VERSION ""

NS_ :

BS_:

BU_: PowertrainControlModule AtmosphericSensor SafetyRestraintSystem2 Aftertreatment_2_GasOutlet Aftertreatment_2_GasIntake DieselParticulateFilterControl Turbocharger SafetyRestraintSystem1 CabDisplay2 Aftertreatment_1_GasOutlet Aftertreatment_1_GasIntake OnBoardDataLogger OffBoardDiagnosticTool2 OffBoardDiagnosticTool1 FileServer ParkingBrakeController SeatController2 FanDriveController SteeringColumnUnit CommunicationUnitRadio CommunicationUnitSatellite CommunicationUnitCellular PropulsionBatteryCharger ChassisController2 ChassisController1 EngineValveControl AuxiliaryHeater2 AuxiliaryHeater1 ClutchUnit RampControl InformationSystem1 SuspensionSystemController2 OilSensor VehicleDynamicStability ExhaustEmissionController TransmissionDisplay2 TransmissionDisplay1 ClimateControl2 WaterPumpController RearAxleSteeringController LightingOperatorControl SeatController1 IgnitionController2 IgnitionController1 TirePressureController CabController2 CabController1 PneumaticSystemController SuspensionSystemController1 HydraulicPumpController EnduranceBrakingSystem RetarderExhaustEngine2 OnBoardDiagnosticUnit HeadwayController RetarderExhaustEngine1 CabDisplay1 ManagementComputer VirtualTerminal OffVehicleGateway PowerTakeOffFront HitchControl AuxiliaryValveControl BodyController TractorTrailerBridge1 StarterSystem ElectricalSystem VehicleSecurity VehicleNavigation AerodynamicControl ElectricalChargingSystem ClimateControl1 TripRecorder InstrumentCluster SuspensionDriveAxle2 SuspensionDriveAxle1 SuspensionSteerAxle SteeringController FuelSystem CruiseControl RetarderDriveline RetarderEngine BrakesDriveAxle2 BrakesDriveAxle1 BrakesSystemController BrakesSteerAxle AxleDrive2 AxleDrive1 AxleSteering PowerTakeOff ShiftConsoleSecondary ShiftConsolePrimary Transmission2 Transmission1 Engine2 Engine1

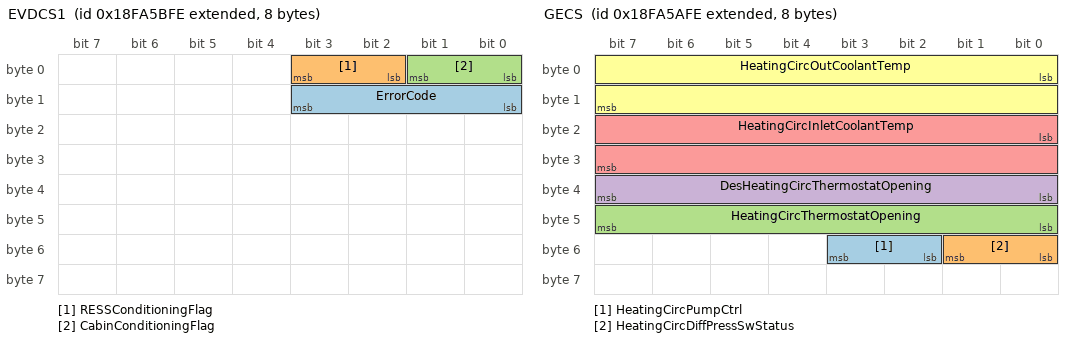
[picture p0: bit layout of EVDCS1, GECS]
BO_ 2566544382 EVDCS1: 8 Vector__XXX
 SG_ ErrorCode : 8|4@1+ (1,0) [0|15] "" Vector__XXX
 SG_ RESSConditioningFlag : 2|2@1+ (1,0) [0|3] "" Vector__XXX
 SG_ CabinConditioningFlag : 0|2@1+ (1,0) [0|3] "" Vector__XXX

BO_ 2566544126 GECS: 8 Vector__XXX
 SG_ HeatingCircPumpCtrl : 50|2@1+ (1,0) [0|3] "" Vector__XXX
 SG_ HeatingCircDiffPressSwStatus : 48|2@1+ (1,0) [0|3] "" Vector__XXX
 SG_ HeatingCircThermostatOpening : 40|8@1+ (0.4,0) [0|100] "%" Vector__XXX
 SG_ DesHeatingCircThermostatOpening : 32|8@1+ (0.4,0) [0|100] "%" Vector__XXX
 SG_ HeatingCircInletCoolantTemp : 16|16@1+ (0.03125,-273) [-273|1734.96875] "°C" Vector__XXX
 SG_ HeatingCircOutCoolantTemp : 0|16@1+ (0.03125,-273) [-273|1734.96875] "°C" Vector__XXX

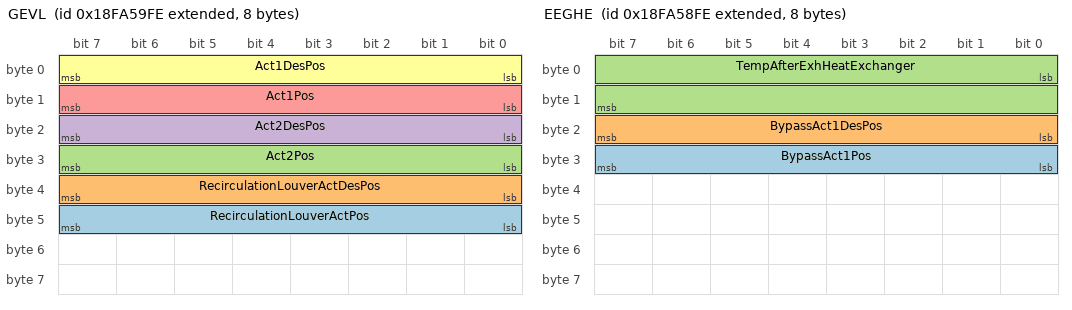
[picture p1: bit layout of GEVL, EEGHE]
BO_ 2566543870 GEVL: 8 Vector__XXX
 SG_ RecirculationLouverActPos : 40|8@1+ (0.4,0) [0|100] "%" Vector__XXX
 SG_ RecirculationLouverActDesPos : 32|8@1+ (0.4,0) [0|100] "%" Vector__XXX
 SG_ Act2Pos : 24|8@1+ (0.4,0) [0|100] "%" Vector__XXX
 SG_ Act2DesPos : 16|8@1+ (0.4,0) [0|100] "%" Vector__XXX
 SG_ Act1Pos : 8|8@1+ (0.4,0) [0|100] "%" Vector__XXX
 SG_ Act1DesPos : 0|8@1+ (0.4,0) [0|100] "%" Vector__XXX

BO_ 2566543614 EEGHE: 8 Vector__XXX
 SG_ BypassAct1Pos : 24|8@1+ (0.4,0) [0|100] "%" Vector__XXX
 SG_ BypassAct1DesPos : 16|8@1+ (0.4,0) [0|100] "%" Vector__XXX
 SG_ TempAfterExhHeatExchanger : 0|16@1+ (0.03125,-273) [-273|1734.96875] "°C" Vector__XXX

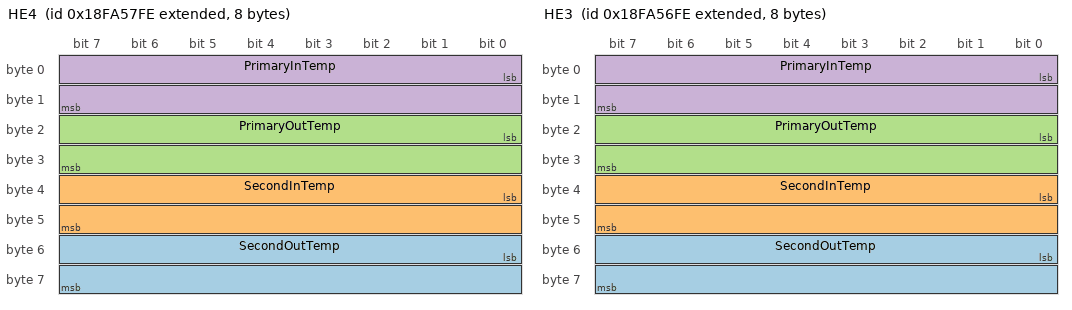
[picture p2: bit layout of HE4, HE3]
BO_ 2566543358 HE4: 8 Vector__XXX
 SG_ SecondOutTemp : 48|16@1+ (0.03125,-273) [-273|1734.96875] "°C" Vector__XXX
 SG_ SecondInTemp : 32|16@1+ (0.03125,-273) [-273|1734.96875] "°C" Vector__XXX
 SG_ PrimaryOutTemp : 16|16@1+ (0.03125,-273) [-273|1734.96875] "°C" Vector__XXX
 SG_ PrimaryInTemp : 0|16@1+ (0.03125,-273) [-273|1734.96875] "°C" Vector__XXX

BO_ 2566543102 HE3: 8 Vector__XXX
 SG_ SecondOutTemp : 48|16@1+ (0.03125,-273) [-273|1734.96875] "°C" Vector__XXX
 SG_ SecondInTemp : 32|16@1+ (0.03125,-273) [-273|1734.96875] "°C" Vector__XXX
 SG_ PrimaryOutTemp : 16|16@1+ (0.03125,-273) [-273|1734.96875] "°C" Vector__XXX
 SG_ PrimaryInTemp : 0|16@1+ (0.03125,-273) [-273|1734.96875] "°C" Vector__XXX

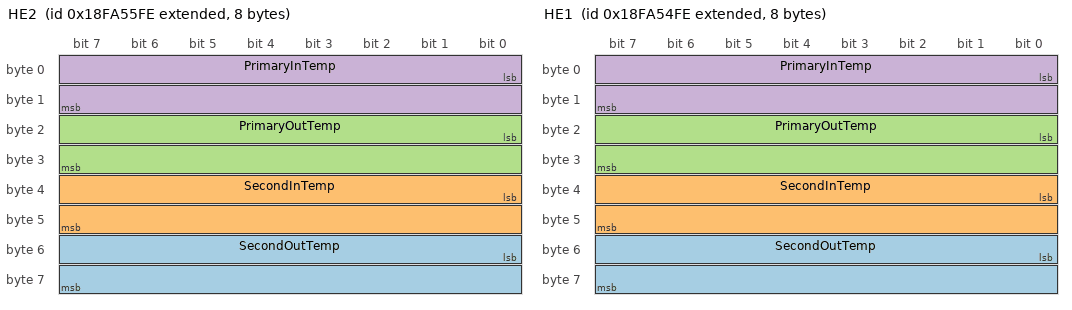
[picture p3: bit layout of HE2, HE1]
BO_ 2566542846 HE2: 8 Vector__XXX
 SG_ SecondOutTemp : 48|16@1+ (0.03125,-273) [-273|1734.96875] "°C" Vector__XXX
 SG_ SecondInTemp : 32|16@1+ (0.03125,-273) [-273|1734.96875] "°C" Vector__XXX
 SG_ PrimaryOutTemp : 16|16@1+ (0.03125,-273) [-273|1734.96875] "°C" Vector__XXX
 SG_ PrimaryInTemp : 0|16@1+ (0.03125,-273) [-273|1734.96875] "°C" Vector__XXX

BO_ 2566542590 HE1: 8 Vector__XXX
 SG_ SecondOutTemp : 48|16@1+ (0.03125,-273) [-273|1734.96875] "°C" Vector__XXX
 SG_ SecondInTemp : 32|16@1+ (0.03125,-273) [-273|1734.96875] "°C" Vector__XXX
 SG_ PrimaryOutTemp : 16|16@1+ (0.03125,-273) [-273|1734.96875] "°C" Vector__XXX
 SG_ PrimaryInTemp : 0|16@1+ (0.03125,-273) [-273|1734.96875] "°C" Vector__XXX

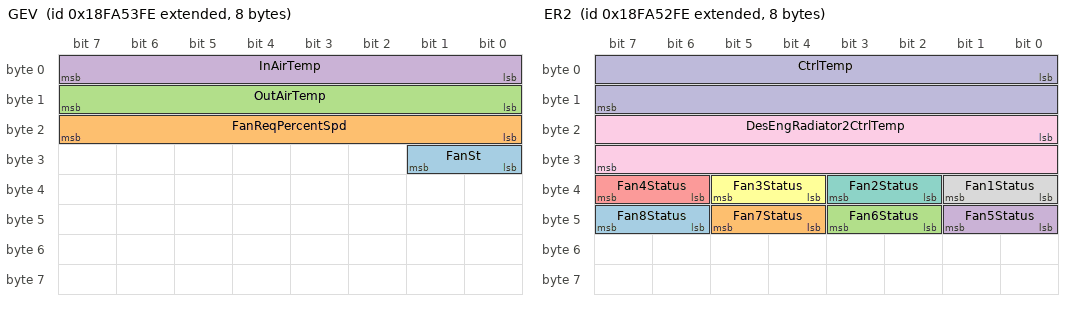
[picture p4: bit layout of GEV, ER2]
BO_ 2566542334 GEV: 8 Vector__XXX
 SG_ FanSt : 24|2@1+ (1,0) [0|3] "" Vector__XXX
 SG_ FanReqPercentSpd : 16|8@1+ (0.4,0) [0|100] "%" Vector__XXX
 SG_ OutAirTemp : 8|8@1+ (1,-40) [-40|210] "°C" Vector__XXX
 SG_ InAirTemp : 0|8@1+ (1,-40) [-40|210] "°C" Vector__XXX

BO_ 2566542078 ER2: 8 Vector__XXX
 SG_ Fan8Status : 46|2@1+ (1,0) [0|3] "" Vector__XXX
 SG_ Fan7Status : 44|2@1+ (1,0) [0|3] "" Vector__XXX
 SG_ Fan6Status : 42|2@1+ (1,0) [0|3] "" Vector__XXX
 SG_ Fan5Status : 40|2@1+ (1,0) [0|3] "" Vector__XXX
 SG_ Fan4Status : 38|2@1+ (1,0) [0|3] "" Vector__XXX
 SG_ Fan3Status : 36|2@1+ (1,0) [0|3] "" Vector__XXX
 SG_ Fan2Status : 34|2@1+ (1,0) [0|3] "" Vector__XXX
 SG_ Fan1Status : 32|2@1+ (1,0) [0|3] "" Vector__XXX
 SG_ DesEngRadiator2CtrlTemp : 16|16@1+ (0.03125,-273) [-273|1734.96875] "°C" Vector__XXX
 SG_ CtrlTemp : 0|16@1+ (0.03125,-273) [-273|1734.96875] "°C" Vector__XXX

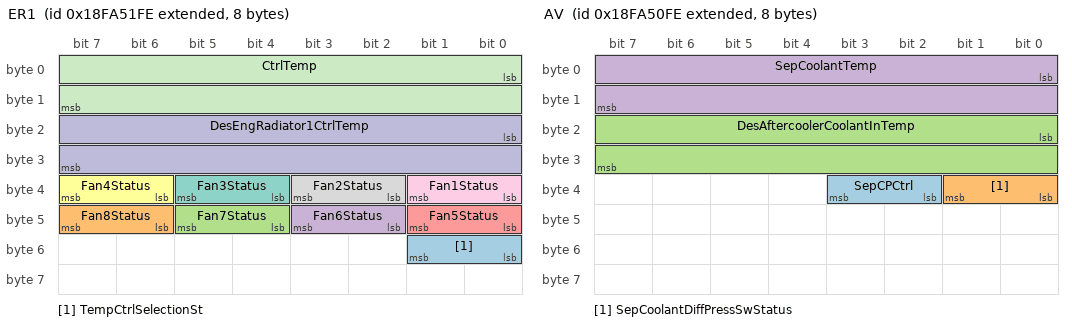
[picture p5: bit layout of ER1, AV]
BO_ 2566541822 ER1: 8 Vector__XXX
 SG_ TempCtrlSelectionSt : 48|2@1+ (1,0) [0|3] "" Vector__XXX
 SG_ Fan8Status : 46|2@1+ (1,0) [0|3] "" Vector__XXX
 SG_ Fan7Status : 44|2@1+ (1,0) [0|3] "" Vector__XXX
 SG_ Fan6Status : 42|2@1+ (1,0) [0|3] "" Vector__XXX
 SG_ Fan5Status : 40|2@1+ (1,0) [0|3] "" Vector__XXX
 SG_ Fan4Status : 38|2@1+ (1,0) [0|3] "" Vector__XXX
 SG_ Fan3Status : 36|2@1+ (1,0) [0|3] "" Vector__XXX
 SG_ Fan2Status : 34|2@1+ (1,0) [0|3] "" Vector__XXX
 SG_ Fan1Status : 32|2@1+ (1,0) [0|3] "" Vector__XXX
 SG_ DesEngRadiator1CtrlTemp : 16|16@1+ (0.03125,-273) [-273|1734.96875] "°C" Vector__XXX
 SG_ CtrlTemp : 0|16@1+ (0.03125,-273) [-273|1734.96875] "°C" Vector__XXX

BO_ 2566541566 AV: 8 Vector__XXX
 SG_ SepCPCtrl : 34|2@1+ (1,0) [0|3] "" Vector__XXX
 SG_ SepCoolantDiffPressSwStatus : 32|2@1+ (1,0) [0|3] "" Vector__XXX
 SG_ DesAftercoolerCoolantInTemp : 16|16@1+ (0.03125,-273) [-273|1734.96875] "°C" Vector__XXX
 SG_ SepCoolantTemp : 0|16@1+ (0.03125,-273) [-273|1734.96875] "°C" Vector__XXX

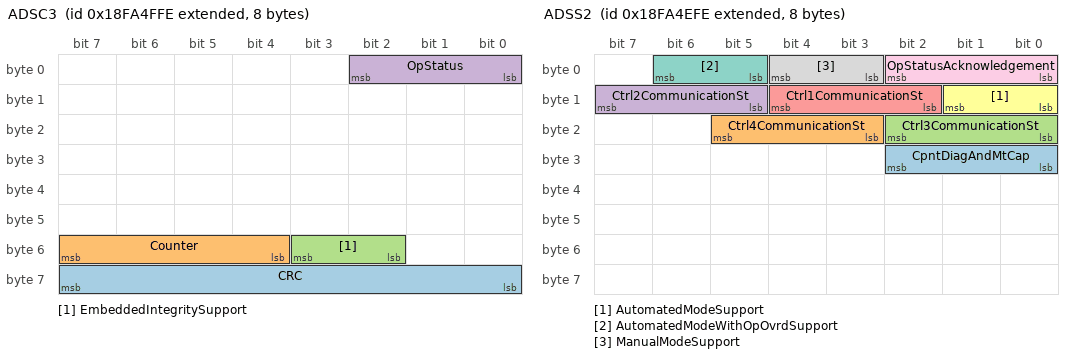
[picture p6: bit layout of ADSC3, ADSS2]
BO_ 2566541310 ADSC3: 8 Vector__XXX
 SG_ CRC : 56|8@1+ (1,0) [0|255] "" Vector__XXX
 SG_ Counter : 52|4@1+ (1,0) [0|15] "" Vector__XXX
 SG_ EmbeddedIntegritySupport : 50|2@1+ (1,0) [0|3] "" Vector__XXX
 SG_ OpStatus : 0|3@1+ (1,0) [0|7] "" Vector__XXX

BO_ 2566541054 ADSS2: 8 Vector__XXX
 SG_ CpntDiagAndMtCap : 24|3@1+ (1,0) [0|7] "" Vector__XXX
 SG_ Ctrl4CommunicationSt : 19|3@1+ (1,0) [0|7] "" Vector__XXX
 SG_ Ctrl3CommunicationSt : 16|3@1+ (1,0) [0|7] "" Vector__XXX
 SG_ Ctrl2CommunicationSt : 13|3@1+ (1,0) [0|7] "" Vector__XXX
 SG_ Ctrl1CommunicationSt : 10|3@1+ (1,0) [0|7] "" Vector__XXX
 SG_ AutomatedModeSupport : 8|2@1+ (1,0) [0|3] "" Vector__XXX
 SG_ AutomatedModeWithOpOvrdSupport : 5|2@1+ (1,0) [0|3] "" Vector__XXX
 SG_ ManualModeSupport : 3|2@1+ (1,0) [0|3] "" Vector__XXX
 SG_ OpStatusAcknowledgement : 0|3@1+ (1,0) [0|7] "" Vector__XXX

BO_ 2566540798 EVEI: 8 Vector__XXX
 SG_ TripDriveEnergyEconomy : 32|16@1+ (0.001953125,0) [0|125.498046875] "kWh/km" Vector__XXX
 SG_ TotalTripEnergyConsumed : 0|32@1+ (0.1,0) [0|421108121.5] "kWh" Vector__XXX

BO_ 2566540542 A1SCRDSI5: 8 Vector__XXX
 SG_ DEFDoser3Press : 16|16@1+ (0.1,-100) [-100|6325.5] "kPa" Vector__XXX
 SG_ DEFDoser2Press : 0|16@1+ (0.1,-100) [-100|6325.5] "kPa" Vector__XXX

BO_ 2566540286 A2SCRDSI5: 8 Vector__XXX
 SG_ DEFDoser3Press : 16|16@1+ (0.1,-100) [-100|6325.5] "kPa" Vector__XXX
 SG_ DEFDoser2Press : 0|16@1+ (0.1,-100) [-100|6325.5] "kPa" Vector__XXX

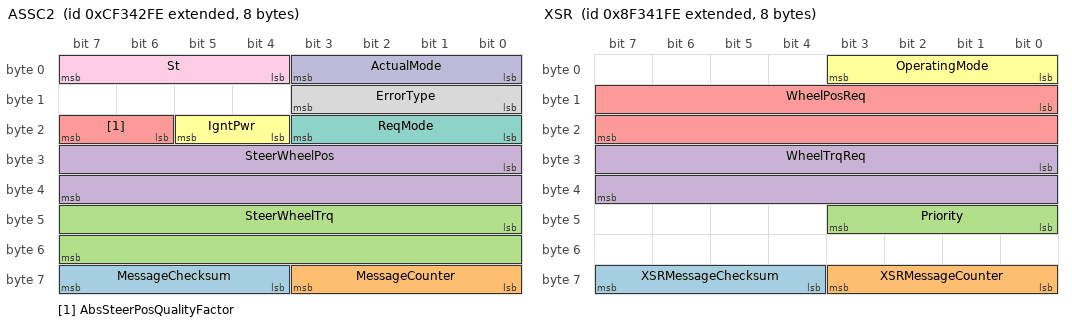
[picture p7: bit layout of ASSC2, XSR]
BO_ 2364752638 ASSC2: 8 Vector__XXX
 SG_ MessageChecksum : 60|4@1+ (1,0) [0|15] "" Vector__XXX
 SG_ MessageCounter : 56|4@1+ (1,0) [0|15] "" Vector__XXX
 SG_ SteerWheelTrq : 40|16@1+ (0.0009765625,-31) [-31|31.7490234375] "Nm" Vector__XXX
 SG_ SteerWheelPos : 24|16@1+ (0.0625,-2008) [-2008|2007.9375] "deg" Vector__XXX
 SG_ AbsSteerPosQualityFactor : 22|2@1+ (1,0) [0|3] "" Vector__XXX
 SG_ IgntPwr : 20|2@1+ (1,0) [0|3] "" Vector__XXX
 SG_ ReqMode : 16|4@1+ (1,0) [0|15] "" Vector__XXX
 SG_ ErrorType : 8|4@1+ (1,0) [0|15] "" Vector__XXX
 SG_ St : 4|4@1+ (1,0) [0|15] "" Vector__XXX
 SG_ ActualMode : 0|4@1+ (1,0) [0|15] "" Vector__XXX

BO_ 2297643518 XSR: 8 Vector__XXX
 SG_ XSRMessageChecksum : 60|4@1+ (1,0) [0|15] "" Vector__XXX
 SG_ XSRMessageCounter : 56|4@1+ (1,0) [0|15] "" Vector__XXX
 SG_ Priority : 40|4@1+ (1,0) [0|15] "" Vector__XXX
 SG_ WheelTrqReq : 24|16@1+ (0.0009765625,-31) [-31|31.7490234375] "Nm" Vector__XXX
 SG_ WheelPosReq : 8|16@1+ (0.0625,-2008) [-2008|2007.9375] "deg" Vector__XXX
 SG_ OperatingMode : 0|4@1+ (1,0) [0|15] "" Vector__XXX

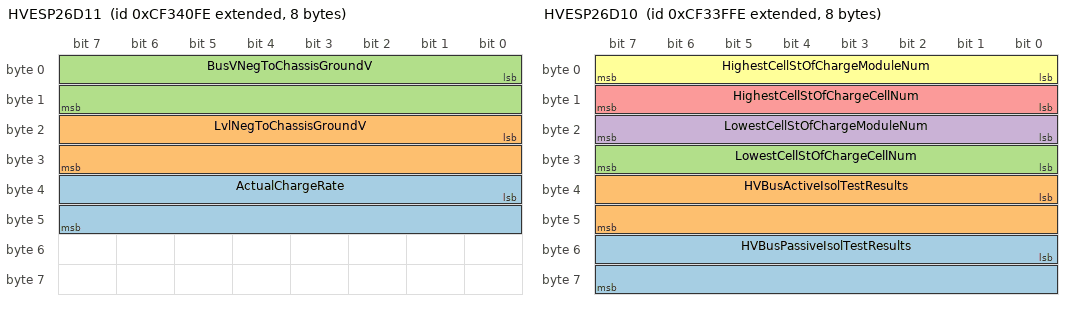
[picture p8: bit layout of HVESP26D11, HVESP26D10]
BO_ 2364752126 HVESP26D11: 8 Vector__XXX
 SG_ ActualChargeRate : 32|16@1+ (0.05,0) [0|3212.75] "kW" Vector__XXX
 SG_ LvlNegToChassisGroundV : 16|16@1+ (0.05,0) [0|3212.75] "V" Vector__XXX
 SG_ BusVNegToChassisGroundV : 0|16@1+ (0.05,0) [0|3212.75] "V" Vector__XXX

BO_ 2364751870 HVESP26D10: 8 Vector__XXX
 SG_ HVBusPassiveIsolTestResults : 48|16@1+ (0.1,0) [0|6425.5] "Ohm/V" Vector__XXX
 SG_ HVBusActiveIsolTestResults : 32|16@1+ (0.1,0) [0|6425.5] "Ohm/V" Vector__XXX
 SG_ LowestCellStOfChargeCellNum : 24|8@1+ (1,0) [0|250] "" Vector__XXX
 SG_ LowestCellStOfChargeModuleNum : 16|8@1+ (1,0) [0|250] "" Vector__XXX
 SG_ HighestCellStOfChargeCellNum : 8|8@1+ (1,0) [0|250] "" Vector__XXX
 SG_ HighestCellStOfChargeModuleNum : 0|8@1+ (1,0) [0|250] "" Vector__XXX

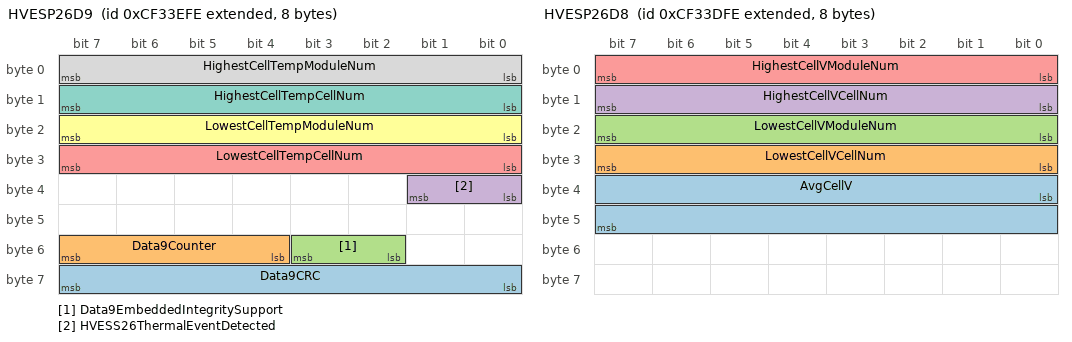
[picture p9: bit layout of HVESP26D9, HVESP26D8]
BO_ 2364751614 HVESP26D9: 8 Vector__XXX
 SG_ Data9CRC : 56|8@1+ (1,0) [0|255] "" Vector__XXX
 SG_ Data9Counter : 52|4@1+ (1,0) [0|15] "" Vector__XXX
 SG_ Data9EmbeddedIntegritySupport : 50|2@1+ (1,0) [0|3] "" Vector__XXX
 SG_ HVESS26ThermalEventDetected : 32|2@1+ (1,0) [0|3] "" Vector__XXX
 SG_ LowestCellTempCellNum : 24|8@1+ (1,0) [0|250] "" Vector__XXX
 SG_ LowestCellTempModuleNum : 16|8@1+ (1,0) [0|250] "" Vector__XXX
 SG_ HighestCellTempCellNum : 8|8@1+ (1,0) [0|250] "" Vector__XXX
 SG_ HighestCellTempModuleNum : 0|8@1+ (1,0) [0|250] "" Vector__XXX

BO_ 2364751358 HVESP26D8: 8 Vector__XXX
 SG_ AvgCellV : 32|16@1+ (0.001,0) [0|64.255] "V" Vector__XXX
 SG_ LowestCellVCellNum : 24|8@1+ (1,0) [0|250] "" Vector__XXX
 SG_ LowestCellVModuleNum : 16|8@1+ (1,0) [0|250] "" Vector__XXX
 SG_ HighestCellVCellNum : 8|8@1+ (1,0) [0|250] "" Vector__XXX
 SG_ HighestCellVModuleNum : 0|8@1+ (1,0) [0|250] "" Vector__XXX

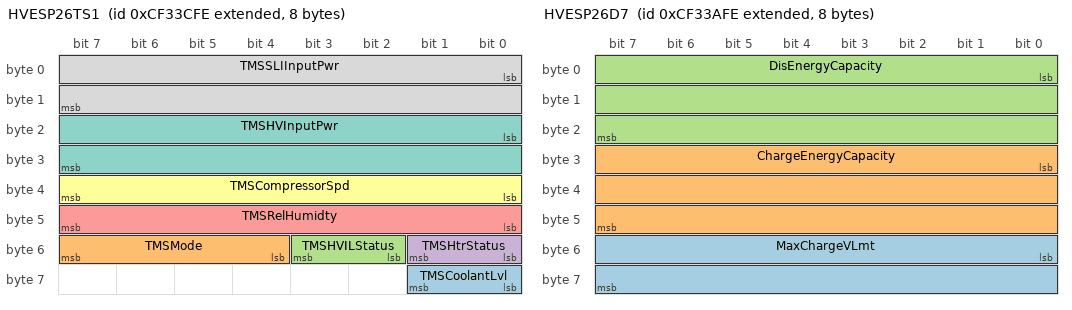
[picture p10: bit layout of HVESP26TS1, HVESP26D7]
BO_ 2364751102 HVESP26TS1: 8 Vector__XXX
 SG_ TMSCoolantLvl : 56|2@1+ (1,0) [0|3] "" Vector__XXX
 SG_ TMSMode : 52|4@1+ (1,0) [0|15] "" Vector__XXX
 SG_ TMSHVILStatus : 50|2@1+ (1,0) [0|3] "" Vector__XXX
 SG_ TMSHtrStatus : 48|2@1+ (1,0) [0|3] "" Vector__XXX
 SG_ TMSRelHumidty : 40|8@1+ (0.4,0) [0|100] "%" Vector__XXX
 SG_ TMSCompressorSpd : 32|8@1+ (32,0) [0|8000] "rpm" Vector__XXX
 SG_ TMSHVInputPwr : 16|16@1+ (0.5,0) [0|32127.5] "W" Vector__XXX
 SG_ TMSSLIInputPwr : 0|16@1+ (0.5,0) [0|32127.5] "W" Vector__XXX

BO_ 2364750846 HVESP26MS1: 8 Vector__XXX
 SG_ Module32OperationalStatus : 62|2@1+ (1,0) [0|3] "" Vector__XXX
 SG_ Module31OperationalStatus : 60|2@1+ (1,0) [0|3] "" Vector__XXX
 SG_ Module30OperationalStatus : 58|2@1+ (1,0) [0|3] "" Vector__XXX
 SG_ Module29OperationalStatus : 56|2@1+ (1,0) [0|3] "" Vector__XXX
 SG_ Module28OperationalStatus : 54|2@1+ (1,0) [0|3] "" Vector__XXX
 SG_ Module27OperationalStatus : 52|2@1+ (1,0) [0|3] "" Vector__XXX
 SG_ Module26OperationalStatus : 50|2@1+ (1,0) [0|3] "" Vector__XXX
 SG_ Module25OperationalStatus : 48|2@1+ (1,0) [0|3] "" Vector__XXX
 SG_ Module24OperationalStatus : 46|2@1+ (1,0) [0|3] "" Vector__XXX
 SG_ Module23OperationalStatus : 44|2@1+ (1,0) [0|3] "" Vector__XXX
 SG_ Module22OperationalStatus : 42|2@1+ (1,0) [0|3] "" Vector__XXX
 SG_ Module21OperationalStatus : 40|2@1+ (1,0) [0|3] "" Vector__XXX
 SG_ Module20OperationalStatus : 38|2@1+ (1,0) [0|3] "" Vector__XXX
 SG_ Module19OperationalStatus : 36|2@1+ (1,0) [0|3] "" Vector__XXX
 SG_ Module18OperationalStatus : 34|2@1+ (1,0) [0|3] "" Vector__XXX
 SG_ Module17OperationalStatus : 32|2@1+ (1,0) [0|3] "" Vector__XXX
 SG_ Module16OperationalStatus : 30|2@1+ (1,0) [0|3] "" Vector__XXX
 SG_ Module15OperationalStatus : 28|2@1+ (1,0) [0|3] "" Vector__XXX
 SG_ Module14OperationalStatus : 26|2@1+ (1,0) [0|3] "" Vector__XXX
 SG_ Module13OperationalStatus : 24|2@1+ (1,0) [0|3] "" Vector__XXX
 SG_ Module12OperationalStatus : 22|2@1+ (1,0) [0|3] "" Vector__XXX
 SG_ Module11OperationalStatus : 20|2@1+ (1,0) [0|3] "" Vector__XXX
 SG_ Module10OperationalStatus : 18|2@1+ (1,0) [0|3] "" Vector__XXX
 SG_ Module9OperationalStatus : 16|2@1+ (1,0) [0|3] "" Vector__XXX
 SG_ Module8OperationalStatus : 14|2@1+ (1,0) [0|3] "" Vector__XXX
 SG_ Module7OperationalStatus : 12|2@1+ (1,0) [0|3] "" Vector__XXX
 SG_ Module6OperationalStatus : 10|2@1+ (1,0) [0|3] "" Vector__XXX
 SG_ Module5OperationalStatus : 8|2@1+ (1,0) [0|3] "" Vector__XXX
 SG_ Module4OperationalStatus : 6|2@1+ (1,0) [0|3] "" Vector__XXX
 SG_ Module3OperationalStatus : 4|2@1+ (1,0) [0|3] "" Vector__XXX
 SG_ Module2OperationalStatus : 2|2@1+ (1,0) [0|3] "" Vector__XXX
 SG_ Module1OperationalStatus : 0|2@1+ (1,0) [0|3] "" Vector__XXX

BO_ 2364750590 HVESP26D7: 8 Vector__XXX
 SG_ MaxChargeVLmt : 48|16@1+ (0.05,0) [0|3212.75] "V" Vector__XXX
 SG_ ChargeEnergyCapacity : 24|24@1+ (0.001,0) [0|16449.535] "kWh" Vector__XXX
 SG_ DisEnergyCapacity : 0|24@1+ (0.001,0) [0|16449.535] "kWh" Vector__XXX

BO_ 2364750334 HVESP26S1: 8 Vector__XXX
 SG_ Status1CRC : 56|8@1+ (1,0) [0|255] "" Vector__XXX
 SG_ Status1Counter : 52|4@1+ (1,0) [0|15] "" Vector__XXX
 SG_ OperationalStatus : 44|4@1+ (1,0) [0|15] "" Vector__XXX
 SG_ HVBusConnectionStatus : 40|4@1+ (1,0) [0|15] "" Vector__XXX
 SG_ InternalChargerStatus : 32|2@1+ (1,0) [0|3] "" Vector__XXX
 SG_ CellBalancingActive : 30|2@1+ (1,0) [0|3] "" Vector__XXX
 SG_ CellBalanceStatus : 28|2@1+ (1,0) [0|3] "" Vector__XXX
 SG_ StOfChargeStatus : 24|4@1+ (1,0) [0|15] "" Vector__XXX
 SG_ InertiaSwStatus : 22|2@1+ (1,0) [0|3] "" Vector__XXX
 SG_ HVILStatus : 20|2@1+ (1,0) [0|3] "" Vector__XXX
 SG_ HVBusPassiveIsolTestStatus : 16|4@1+ (1,0) [0|15] "" Vector__XXX
 SG_ HVBusActiveIsolTestStatus : 12|4@1+ (1,0) [0|15] "" Vector__XXX
 SG_ CenterOfPackContactorSt : 10|2@1+ (1,0) [0|3] "" Vector__XXX
 SG_ HVBusPreChargeRelaySt : 8|2@1+ (1,0) [0|3] "" Vector__XXX
 SG_ HVBusDisconnectForewarning : 4|4@1+ (1,0) [0|15] "" Vector__XXX
 SG_ HVBusContactorSt17448 : 2|2@1+ (1,0) [0|3] "" Vector__XXX
 SG_ HVBusContactorSt : 0|2@1+ (1,0) [0|3] "" Vector__XXX

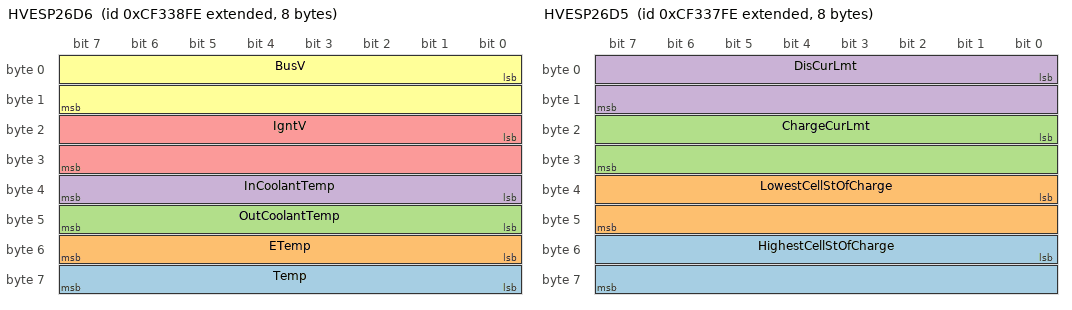
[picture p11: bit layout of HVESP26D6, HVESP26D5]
BO_ 2364750078 HVESP26D6: 8 Vector__XXX
 SG_ Temp : 56|8@1+ (1,-40) [-40|210] "°C" Vector__XXX
 SG_ ETemp : 48|8@1+ (1,-40) [-40|210] "°C" Vector__XXX
 SG_ OutCoolantTemp : 40|8@1+ (1,-40) [-40|210] "°C" Vector__XXX
 SG_ InCoolantTemp : 32|8@1+ (1,-40) [-40|210] "°C" Vector__XXX
 SG_ IgntV : 16|16@1+ (0.01,0) [0|642.55] "V" Vector__XXX
 SG_ BusV : 0|16@1+ (0.05,0) [0|3212.75] "V" Vector__XXX

BO_ 2364749822 HVESP26D5: 8 Vector__XXX
 SG_ HighestCellStOfCharge : 48|16@1+ (0.0015625,0) [0|100.3984375] "%" Vector__XXX
 SG_ LowestCellStOfCharge : 32|16@1+ (0.0015625,0) [0|100.3984375] "%" Vector__XXX
 SG_ ChargeCurLmt : 16|16@1+ (0.05,-1600) [0|1612.75] "A" Vector__XXX
 SG_ DisCurLmt : 0|16@1+ (0.05,-1600) [-1600|0] "A" Vector__XXX

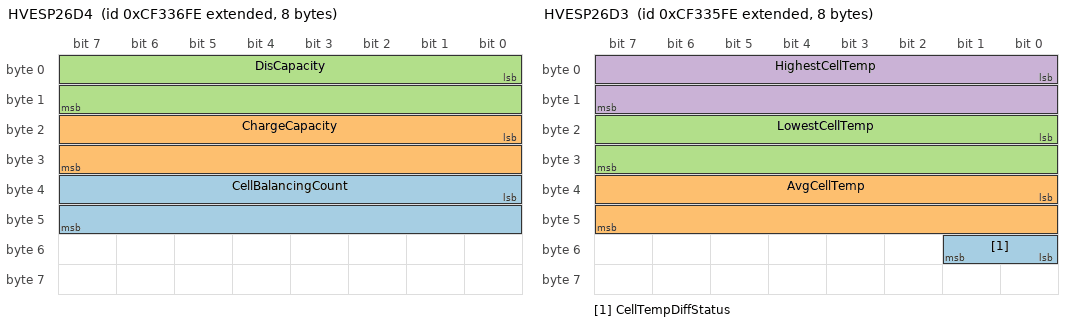
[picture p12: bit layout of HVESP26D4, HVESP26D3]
BO_ 2364749566 HVESP26D4: 8 Vector__XXX
 SG_ CellBalancingCount : 32|16@1+ (1,0) [0|64255] "" Vector__XXX
 SG_ ChargeCapacity : 16|16@1+ (0.01,0) [0|642.55] "Ah" Vector__XXX
 SG_ DisCapacity : 0|16@1+ (0.01,0) [0|642.55] "Ah" Vector__XXX

BO_ 2364749310 HVESP26D3: 8 Vector__XXX
 SG_ CellTempDiffStatus : 48|2@1+ (1,0) [0|3] "" Vector__XXX
 SG_ AvgCellTemp : 32|16@1+ (0.03125,-273) [-273|1734.96875] "°C" Vector__XXX
 SG_ LowestCellTemp : 16|16@1+ (0.03125,-273) [-273|1734.96875] "°C" Vector__XXX
 SG_ HighestCellTemp : 0|16@1+ (0.03125,-273) [-273|1734.96875] "°C" Vector__XXX

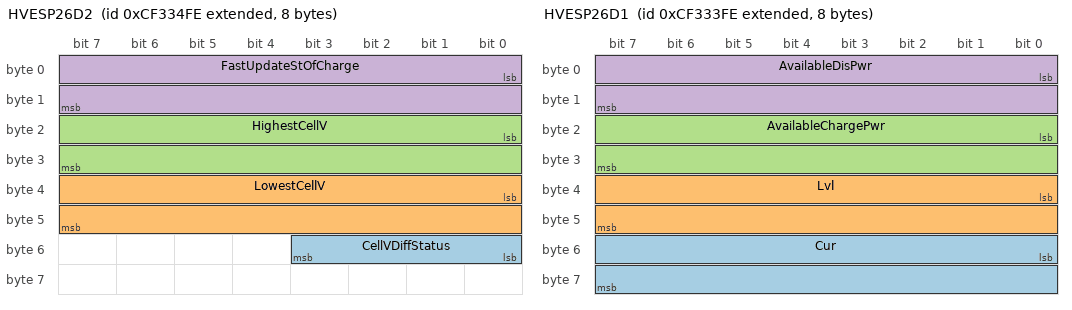
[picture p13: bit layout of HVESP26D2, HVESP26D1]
BO_ 2364749054 HVESP26D2: 8 Vector__XXX
 SG_ CellVDiffStatus : 48|4@1+ (1,0) [0|15] "" Vector__XXX
 SG_ LowestCellV : 32|16@1+ (0.001,0) [0|64.255] "V" Vector__XXX
 SG_ HighestCellV : 16|16@1+ (0.001,0) [0|64.255] "V" Vector__XXX
 SG_ FastUpdateStOfCharge : 0|16@1+ (0.0015625,0) [0|100.3984375] "%" Vector__XXX

BO_ 2364748798 HVESP26D1: 8 Vector__XXX
 SG_ Cur : 48|16@1+ (0.05,-1600) [-1600|1612.75] "A" Vector__XXX
 SG_ Lvl : 32|16@1+ (0.05,0) [0|3212.75] "V" Vector__XXX
 SG_ AvailableChargePwr : 16|16@1+ (0.05,0) [0|3212.75] "kW" Vector__XXX
 SG_ AvailableDisPwr : 0|16@1+ (0.05,0) [0|3212.75] "kW" Vector__XXX

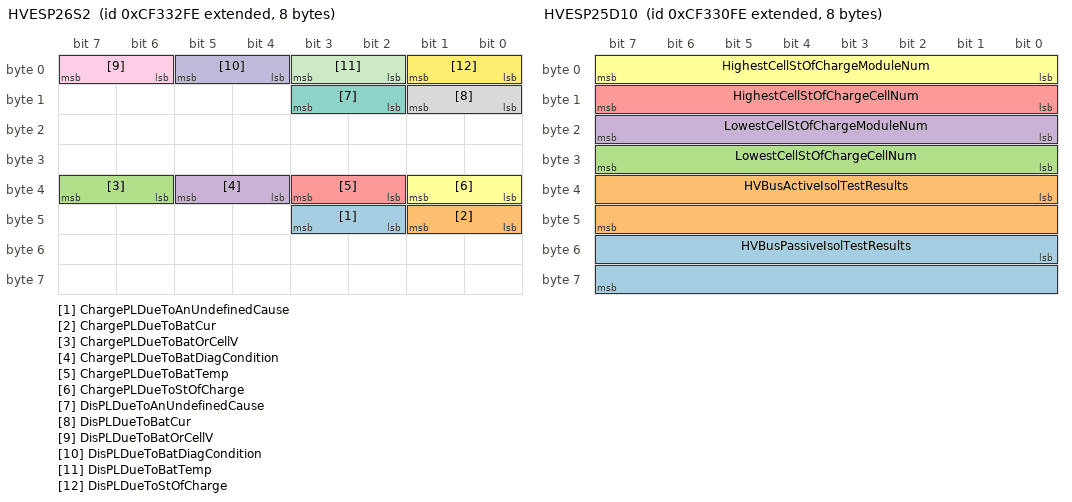
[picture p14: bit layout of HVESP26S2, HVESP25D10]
BO_ 2364748542 HVESP26S2: 8 Vector__XXX
 SG_ ChargePLDueToAnUndefinedCause : 42|2@1+ (1,0) [0|3] "" Vector__XXX
 SG_ ChargePLDueToBatCur : 40|2@1+ (1,0) [0|3] "" Vector__XXX
 SG_ ChargePLDueToBatOrCellV : 38|2@1+ (1,0) [0|3] "" Vector__XXX
 SG_ ChargePLDueToBatDiagCondition : 36|2@1+ (1,0) [0|3] "" Vector__XXX
 SG_ ChargePLDueToBatTemp : 34|2@1+ (1,0) [0|3] "" Vector__XXX
 SG_ ChargePLDueToStOfCharge : 32|2@1+ (1,0) [0|3] "" Vector__XXX
 SG_ DisPLDueToAnUndefinedCause : 10|2@1+ (1,0) [0|3] "" Vector__XXX
 SG_ DisPLDueToBatCur : 8|2@1+ (1,0) [0|3] "" Vector__XXX
 SG_ DisPLDueToBatOrCellV : 6|2@1+ (1,0) [0|3] "" Vector__XXX
 SG_ DisPLDueToBatDiagCondition : 4|2@1+ (1,0) [0|3] "" Vector__XXX
 SG_ DisPLDueToBatTemp : 2|2@1+ (1,0) [0|3] "" Vector__XXX
 SG_ DisPLDueToStOfCharge : 0|2@1+ (1,0) [0|3] "" Vector__XXX

BO_ 2364748286 HVESP25D11: 8 Vector__XXX
 SG_ ActualChargeRate : 32|16@1+ (0.05,0) [0|3212.75] "kW" Vector__XXX
 SG_ LvlNegToChassisGroundV : 16|16@1+ (0.05,0) [0|3212.75] "V" Vector__XXX
 SG_ BusVNegToChassisGroundV : 0|16@1+ (0.05,0) [0|3212.75] "V" Vector__XXX

BO_ 2364748030 HVESP25D10: 8 Vector__XXX
 SG_ HVBusPassiveIsolTestResults : 48|16@1+ (0.1,0) [0|6425.5] "Ohm/V" Vector__XXX
 SG_ HVBusActiveIsolTestResults : 32|16@1+ (0.1,0) [0|6425.5] "Ohm/V" Vector__XXX
 SG_ LowestCellStOfChargeCellNum : 24|8@1+ (1,0) [0|250] "" Vector__XXX
 SG_ LowestCellStOfChargeModuleNum : 16|8@1+ (1,0) [0|250] "" Vector__XXX
 SG_ HighestCellStOfChargeCellNum : 8|8@1+ (1,0) [0|250] "" Vector__XXX
 SG_ HighestCellStOfChargeModuleNum : 0|8@1+ (1,0) [0|250] "" Vector__XXX

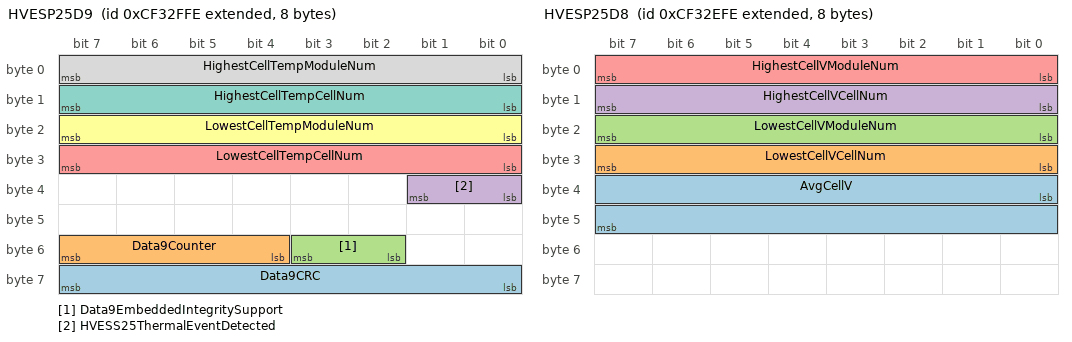
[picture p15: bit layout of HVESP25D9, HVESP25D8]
BO_ 2364747774 HVESP25D9: 8 Vector__XXX
 SG_ Data9CRC : 56|8@1+ (1,0) [0|255] "" Vector__XXX
 SG_ Data9Counter : 52|4@1+ (1,0) [0|15] "" Vector__XXX
 SG_ Data9EmbeddedIntegritySupport : 50|2@1+ (1,0) [0|3] "" Vector__XXX
 SG_ HVESS25ThermalEventDetected : 32|2@1+ (1,0) [0|3] "" Vector__XXX
 SG_ LowestCellTempCellNum : 24|8@1+ (1,0) [0|250] "" Vector__XXX
 SG_ LowestCellTempModuleNum : 16|8@1+ (1,0) [0|250] "" Vector__XXX
 SG_ HighestCellTempCellNum : 8|8@1+ (1,0) [0|250] "" Vector__XXX
 SG_ HighestCellTempModuleNum : 0|8@1+ (1,0) [0|250] "" Vector__XXX

BO_ 2364747518 HVESP25D8: 8 Vector__XXX
 SG_ AvgCellV : 32|16@1+ (0.001,0) [0|64.255] "V" Vector__XXX
 SG_ LowestCellVCellNum : 24|8@1+ (1,0) [0|250] "" Vector__XXX
 SG_ LowestCellVModuleNum : 16|8@1+ (1,0) [0|250] "" Vector__XXX
 SG_ HighestCellVCellNum : 8|8@1+ (1,0) [0|250] "" Vector__XXX
 SG_ HighestCellVModuleNum : 0|8@1+ (1,0) [0|250] "" Vector__XXX

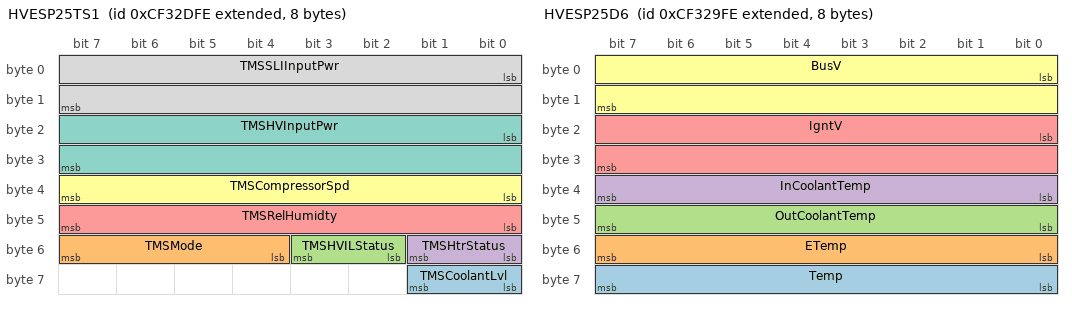
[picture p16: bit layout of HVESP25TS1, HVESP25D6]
BO_ 2364747262 HVESP25TS1: 8 Vector__XXX
 SG_ TMSCoolantLvl : 56|2@1+ (1,0) [0|3] "" Vector__XXX
 SG_ TMSMode : 52|4@1+ (1,0) [0|15] "" Vector__XXX
 SG_ TMSHVILStatus : 50|2@1+ (1,0) [0|3] "" Vector__XXX
 SG_ TMSHtrStatus : 48|2@1+ (1,0) [0|3] "" Vector__XXX
 SG_ TMSRelHumidty : 40|8@1+ (0.4,0) [0|100] "%" Vector__XXX
 SG_ TMSCompressorSpd : 32|8@1+ (32,0) [0|8000] "rpm" Vector__XXX
 SG_ TMSHVInputPwr : 16|16@1+ (0.5,0) [0|32127.5] "W" Vector__XXX
 SG_ TMSSLIInputPwr : 0|16@1+ (0.5,0) [0|32127.5] "W" Vector__XXX

BO_ 2364747006 HVESP25MS1: 8 Vector__XXX
 SG_ Module32OperationalStatus : 62|2@1+ (1,0) [0|3] "" Vector__XXX
 SG_ Module31OperationalStatus : 60|2@1+ (1,0) [0|3] "" Vector__XXX
 SG_ Module30OperationalStatus : 58|2@1+ (1,0) [0|3] "" Vector__XXX
 SG_ Module29OperationalStatus : 56|2@1+ (1,0) [0|3] "" Vector__XXX
 SG_ Module28OperationalStatus : 54|2@1+ (1,0) [0|3] "" Vector__XXX
 SG_ Module27OperationalStatus : 52|2@1+ (1,0) [0|3] "" Vector__XXX
 SG_ Module26OperationalStatus : 50|2@1+ (1,0) [0|3] "" Vector__XXX
 SG_ Module25OperationalStatus : 48|2@1+ (1,0) [0|3] "" Vector__XXX
 SG_ Module24OperationalStatus : 46|2@1+ (1,0) [0|3] "" Vector__XXX
 SG_ Module23OperationalStatus : 44|2@1+ (1,0) [0|3] "" Vector__XXX
 SG_ Module22OperationalStatus : 42|2@1+ (1,0) [0|3] "" Vector__XXX
 SG_ Module21OperationalStatus : 40|2@1+ (1,0) [0|3] "" Vector__XXX
 SG_ Module20OperationalStatus : 38|2@1+ (1,0) [0|3] "" Vector__XXX
 SG_ Module19OperationalStatus : 36|2@1+ (1,0) [0|3] "" Vector__XXX
 SG_ Module18OperationalStatus : 34|2@1+ (1,0) [0|3] "" Vector__XXX
 SG_ Module17OperationalStatus : 32|2@1+ (1,0) [0|3] "" Vector__XXX
 SG_ Module16OperationalStatus : 30|2@1+ (1,0) [0|3] "" Vector__XXX
 SG_ Module15OperationalStatus : 28|2@1+ (1,0) [0|3] "" Vector__XXX
 SG_ Module14OperationalStatus : 26|2@1+ (1,0) [0|3] "" Vector__XXX
 SG_ Module13OperationalStatus : 24|2@1+ (1,0) [0|3] "" Vector__XXX
 SG_ Module12OperationalStatus : 22|2@1+ (1,0) [0|3] "" Vector__XXX
 SG_ Module11OperationalStatus : 20|2@1+ (1,0) [0|3] "" Vector__XXX
 SG_ Module10OperationalStatus : 18|2@1+ (1,0) [0|3] "" Vector__XXX
 SG_ Module9OperationalStatus : 16|2@1+ (1,0) [0|3] "" Vector__XXX
 SG_ Module8OperationalStatus : 14|2@1+ (1,0) [0|3] "" Vector__XXX
 SG_ Module7OperationalStatus : 12|2@1+ (1,0) [0|3] "" Vector__XXX
 SG_ Module6OperationalStatus : 10|2@1+ (1,0) [0|3] "" Vector__XXX
 SG_ Module5OperationalStatus : 8|2@1+ (1,0) [0|3] "" Vector__XXX
 SG_ Module4OperationalStatus : 6|2@1+ (1,0) [0|3] "" Vector__XXX
 SG_ Module3OperationalStatus : 4|2@1+ (1,0) [0|3] "" Vector__XXX
 SG_ Module2OperationalStatus : 2|2@1+ (1,0) [0|3] "" Vector__XXX
 SG_ Module1OperationalStatus : 0|2@1+ (1,0) [0|3] "" Vector__XXX

BO_ 2364746750 HVESP25D7: 8 Vector__XXX
 SG_ MaxChargeVLmt : 48|16@1+ (0.05,0) [0|3212.75] "V" Vector__XXX
 SG_ ChargeEnergyCapacity : 24|24@1+ (0.001,0) [0|16449.535] "kWh" Vector__XXX
 SG_ DisEnergyCapacity : 0|24@1+ (0.001,0) [0|16449.535] "kWh" Vector__XXX

BO_ 2364746494 HVESP25S1: 8 Vector__XXX
 SG_ Status1CRC : 56|8@1+ (1,0) [0|255] "" Vector__XXX
 SG_ Status1Counter : 52|4@1+ (1,0) [0|15] "" Vector__XXX
 SG_ OperationalStatus : 44|4@1+ (1,0) [0|15] "" Vector__XXX
 SG_ HVBusConnectionStatus : 40|4@1+ (1,0) [0|15] "" Vector__XXX
 SG_ InternalChargerStatus : 32|2@1+ (1,0) [0|3] "" Vector__XXX
 SG_ CellBalancingActive : 30|2@1+ (1,0) [0|3] "" Vector__XXX
 SG_ CellBalanceStatus : 28|2@1+ (1,0) [0|3] "" Vector__XXX
 SG_ StOfChargeStatus : 24|4@1+ (1,0) [0|15] "" Vector__XXX
 SG_ InertiaSwStatus : 22|2@1+ (1,0) [0|3] "" Vector__XXX
 SG_ HVILStatus : 20|2@1+ (1,0) [0|3] "" Vector__XXX
 SG_ HVBusPassiveIsolTestStatus : 16|4@1+ (1,0) [0|15] "" Vector__XXX
 SG_ HVBusActiveIsolTestStatus : 12|4@1+ (1,0) [0|15] "" Vector__XXX
 SG_ CenterOfPackContactorSt : 10|2@1+ (1,0) [0|3] "" Vector__XXX
 SG_ HVBusPreChargeRelaySt : 8|2@1+ (1,0) [0|3] "" Vector__XXX
 SG_ HVBusDisconnectForewarning : 4|4@1+ (1,0) [0|15] "" Vector__XXX
 SG_ HVBusContactorSt17306 : 2|2@1+ (1,0) [0|3] "" Vector__XXX
 SG_ HVBusContactorSt : 0|2@1+ (1,0) [0|3] "" Vector__XXX

BO_ 2364746238 HVESP25D6: 8 Vector__XXX
 SG_ Temp : 56|8@1+ (1,-40) [-40|210] "°C" Vector__XXX
 SG_ ETemp : 48|8@1+ (1,-40) [-40|210] "°C" Vector__XXX
 SG_ OutCoolantTemp : 40|8@1+ (1,-40) [-40|210] "°C" Vector__XXX
 SG_ InCoolantTemp : 32|8@1+ (1,-40) [-40|210] "°C" Vector__XXX
 SG_ IgntV : 16|16@1+ (0.01,0) [0|642.55] "V" Vector__XXX
 SG_ BusV : 0|16@1+ (0.05,0) [0|3212.75] "V" Vector__XXX

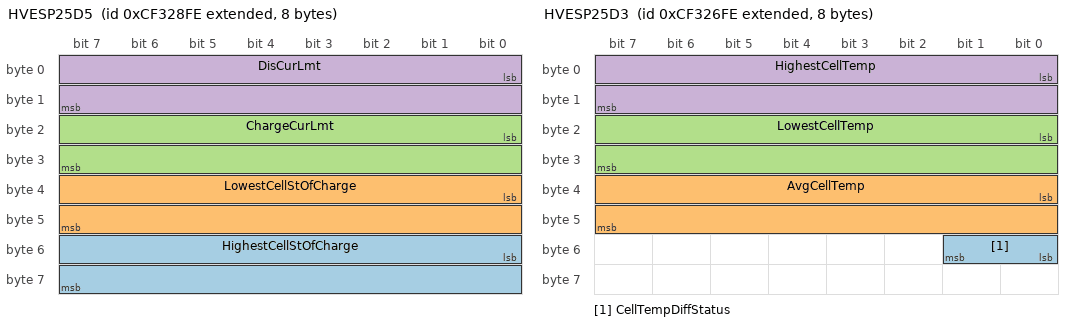
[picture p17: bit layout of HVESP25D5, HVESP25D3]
BO_ 2364745982 HVESP25D5: 8 Vector__XXX
 SG_ HighestCellStOfCharge : 48|16@1+ (0.0015625,0) [0|100.3984375] "%" Vector__XXX
 SG_ LowestCellStOfCharge : 32|16@1+ (0.0015625,0) [0|100.3984375] "%" Vector__XXX
 SG_ ChargeCurLmt : 16|16@1+ (0.05,-1600) [0|1612.75] "A" Vector__XXX
 SG_ DisCurLmt : 0|16@1+ (0.05,-1600) [-1600|0] "A" Vector__XXX

BO_ 2364745726 HVESP25D4: 8 Vector__XXX
 SG_ CellBalancingCount : 32|16@1+ (1,0) [0|64255] "" Vector__XXX
 SG_ ChargeCapacity : 16|16@1+ (0.01,0) [0|642.55] "Ah" Vector__XXX
 SG_ DisCapacity : 0|16@1+ (0.01,0) [0|642.55] "Ah" Vector__XXX

BO_ 2364745470 HVESP25D3: 8 Vector__XXX
 SG_ CellTempDiffStatus : 48|2@1+ (1,0) [0|3] "" Vector__XXX
 SG_ AvgCellTemp : 32|16@1+ (0.03125,-273) [-273|1734.96875] "°C" Vector__XXX
 SG_ LowestCellTemp : 16|16@1+ (0.03125,-273) [-273|1734.96875] "°C" Vector__XXX
 SG_ HighestCellTemp : 0|16@1+ (0.03125,-273) [-273|1734.96875] "°C" Vector__XXX

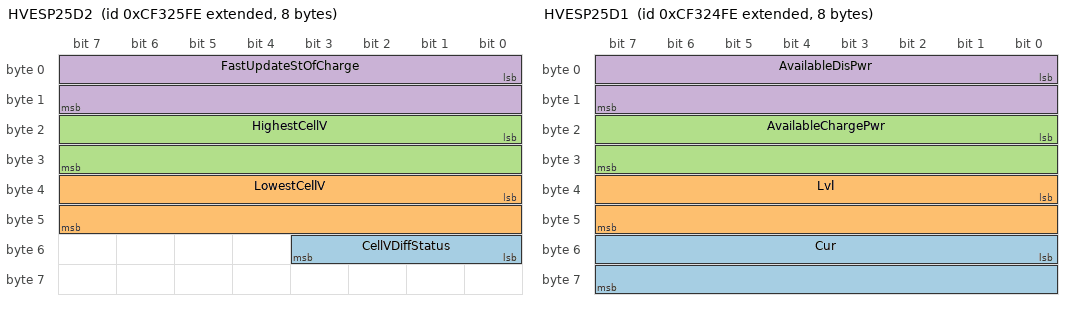
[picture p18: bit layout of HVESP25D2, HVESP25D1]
BO_ 2364745214 HVESP25D2: 8 Vector__XXX
 SG_ CellVDiffStatus : 48|4@1+ (1,0) [0|15] "" Vector__XXX
 SG_ LowestCellV : 32|16@1+ (0.001,0) [0|64.255] "V" Vector__XXX
 SG_ HighestCellV : 16|16@1+ (0.001,0) [0|64.255] "V" Vector__XXX
 SG_ FastUpdateStOfCharge : 0|16@1+ (0.0015625,0) [0|100.3984375] "%" Vector__XXX

BO_ 2364744958 HVESP25D1: 8 Vector__XXX
 SG_ Cur : 48|16@1+ (0.05,-1600) [-1600|1612.75] "A" Vector__XXX
 SG_ Lvl : 32|16@1+ (0.05,0) [0|3212.75] "V" Vector__XXX
 SG_ AvailableChargePwr : 16|16@1+ (0.05,0) [0|3212.75] "kW" Vector__XXX
 SG_ AvailableDisPwr : 0|16@1+ (0.05,0) [0|3212.75] "kW" Vector__XXX

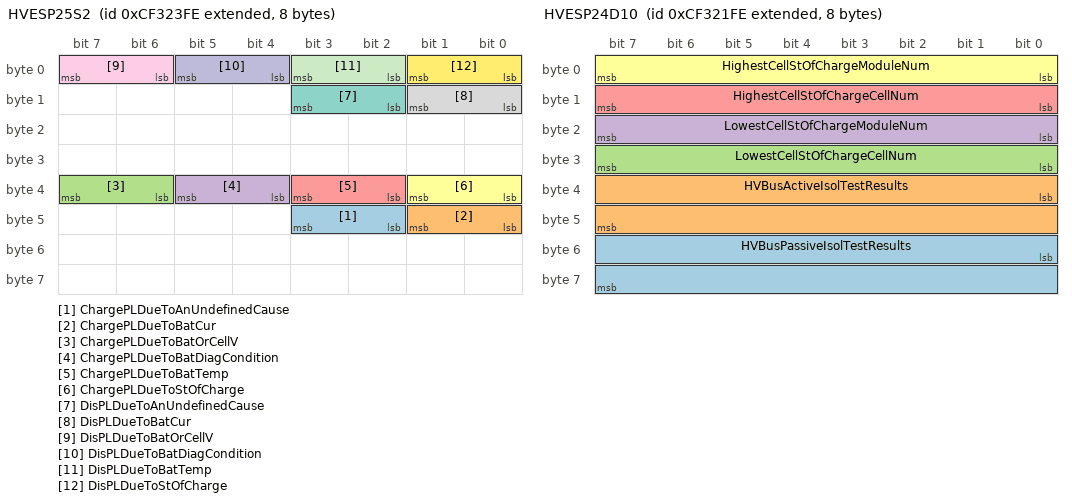
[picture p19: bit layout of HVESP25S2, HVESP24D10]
BO_ 2364744702 HVESP25S2: 8 Vector__XXX
 SG_ ChargePLDueToAnUndefinedCause : 42|2@1+ (1,0) [0|3] "" Vector__XXX
 SG_ ChargePLDueToBatCur : 40|2@1+ (1,0) [0|3] "" Vector__XXX
 SG_ ChargePLDueToBatOrCellV : 38|2@1+ (1,0) [0|3] "" Vector__XXX
 SG_ ChargePLDueToBatDiagCondition : 36|2@1+ (1,0) [0|3] "" Vector__XXX
 SG_ ChargePLDueToBatTemp : 34|2@1+ (1,0) [0|3] "" Vector__XXX
 SG_ ChargePLDueToStOfCharge : 32|2@1+ (1,0) [0|3] "" Vector__XXX
 SG_ DisPLDueToAnUndefinedCause : 10|2@1+ (1,0) [0|3] "" Vector__XXX
 SG_ DisPLDueToBatCur : 8|2@1+ (1,0) [0|3] "" Vector__XXX
 SG_ DisPLDueToBatOrCellV : 6|2@1+ (1,0) [0|3] "" Vector__XXX
 SG_ DisPLDueToBatDiagCondition : 4|2@1+ (1,0) [0|3] "" Vector__XXX
 SG_ DisPLDueToBatTemp : 2|2@1+ (1,0) [0|3] "" Vector__XXX
 SG_ DisPLDueToStOfCharge : 0|2@1+ (1,0) [0|3] "" Vector__XXX

BO_ 2364744446 HVESP24D11: 8 Vector__XXX
 SG_ ActualChargeRate : 32|16@1+ (0.05,0) [0|3212.75] "kW" Vector__XXX
 SG_ LvlNegToChassisGroundV : 16|16@1+ (0.05,0) [0|3212.75] "V" Vector__XXX
 SG_ BusVNegToChassisGroundV : 0|16@1+ (0.05,0) [0|3212.75] "V" Vector__XXX

BO_ 2364744190 HVESP24D10: 8 Vector__XXX
 SG_ HVBusPassiveIsolTestResults : 48|16@1+ (0.1,0) [0|6425.5] "Ohm/V" Vector__XXX
 SG_ HVBusActiveIsolTestResults : 32|16@1+ (0.1,0) [0|6425.5] "Ohm/V" Vector__XXX
 SG_ LowestCellStOfChargeCellNum : 24|8@1+ (1,0) [0|250] "" Vector__XXX
 SG_ LowestCellStOfChargeModuleNum : 16|8@1+ (1,0) [0|250] "" Vector__XXX
 SG_ HighestCellStOfChargeCellNum : 8|8@1+ (1,0) [0|250] "" Vector__XXX
 SG_ HighestCellStOfChargeModuleNum : 0|8@1+ (1,0) [0|250] "" Vector__XXX

CM_ BO_ 2566544382 "EV DC Status 1
This message carries status of the vehicle during DC charging to the EVSE.
This PG may be used on systems that only support a single connection to a DC EVSE.
It has been superseded by PGN 18944 (EV Multi-Connection DC Status 1) ...";
CM_ SG_ 2566544382 ErrorCode "Indicates the highest priority EV internal error state that may inhibit/abort charging
See SAE J2847-2 (April 2015 Section 4.2.26)
0000b = No Error
0001b = Battery Temperature too hot/cold
0010b = Shift Position  (Vehicle not in park)
0011b = ...";
CM_ SG_ 2566544382 RESSConditioningFlag "Informs the EVSE that the EV is using energy from the EVSE  to perform battery (RESS/HVES) conditioning.
See SAE J2847-2 (April 2015 Section 4.2.33)
00b = Battery conditioning not active
01b = Battery conditioning active
10b = Reserved
11b = ...";
CM_ SG_ 2566544382 CabinConditioningFlag "Informs the EVSE that the EV is performing cabin conditioning.

See SAE J2847-2 (April 2015 Section 4.2.23)

00b = Cabin conditioning not active
01b = Cabin conditioning active
10b = Reserved
11b = Not available";
CM_ BO_ 2566544126 "Genset External Coolant System
The temperature of the coolant flowing in and out of the generator system for external heating.";
CM_ SG_ 2566544126 HeatingCircPumpCtrl "Control setting for an electrically actuated customer site heating circuit pump.

00b = Off
01b = On
10b = Reserved
11b = Don't care / take no action";
CM_ SG_ 2566544126 HeatingCircDiffPressSwStatus "The differential pressure measured across the input and output of the heating circuit pump.

00b = OK (Pressure Normal)
01b = Not OK (Pressure Out of Range)
10b = Error (Switch State Cannot Be Determined)
11b = Not Available";
CM_ SG_ 2566544126 HeatingCircThermostatOpening "Indicates the position of the heating circuit control valve. 0% represents the thermostat allows flow to completely bypass the radiator and 100% represents the flow is fully through the radiator.";
CM_ SG_ 2566544126 DesHeatingCircThermostatOpening "Indicates the desired position of the heating circuit control valve. 0% represents the thermostat allows flow to completely bypass the radiator and 100% represents the flow is fully through the
radiator.";
CM_ SG_ 2566544126 HeatingCircInletCoolantTemp "Temperature of the liquid found at the heating circuit return.";
CM_ SG_ 2566544126 HeatingCircOutCoolantTemp "Temperature of the liquid found at the heating circuit supply outlet.";
CM_ BO_ 2566543870 "Genset Enclosure Ventilation Louver
Transmit status information of the Ventilation Louvers
These parameters are intended for stationary Generator/Engine components, not mobile applications.  See \"Motor/Generator\" PGs for electric and hybrid ...";
CM_ SG_ 2566543870 RecirculationLouverActPos "Position of the recirculation ventilation louver. A value of 0% represents fully closed and 100% represents fully open.";
CM_ SG_ 2566543870 RecirculationLouverActDesPos "Actuator that controls the opening of the recirculation ventilation louver. The control command to the actuator, normalized to percent, where 0% nominally represents fully closed (minimum air flow) and 100% represents fully open (maximum air flow).";
CM_ SG_ 2566543870 Act2Pos "Position of the ventilation louver 2. A value of 0% represents fully closed and 100% represents fully open.";
CM_ SG_ 2566543870 Act2DesPos "Actuator that controls the opening of the ventilation louver 2. The control command to the actuator, normalized to percent, where 0% nominally represents fully closed (minimum air flow) and 100% represents fully open (maximum air flow).";
CM_ SG_ 2566543870 Act1Pos "Position of the ventilation louver 1. A value of 0% represents fully closed and 100% represents fully open.";
CM_ SG_ 2566543870 Act1DesPos "Actuator that controls the opening of the ventilation louver 1. The control command to the actuator, normalized to percent, where 0% nominally represents fully closed (minimum air flow) and 100% represents fully open (maximum air flow).";
CM_ BO_ 2566543614 "Engine Exhaust Gas Heat Exchanger
Transmit information from the exhaust gas heat exchanger sensors to the control module.";
CM_ SG_ 2566543614 BypassAct1Pos "Position of the exhaust heat exchanger bypass control valve.  0% represents the bypass valve is closed and 100% represents the bypass is fully open allowing all of the exhaust gas to bypass the exhaust heat exchanger.";
CM_ SG_ 2566543614 BypassAct1DesPos "Used to transmit the desired position of the exhaust heat exchanger bypass control valve.  0% represents the bypass valve is closed and 100% represents the bypass is fully open allowing all of the exhaust gas to bypass the exhaust heat exchanger.";
CM_ SG_ 2566543614 TempAfterExhHeatExchanger "Temperature of engine combustion byproducts leaving the exhaust heat exchanger system.";
CM_ BO_ 2566543358 "Heat Exchanger 4
This parameter group transfers measured coolant temperature of a Heat Exchanger. This PG is used for the forth heat exchanger if there are more than one in the system.";
CM_ SG_ 2566543358 SecondOutTemp "Temperature of the liquid found at the outlet of the heat exchanger 4 secondary intake.";
CM_ SG_ 2566543358 SecondInTemp "Temperature of the liquid found at the intake of the heat exchanger 4 secondary intake.";
CM_ SG_ 2566543358 PrimaryOutTemp "Temperature of the liquid found at the outlet of the heat exchanger 4 primary intake.";
CM_ SG_ 2566543358 PrimaryInTemp "Temperature of the liquid found at the intake of the heat exchanger 4 primary intake.";
CM_ BO_ 2566543102 "Heat Exchanger 3
This parameter group transfers measured coolant temperature of a Heat Exchanger. This PG is used for the third heat exchanger if there are more than one in the system.";
CM_ SG_ 2566543102 SecondOutTemp "Temperature of the liquid found at the outlet of the heat exchanger 3 secondary intake.";
CM_ SG_ 2566543102 SecondInTemp "Temperature of the liquid found at the intake of the heat exchanger 3 secondary intake.";
CM_ SG_ 2566543102 PrimaryOutTemp "Temperature of the liquid found at the outlet of the heat exchanger 3 primary intake.";
CM_ SG_ 2566543102 PrimaryInTemp "Temperature of the liquid found at the intake of the heat exchanger 3 primary intake.";
CM_ BO_ 2566542846 "Heat Exchanger 2
This parameter group transfers measured coolant temperature of a Heat Exchanger. This PG is used for the second heat exchanger if there are more than one in the system.";
CM_ SG_ 2566542846 SecondOutTemp "Temperature of the liquid found at the outlet of the heat exchanger 2 secondary intake.";
CM_ SG_ 2566542846 SecondInTemp "Temperature of the liquid found at the intake of the heat exchanger 2 secondary intake.";
CM_ SG_ 2566542846 PrimaryOutTemp "Temperature of the liquid found at the outlet of the heat exchanger 2 primary intake.";
CM_ SG_ 2566542846 PrimaryInTemp "Temperature of the liquid found at the intake of the heat exchanger 2 primary intake.";
CM_ BO_ 2566542590 "Heat Exchanger 1
This parameter group transfers measured coolant temperature of a Heat Exchanger. This PG is used for the primary heat exchanger if there are more than one in the system.";
CM_ SG_ 2566542590 SecondOutTemp "Temperature of the liquid found at the outlet of the heat exchanger 1 secondary intake.";
CM_ SG_ 2566542590 SecondInTemp "Temperature of the liquid found at the intake of the heat exchanger 1 secondary intake.";
CM_ SG_ 2566542590 PrimaryOutTemp "Temperature of the liquid found at the outlet of the heat exchanger 1 primary intake.";
CM_ SG_ 2566542590 PrimaryInTemp "Temperature of the liquid found at the intake of the heat exchanger 1 primary intake.";
CM_ BO_ 2566542334 "Genset Enclosure Ventilation
This parameter group transfers status and measured information for an engine enclosure ventilation system.
These parameters are intended for stationary Generator/Engine components, not mobile applications.  See ...";
CM_ SG_ 2566542334 FanSt "Status of an electrically operated genset enclosure ventilation fan.

00b = Inactive
01b = Active
10b = Error
11b = Not available";
CM_ SG_ 2566542334 FanReqPercentSpd "Fan speed in the system as a ratio of the actual fan drive (current speed) to the fully engaged fan drive (maximum fan speed). A two state fan (off/on) will use 0% and 100% respectively. A three state
fan (off/intermediate/on) will use 0%, 50% and ...";
CM_ SG_ 2566542334 OutAirTemp "Temperature of air at the outlet of the genset enclosure.";
CM_ SG_ 2566542334 InAirTemp "Temperature of air at the inlet of the genset enclosure.";
CM_ BO_ 2566542078 "Engine Radiator 2
This parameter group transfers status and measured information for an engine radiator coolant fan. This PG is used for the secondary electrically operated fan if there are more than one fan in the system.";
CM_ SG_ 2566542078 Fan8Status "Status of electrically operated cooling Radiator 2 Fan 8 on an engine.

00b = Inactive
01b = Active
10b = Error
11b = Not available";
CM_ SG_ 2566542078 Fan7Status "Status of electrically operated cooling Radiator 2 Fan 7 on an engine.

00b = Inactive
01b = Active
10b = Error
11b = Not available";
CM_ SG_ 2566542078 Fan6Status "Status of electrically operated cooling Radiator 2 Fan 6 on an engine.

00b = Inactive
01b = Active
10b = Error
11b = Not available";
CM_ SG_ 2566542078 Fan5Status "Status of electrically operated cooling Radiator 2 Fan 5 on an engine.

00b = Inactive
01b = Active
10b = Error
11b = Not available";
CM_ SG_ 2566542078 Fan4Status "Status of electrically operated cooling Radiator 2 Fan 4 on an engine.

00b = Inactive
01b = Active
10b = Error
11b = Not available";
CM_ SG_ 2566542078 Fan3Status "Status of electrically operated cooling Radiator 2 Fan 3 on an engine.

00b = Inactive
01b = Active
10b = Error
11b = Not available";
CM_ SG_ 2566542078 Fan2Status "Status of electrically operated cooling Radiator 2 Fan 2 on an engine.

00b = Inactive
01b = Active
10b = Error
11b = Not available";
CM_ SG_ 2566542078 Fan1Status "Status of electrically operated cooling Radiator 2 Fan 1 on an engine.

00b = Inactive
01b = Active
10b = Error
11b = Not available";
CM_ SG_ 2566542078 DesEngRadiator2CtrlTemp "Indicates the desired temperature of the temperature used to control the fan speed.";
CM_ SG_ 2566542078 CtrlTemp "Temperature measured and reported by the device. It may be used for direct or remote (by another controller) control of the Fan 2. For example, this may be the temperature of the fluid flowing through the Fan 2, or some other temperature relating to ...";
CM_ BO_ 2566541822 "Engine Radiator 1
This parameter group transfers status and measured information for an engine radiator coolant fan. This PG is used for the primary electrically operated fan if there are more than one fan in the system.";
CM_ SG_ 2566541822 TempCtrlSelectionSt "Indicates the active control temperature setpoint used to control the radiator.

00b = Engine Radiator 1 Control Temperature
01b = Engine Radiator 2 Control Temperature
10b = Error
11b = Not Available";
CM_ SG_ 2566541822 Fan8Status "Status of electrically operated cooling Radiator 1 Fan 8 on an engine.

00b = Inactive
01b = Active
10b = Error
11b = Not available";
CM_ SG_ 2566541822 Fan7Status "Status of electrically operated cooling Radiator 1 Fan 7 on an engine.

00b = Inactive
01b = Active
10b = Error
11b = Not available";
CM_ SG_ 2566541822 Fan6Status "Status of electrically operated cooling Radiator 1 Fan 6 on an engine.

00b = Inactive
01b = Active
10b = Error
11b = Not available";
CM_ SG_ 2566541822 Fan5Status "Status of electrically operated cooling Radiator 1 Fan 5 on an engine.

00b = Inactive
01b = Active
10b = Error
11b = Not available";
CM_ SG_ 2566541822 Fan4Status "Status of electrically operated cooling Radiator 1 Fan 4 on an engine.

00b = Inactive
01b = Active
10b = Error
11b = Not available";
CM_ SG_ 2566541822 Fan3Status "Status of electrically operated cooling Radiator 1 Fan 3 on an engine.

00b = Inactive
01b = Active
10b = Error
11b = Not available";
CM_ SG_ 2566541822 Fan2Status "Status of electrically operated cooling Radiator 1 Fan 2 on an engine.

00b = Inactive
01b = Active
10b = Error
11b = Not available";
CM_ SG_ 2566541822 Fan1Status "Status of electrically operated cooling Radiator 1 Fan 1 on an engine.

00b = Inactive
01b = Active
10b = Error
11b = Not available";
CM_ SG_ 2566541822 DesEngRadiator1CtrlTemp "The desired temperature of the temperature used to control the radiator fan speed.";
CM_ SG_ 2566541822 CtrlTemp "Temperature measured and reported by the device. It may be used for direct or remote (by another controller) control of radiator 1.";
CM_ BO_ 2566541566 "Aftercooler Valve
Transmit status information of the Aftercooler Temperature Control";
CM_ SG_ 2566541566 SepCPCtrl "This control is used to activate an engine low temperature aftercooler coolant pump.

00b = Off
01b = On
10b = Reserved
11b = Unavailable";
CM_ SG_ 2566541566 SepCoolantDiffPressSwStatus "The differential pressure measured across the input and output of the engine low temperature aftercooler coolant pump.
00b = OK (Pressure Normal)
01b = Not OK (Pressure Out of Range)
10b = Error (Switch State Cannot Be Determined)
11b = Not ...";
CM_ SG_ 2566541566 DesAftercoolerCoolantInTemp "Indicates the desired temperature of the fluid in the engine low temperature aftercooler circuit to an electronic thermostat.

See SPN 4199 for alternate resolution.";
CM_ SG_ 2566541566 SepCoolantTemp "Temperature of liquid found at the intake to the engine low temperature aftercooler located after the turbocharger.";
CM_ BO_ 2566541310 "Automated Driving System Control 3
Sent by the controller that has the automated driving system configuration Information.";
CM_ SG_ 2566541310 CRC "The CRC is defined as follows:
• Length: 8 bits
• Polynomial: x^8+x^5+x^3+x^2+x+1
• Initial Value: FFh
• Input Data Reflection: Not reflected
• Result Data Reflection: Not reflected
• XOR value: FFh
SAE makes no claim of the functional safety ...";
CM_ SG_ 2566541310 Counter "The message counter is used to detect situations where the transmitting ECU malfunction repeats the same frame all the time. The receiver of the information may use the counter parameter to detect this situation. The transmitting device will ...";
CM_ SG_ 2566541310 EmbeddedIntegritySupport "Indicates that SPN 14456 (ADSC3 CRC) and SPN 14455 (ADSC3 Counter) are supported by the sender.
00b = ADSC3 embedded CRC and Counter are supported by the sender
01b = ADSC3 protection is supported using J1939-76 SHM
10b = Reserved
11b = ADSC3 ...";
CM_ SG_ 2566541310 OpStatus "This parameter indicates the current engagement mode of the automated driving system. This parameter is only expected to change when the vehicle's ADS configuration is capable of changing.
In the event the ADS cannot determine its operating mode or ...";
CM_ BO_ 2566541054 "Automated Driving System Status 2
Sent by a controller application that is integrated with an automated driving system for proper operation of the overall system.";
CM_ SG_ 2566541054 CpntDiagAndMtCap "This parameter is sent by a controller application that is integrated with an Automated Driving System (ADS), such as the engine control module, transmission control module, etc. This parameter indicates whether the controller application currently ...";
CM_ SG_ 2566541054 Ctrl4CommunicationSt "This parameter indicates the current status of the ADS controller 4 detected by the controller application under the control of automated driving system.
000b = System is not ready (initialization not finished)
001b = Active
010b = Reserved
011b ...";
CM_ SG_ 2566541054 Ctrl3CommunicationSt "This parameter indicates the current status of the ADS controller 3 detected by the controller application under the control of automated driving system.
000b = System is not ready (initialization not finished)
001b = Active
010b = Reserved
011b ...";
CM_ SG_ 2566541054 Ctrl2CommunicationSt "This parameter indicates the current status of the ADS controller 2 detected by the controller application under the control of automated driving system.
000b = System is not ready (initialization not finished)
001b = Active
010b = Reserved
011b ...";
CM_ SG_ 2566541054 Ctrl1CommunicationSt "This parameter indicates the current status of the ADS controller 1 detected by the controller application under the control of automated driving system.
000b = System is not ready (initialization not finished)
001b = Active
010b = Reserved
011b ...";
CM_ SG_ 2566541054 AutomatedModeSupport "This parameter indicates the support for Automated Mode by a ADS recipient. This parameter is expected to change as defined in SPN 20870 (Automated Driving System Operation Status).

00 - Disabled
01 - Enabled
10 - Reserved
11 - Not Available";
CM_ SG_ 2566541054 AutomatedModeWithOpOvrdSupport "This parameter indicates the support for Automated Mode with Operator Override by a ADS recipient. This parameter is expected to change as defined in SPN 20870 (Automated Driving System Operation Status).
00 - Disabled
01 - Enabled
10 - Reserved
 ...";
CM_ SG_ 2566541054 ManualModeSupport "This parameter indicates the support for ADS Manual Mode by a ADS recipient. This parameter is expected to change as defined in SPN 20870 (Automated Driving System Operation Status).

00b - Disabled
01b - Enabled
10b - Reserved
11b - Not Available";
CM_ SG_ 2566541054 OpStatusAcknowledgement "This parameter indicates the current mode of an ADSC recipient. It is expected to be same as the SPN 20870 (Automated Driving System Operation Status).
000b = ADS Manual Mode
001b = ADS Automated Mode with Operator Override Capability
010b = ADS ...";
CM_ BO_ 2566540798 "EV Economy Information
Contains Energy Economy parameters.";
CM_ SG_ 2566540798 TripDriveEnergyEconomy "Trip Drive Energy Economy (i.e. powertrain and electrified accessory energy) is equal to the electric vehicle Total Trip Energy Consumed (SPN 20876) divided by the vehicle distance traveled (in KM) since the last Trip Reset. (See PGN 56832 RESET)";
CM_ SG_ 2566540798 TotalTripEnergyConsumed "Energy consumed by all the vehicle active powertrain and electrified accessories since the last Trip Reset. (See PGN 56832 RESET)";
CM_ BO_ 2566540542 "Aftertreatment 1 SCR Dosing System Information 5
This message contains SCR dosing system information for aftertreatment system 1 (or bank 1).";
CM_ SG_ 2566540542 DEFDoser3Press "The SCR doser 3 diesel exhaust fluid gage pressure (measured closest to dosing valve) for aftertreatment system 1 (exhaust bank 1).";
CM_ SG_ 2566540542 DEFDoser2Press "The SCR doser 2 diesel exhaust fluid gage pressure (measured closest to dosing valve) for aftertreatment system 1 (exhaust bank 1).

See SPN 8152 for alternate range and resolution.";
CM_ BO_ 2566540286 "Aftertreatment 2 SCR Dosing System Information 5
This message contains SCR dosing system information for aftertreatment system 2 (or bank 2).";
CM_ SG_ 2566540286 DEFDoser3Press "The SCR doser 3 diesel exhaust fluid gage pressure (measured closest to dosing valve) for aftertreatment system 2 (exhaust bank 2).";
CM_ SG_ 2566540286 DEFDoser2Press "The SCR doser 2 diesel exhaust fluid gage pressure (measured closest to dosing valve) for aftertreatment system 2 ( exhaust bank 2).

See SPN 8153 for alternate range and resolution.";
CM_ BO_ 2364752638 "Active Steering System Controller 2
Active Steering System Controller 2";
CM_ SG_ 2364752638 MessageChecksum "The ASSC2 message checksum is used to verify the signal path from the demanding device to the active steering system.
The 4 bit ASSC2 message checksum is calculated using the first 7 data bytes, the 4 bit message counter and the bytes of the ...";
CM_ SG_ 2364752638 MessageCounter "The ASSC2 message counter is to verify the signal path from the demanding device to the active steering system.
Note: The initial value of the 4 bit message counter for the first message during a driving cycle is arbitrary. In every following ...";
CM_ SG_ 2364752638 SteerWheelTrq "Measured steering torque at the hand wheel from the active steering system.
This value is referenced at the main operator`s steering wheel angle (on the steering column, not the actual road wheel angle).  The vehicle being steered to the left ...";
CM_ SG_ 2364752638 SteerWheelPos "Measured absolute steering hand wheel position from the active steering system.
This value is referenced at the main operator`s steering wheel angle (on the steering column, not the actual road wheel angle).  The vehicle being steered to the left ...";
CM_ SG_ 2364752638 AbsSteerPosQualityFactor "Absolute Steering Position Quality Factor indicates the integrity of the Active Steering System Steering Wheel Position (SPN 21102) reported by the active steering system controller.  The external vehicle control device using the absolute steering ...";
CM_ SG_ 2364752638 IgntPwr "Indicates that the ignition (or \"run\") voltage that is being supplied to the active steering system. This state is also known in DIN 75552 as \"KL15\".
This parameter may or may not represent the physical position of a rotary key switch.
00b = ...";
CM_ SG_ 2364752638 ReqMode "Indicates the input received for desired operating mode in the XSR message. Not all modes may be relevant for a given device. Some devices may not implement all functions.
0000b = External Request Disabled - Default Mode
0001b = Steering Position ...";
CM_ SG_ 2364752638 ErrorType "Indicates the error type of the steering controller. The signal can be used to initiate various fail operational methods.
0000b = No Error
0001b = External Request Missing
0010b = Redundant Communication Error
0011b = Internal Unit Error
0100b ...";
CM_ SG_ 2364752638 St "Indicates the current state of the active steering system controller for external steering requests.
0000b = System is not ready
0001b = System is temporarily not available
0010b = System is ready
0011b = System Malfunction - Main
0100b = ...";
CM_ SG_ 2364752638 ActualMode "Signal indicates the current mode of the active steering system.
0000b = External Request Disabled - Default Mode
0001b = Steering Position Control with Driver Override
0010b = Steering Position Control without Driverride
0011b = No Motor ...";
CM_ BO_ 2297643518 "External Steering Request
External request to the steering controller";
CM_ SG_ 2297643518 XSRMessageChecksum "The XSR message checksum is used to verify the signal path from the demanding device to the active steering system.
The 4 bit XSR message checksum is calculated using the first 7 data bytes, the 4 bit message counter and the bytes of the message ...";
CM_ SG_ 2297643518 XSRMessageCounter "The XSR message counter is to verify the signal path from the demanding device to the active steering system.
Note: The initial value of the 4 bit message counter for the first message during a driving cycle is arbitrary. In every following message ...";
CM_ SG_ 2297643518 Priority "XSR Priority is used as an input to the steering system to manage the priority of overlapping external and internal requests.
0000b = Priority 1
0001b = Priority 2
0010b = Priority 3
0011b = Priority 4
0100b = Reserved
0101b = Reserved
0110b ...";
CM_ SG_ 2297643518 WheelTrqReq "Indicates the steering torque input command value to the active steering system from the controlling device and is enabled when the torque control mode is selected.
This commanded torque is referenced at the main operator`s steering wheel (on the ...";
CM_ SG_ 2297643518 WheelPosReq "Indicates the steering wheel position input command value to the active steering system and is enabled when the steering position control mode is selected.
This commanded value is referenced at the main operator`s steering wheel (on the steering ...";
CM_ SG_ 2297643518 OperatingMode "The operating mode is used as an input to the steering system and defines the desired operating mode requested by an external controlling device. When the driver override is enabled, the steering command will discontinue when the active steering ...";
CM_ BO_ 2364752126 "High Voltage Energy Storage Pack 26 Data 11
Data set 11 (electrical data) for High Voltage Energy Storage Pack 26.";
CM_ SG_ 2364752126 ActualChargeRate "This signal represents the actual present charge rate of this High Voltage Energy Storage Pack instance.
This parameter is for one of multiple packs in an HVESS. If there is only one pack in the system, the HVESS parameters should be used. If there ...";
CM_ SG_ 2364752126 LvlNegToChassisGroundV "Voltage difference between the most negative terminal of the HVES battery and chassis measured at the battery side of any HVES contained output contactor.  This voltage may be used for system level monitoring of battery shorts to chassis within the ...";
CM_ SG_ 2364752126 BusVNegToChassisGroundV "Voltage difference between the most negative terminal of the HVES battery and chassis measured on the hybrid system bus side (not the battery side) of any HVES contained output contactor.  This voltage may be used for system level monitoring of ...";
CM_ BO_ 2364751870 "High Voltage Energy Storage Pack 26 Data 10
Data set 10 (electrical) for High Voltage Energy Storage Pack 26.";
CM_ SG_ 2364751870 HVBusPassiveIsolTestResults "The isolation resistance expressed in Ohms per Volt that resulted from the High-Voltage Bus Passive Isolation Test.
See SPN 17453 (HVESP26 High-Voltage Bus Passive Isolation Test Status) for test status and SPN 17402 (HVESP26 High-Voltage Bus ...";
CM_ SG_ 2364751870 HVBusActiveIsolTestResults "The isolation resistance expressed in Ohms per Volt that resulted from the High-Voltage Bus Active Isolation Test.
See SPN 17452 (HVESP26 High-Voltage Bus Active Isolation Test Status) for test status and SPN 17401 (HVESP26 High-Voltage Bus Active ...";
CM_ SG_ 2364751870 LowestCellStOfChargeCellNum "Identifies the location of SPN 17439 (HVESP26 Lowest Cell State of Charge) within SPN 17518 (HVESP26 Lowest Cell State of Charge Module Number).
This parameter is for one of multiple packs in an HVESS. If there is only one pack in the system, the ...";
CM_ SG_ 2364751870 LowestCellStOfChargeModuleNum "Identifies the location of the module containing SPN 17439 (HVESP26 Lowest Cell State of Charge).
This parameter is for one of multiple packs in an HVESS. If there is only one pack in the system, the HVESS parameters should be used. If there are ...";
CM_ SG_ 2364751870 HighestCellStOfChargeCellNum "Identifies the location of SPN 17440 (HVESP26 Highest Cell State of Charge) within SPN 17516 (HVESP26 Highest Cell State of Charge Module Number).
This parameter is for one of multiple packs in an HVESS. If there is only one pack in the system, the ...";
CM_ SG_ 2364751870 HighestCellStOfChargeModuleNum "Identifies the location of the module containing SPN 17440 (HVESP26 Highest Cell State of Charge).
This parameter is for one of multiple packs in an HVESS. If there is only one pack in the system, the HVESS parameters should be used. If there are ...";
CM_ BO_ 2364751614 "High Voltage Energy Storage Pack 26 Data 9
Data set 9 (thermal) for High Voltage Energy Storage Pack 26.";
CM_ SG_ 2364751614 Data9CRC "The CRC is defined as follows:
• Length: 8 bits
• Polynomial: x^8+x^5+x^3+x^2+x+1
• Initial Value: FFh
• Input Data Reflection: Not reflected
• Result Data Reflection: Not reflected
• XOR value: FFh
SAE makes no claim of the functional safety ...";
CM_ SG_ 2364751614 Data9Counter "The message counter is used to detect situations where the transmitting ECU malfunction repeats the same frame all the time. The receiver of the information may use the counter parameter to detect this situation. The transmitting device will ...";
CM_ SG_ 2364751614 Data9EmbeddedIntegritySupport "Indicates SPN 23051 (HVESP26 Data 9 CRC) and SPN 23050 (HVESP26 Data 9 Counter) are supported by the sender.
00b = Embedded CRC and Counter are supported by the sender
01b = Protection is supported using J1939-76 SHM
10b = Reserved
11b = CRC and ...";
CM_ SG_ 2364751614 HVESS26ThermalEventDetected "A sensor has detected the presence of a thermal event at or near High Voltage Energy Storage Pack instance.
00b = No Thermal Event Detected
01b = Thermal Event Detected
10b = Error
11b = Not available
This parameter is for one of multiple packs ...";
CM_ SG_ 2364751614 LowestCellTempCellNum "Identifies the location of SPN 17431 (HVESP26 Lowest Cell Temperature) within SPN 17514 (HVESP26 Lowest Cell Temperature Module Number).
This parameter is for one of multiple packs in an HVESS. If there is only one pack in the system, the HVESS ...";
CM_ SG_ 2364751614 LowestCellTempModuleNum "Identifies the location of the module containing SPN 17431 (HVESP26 Lowest Cell Temperature).
This parameter is for one of multiple packs in an HVESS. If there is only one pack in the system, the HVESS parameters should be used. If there are ...";
CM_ SG_ 2364751614 HighestCellTempCellNum "Identifies the location of SPN 17430 (HVESP26 Highest Cell Temperature) within SPN 17512 (HVESP26 Highest Cell Temperature Module Number).
This parameter is for one of multiple packs in an HVESS. If there is only one pack in the system, the HVESS ...";
CM_ SG_ 2364751614 HighestCellTempModuleNum "Identifies the location of the module containing SPN 17430 (HVESP26 Highest Cell Temperature).
This parameter is for one of multiple packs in an HVESS. If there is only one pack in the system, the HVESS parameters should be used. If there are ...";
CM_ BO_ 2364751358 "High Voltage Energy Storage Pack 26 Data 8
Data set 8 (electrical data) for High Voltage Energy Storage Pack 26.";
CM_ SG_ 2364751358 AvgCellV "The average cell voltage in this High Voltage Energy Storage Pack instance.
This parameter is for one of multiple packs in an HVESS.  If there is only one pack in the system, the HVESS parameters should be used. If there are multiple packs in the ...";
CM_ SG_ 2364751358 LowestCellVCellNum "Identifies the location of SPN 17428 (HVESP26 Lowest Cell Voltage) within SPN 17509 (HVESP26 Lowest Cell Voltage Module Number).
This parameter is for one of multiple packs in an HVESS. If there is only one pack in the system, the HVESS parameters ...";
CM_ SG_ 2364751358 LowestCellVModuleNum "Identifies the location of the module containing SPN 17428 (HVESP26 Lowest Cell Voltage).
This parameter is for one of multiple packs in an HVESS. If there is only one pack in the system, the HVESS parameters should be used. If there are multiple ...";
CM_ SG_ 2364751358 HighestCellVCellNum "Identifies the location of SPN 17427 (HVESP26 Highest Cell Voltage) within SPN 17507 (HVESP26 Highest Cell Voltage Module Number).
This parameter is for one of multiple packs in an HVESS. If there is only one pack in the system, the HVESS ...";
CM_ SG_ 2364751358 HighestCellVModuleNum "Identifies the location of the module containing SPN 17427 (HVESP26 Highest Cell Voltage).
This parameter is for one of multiple packs in an HVESS. If there is only one pack in the system, the HVESS parameters should be used. If there are multiple ...";
CM_ BO_ 2364751102 "High Voltage Energy Storage Pack 26 Thermal Management System Status 1
Collection of data the High Voltage Energy Storage Pack 26 Thermal Management System sends to the Hybrid Controller.";
CM_ SG_ 2364751102 TMSCoolantLvl "Indicates the coolant level in this HVES Thermal Management System (TMS).
This parameter is for one of multiple packs in an HVESS.  If there is only one pack in the system, the HVESS parameters should be used. If there are multiple packs in the ...";
CM_ SG_ 2364751102 TMSMode "Indicates the operating mode of the Thermal Management System.  The heat transfer medium may be (e.g. liquid or air).  The cooling system may be fans, liquid coolant, or a combination of mediums.  The system may include an air and/or liquid ...";
CM_ SG_ 2364751102 TMSHVILStatus "In multiple HVES configurations, this is the status of the High Voltage Interlock Loop from the viewpoint of this Thermal Management System.
00b = HVIL Closed
01b = HVIL Open
10b = Error
11b = Not Available
This parameter is for one of multiple ...";
CM_ SG_ 2364751102 TMSHtrStatus "The state of this High Voltage Energy Storage Pack heater
This parameter is for one of multiple packs in an HVESS.  If there is only one pack in the system, the HVESS parameters should be used. If there are multiple packs in the system, then both ...";
CM_ SG_ 2364751102 TMSRelHumidty "When this High Voltage Energy Storage Pack Thermal Management System is equipped with a relative humidity sensor, this is the  measured Relative Humidity.
This parameter is for one of multiple packs in an HVESS.  If there is only one pack in the ...";
CM_ SG_ 2364751102 TMSCompressorSpd "When this High Voltage Energy Storage Pack Thermal Management System is equipped with an active cooling system (e.g. air conditioner), this is the Compressor Speed.
This parameter is for one of multiple packs in an HVESS.  If there is only one pack ...";
CM_ SG_ 2364751102 TMSHVInputPwr "This is the high-voltage power consumed by this HVES Thermal Management System (TMS).
This parameter is for one of multiple packs in an HVESS.  If there is only one pack in the system, the HVESS parameters should be used. If there are multiple ...";
CM_ SG_ 2364751102 TMSSLIInputPwr "This is the low-voltage power consumed by this HVES Thermal Management System (TMS).
This parameter is for one of multiple packs in an HVESS.  If there is only one pack in the system, the HVESS parameters should be used.  If there are multiple ...";
CM_ BO_ 2364750846 "High Voltage Energy Storage Pack 26 Module Status 1
Module Status message 1 for High Voltage Energy Storage Pack 26.";
CM_ SG_ 2364750846 Module32OperationalStatus "Operational Status of Module 32 in this High Voltage Energy Storage Pack Instance.  Not Operational is used when the module is initializing or not able to function (e.g. internal module level monitors have failed).  Operational indicates that the ...";
CM_ SG_ 2364750846 Module31OperationalStatus "Operational Status of Module 31 in this High Voltage Energy Storage Pack Instance.  Not Operational is used when the module is initializing or not able to function (e.g. internal module level monitors have failed).  Operational indicates that the ...";
CM_ SG_ 2364750846 Module30OperationalStatus "Operational Status of Module 30 in this High Voltage Energy Storage Pack Instance.  Not Operational is used when the module is initializing or not able to function (e.g. internal module level monitors have failed).  Operational indicates that the ...";
CM_ SG_ 2364750846 Module29OperationalStatus "Operational Status of Module 29 in this High Voltage Energy Storage Pack Instance.  Not Operational is used when the module is initializing or not able to function (e.g. internal module level monitors have failed).  Operational indicates that the ...";
CM_ SG_ 2364750846 Module28OperationalStatus "Operational Status of Module 28 in this High Voltage Energy Storage Pack Instance.  Not Operational is used when the module is initializing or not able to function (e.g. internal module level monitors have failed).  Operational indicates that the ...";
CM_ SG_ 2364750846 Module27OperationalStatus "Operational Status of Module 27 in this High Voltage Energy Storage Pack Instance.  Not Operational is used when the module is initializing or not able to function (e.g. internal module level monitors have failed).  Operational indicates that the ...";
CM_ SG_ 2364750846 Module26OperationalStatus "Operational Status of Module 26 in this High Voltage Energy Storage Pack Instance.  Not Operational is used when the module is initializing or not able to function (e.g. internal module level monitors have failed).  Operational indicates that the ...";
CM_ SG_ 2364750846 Module25OperationalStatus "Operational Status of Module 25 in this High Voltage Energy Storage Pack Instance.  Not Operational is used when the module is initializing or not able to function (e.g. internal module level monitors have failed).  Operational indicates that the ...";
CM_ SG_ 2364750846 Module24OperationalStatus "Operational Status of Module 24 in this High Voltage Energy Storage Pack Instance.  Not Operational is used when the module is initializing or not able to function (e.g. internal module level monitors have failed).  Operational indicates that the ...";
CM_ SG_ 2364750846 Module23OperationalStatus "Operational Status of Module 23 in this High Voltage Energy Storage Pack Instance.  Not Operational is used when the module is initializing or not able to function (e.g. internal module level monitors have failed).  Operational indicates that the ...";
CM_ SG_ 2364750846 Module22OperationalStatus "Operational Status of Module 22 in this High Voltage Energy Storage Pack Instance.  Not Operational is used when the module is initializing or not able to function (e.g. internal module level monitors have failed).  Operational indicates that the ...";
CM_ SG_ 2364750846 Module21OperationalStatus "Operational Status of Module 21 in this High Voltage Energy Storage Pack Instance.  Not Operational is used when the module is initializing or not able to function (e.g. internal module level monitors have failed).  Operational indicates that the ...";
CM_ SG_ 2364750846 Module20OperationalStatus "Operational Status of Module 20 in this High Voltage Energy Storage Pack Instance.  Not Operational is used when the module is initializing or not able to function (e.g. internal module level monitors have failed).  Operational indicates that the ...";
CM_ SG_ 2364750846 Module19OperationalStatus "Operational Status of Module 19 in this High Voltage Energy Storage Pack Instance.  Not Operational is used when the module is initializing or not able to function (e.g. internal module level monitors have failed).  Operational indicates that the ...";
CM_ SG_ 2364750846 Module18OperationalStatus "Operational Status of Module 18 in this High Voltage Energy Storage Pack Instance.  Not Operational is used when the module is initializing or not able to function (e.g. internal module level monitors have failed).  Operational indicates that the ...";
CM_ SG_ 2364750846 Module17OperationalStatus "Operational Status of Module 17 in this High Voltage Energy Storage Pack Instance.  Not Operational is used when the module is initializing or not able to function (e.g. internal module level monitors have failed).  Operational indicates that the ...";
CM_ SG_ 2364750846 Module16OperationalStatus "Operational Status of Module 16 in this High Voltage Energy Storage Pack Instance.  Not Operational is used when the module is initializing or not able to function (e.g. internal module level monitors have failed).  Operational indicates that the ...";
CM_ SG_ 2364750846 Module15OperationalStatus "Operational Status of Module 15 in this High Voltage Energy Storage Pack Instance.  Not Operational is used when the module is initializing or not able to function (e.g. internal module level monitors have failed).  Operational indicates that the ...";
CM_ SG_ 2364750846 Module14OperationalStatus "Operational Status of Module 14 in this High Voltage Energy Storage Pack Instance.  Not Operational is used when the module is initializing or not able to function (e.g. internal module level monitors have failed).  Operational indicates that the ...";
CM_ SG_ 2364750846 Module13OperationalStatus "Operational Status of Module 13 in this High Voltage Energy Storage Pack Instance.  Not Operational is used when the module is initializing or not able to function (e.g. internal module level monitors have failed).  Operational indicates that the ...";
CM_ SG_ 2364750846 Module12OperationalStatus "Operational Status of Module 12 in this High Voltage Energy Storage Pack Instance.  Not Operational is used when the module is initializing or not able to function (e.g. internal module level monitors have failed).  Operational indicates that the ...";
CM_ SG_ 2364750846 Module11OperationalStatus "Operational Status of Module 11 in this High Voltage Energy Storage Pack Instance.  Not Operational is used when the module is initializing or not able to function (e.g. internal module level monitors have failed).  Operational indicates that the ...";
CM_ SG_ 2364750846 Module10OperationalStatus "Operational Status of Module 10 in this High Voltage Energy Storage Pack Instance.  Not Operational is used when the module is initializing or not able to function (e.g. internal module level monitors have failed).  Operational indicates that the ...";
CM_ SG_ 2364750846 Module9OperationalStatus "Operational Status of Module 9 in this High Voltage Energy Storage Pack Instance.  Not Operational is used when the module is initializing or not able to function (e.g. internal module level monitors have failed).  Operational indicates that the ...";
CM_ SG_ 2364750846 Module8OperationalStatus "Operational Status of Module 8 in this High Voltage Energy Storage Pack Instance.  Not Operational is used when the module is initializing or not able to function (e.g. internal module level monitors have failed).  Operational indicates that the ...";
CM_ SG_ 2364750846 Module7OperationalStatus "Operational Status of Module 7 in this High Voltage Energy Storage Pack Instance.  Not Operational is used when the module is initializing or not able to function (e.g. internal module level monitors have failed).  Operational indicates that the ...";
CM_ SG_ 2364750846 Module6OperationalStatus "Operational Status of Module 6 in this High Voltage Energy Storage Pack Instance.  Not Operational is used when the module is initializing or not able to function (e.g. internal module level monitors have failed).  Operational indicates that the ...";
CM_ SG_ 2364750846 Module5OperationalStatus "Operational Status of Module 5 in this High Voltage Energy Storage Pack Instance.  Not Operational is used when the module is initializing or not able to function (e.g. internal module level monitors have failed).  Operational indicates that the ...";
CM_ SG_ 2364750846 Module4OperationalStatus "Operational Status of Module 4 in this High Voltage Energy Storage Pack Instance.  Not Operational is used when the module is initializing or not able to function (e.g. internal module level monitors have failed).  Operational indicates that the ...";
CM_ SG_ 2364750846 Module3OperationalStatus "Operational Status of Module 3 in this High Voltage Energy Storage Pack Instance.  Not Operational is used when the module is initializing or not able to function (e.g. internal module level monitors have failed).  Operational indicates that the ...";
CM_ SG_ 2364750846 Module2OperationalStatus "Operational Status of Module 2 in this High Voltage Energy Storage Pack Instance.  Not Operational is used when the module is initializing or not able to function (e.g. internal module level monitors have failed).  Operational indicates that the ...";
CM_ SG_ 2364750846 Module1OperationalStatus "Operational Status of Module 1 in this High Voltage Energy Storage Pack Instance.  Not Operational is used when the module is initializing or not able to function (e.g. internal module level monitors have failed).  Operational indicates that the ...";
CM_ BO_ 2364750590 "High Voltage Energy Storage Pack 26 Data 7
Data set 7 (electrical) for High Voltage Energy Storage Pack 26.";
CM_ SG_ 2364750590 MaxChargeVLmt "The maximum voltage level not to be exceeded while charging this High Voltage Energy Storage Pack instance. If this parameter is not supported, the maximum charge voltage should be limited to SPN 17533 (HVESP26 Recommended Maximum Operating ...";
CM_ SG_ 2364750590 ChargeEnergyCapacity "The amount of unused electrical energy storage available to be filled by charging this High Voltage Energy Storage Pack instance, i.e. “how much empty space is remaining in the tank”. See SPN 17435 (HVESP26 Charge Capacity) for Ampere-hours (Ah).
 ...";
CM_ SG_ 2364750590 DisEnergyCapacity "The amount of stored electrical energy in this High Voltage Energy Storage Pack instance that is available for use by the hybrid system, i.e. “how full is the tank”. See SPN 17434 (HVESP26 Discharge Capacity) for Ampere-hours (Ah).
This parameter ...";
CM_ BO_ 2364750334 "High Voltage Energy Storage Pack 26 Status 1
Status data set 1 for High Voltage Energy Storage Pack 26.";
CM_ SG_ 2364750334 Status1CRC "The CRC is defined as follows:
• Length: 8 bits
• Polynomial: x^8+x^5+x^3+x^2+x+1
• Initial Value: FFh
• Input Data Reflection: Not reflected
• Result Data Reflection: Not reflected
• XOR value: FFh
SAE makes no claim of the functional safety ...";
CM_ SG_ 2364750334 Status1Counter "The message counter is used to detect situations where the transmitting ECU malfunction repeats the same frame all the time. The receiver of the information may use the counter parameter to detect this situation. The transmitting device will ...";
CM_ SG_ 2364750334 OperationalStatus "Provides feedback on where this High Voltage Energy Storage Pack instance is in its operating spectrum, and includes feedback in response to the Operation Consent [i.e. SPN 17405 (HVESP26 Operation Consent)] and Power Down Command [i.e. SPN 17400 ...";
CM_ SG_ 2364750334 HVBusConnectionStatus "This parameter provides high level feedback on this High Voltage Energy Storage Pack instance high voltage bus connection. For specific contactor information, see SPN 17447 (HVESP26 High-Voltage Bus (Positive) Contactor State), SPN 17448 (HVESP26 ...";
CM_ SG_ 2364750334 InternalChargerStatus "Indicates that the charger in this HVES instance is on.  External chargers may use the External Energy Source Connection Status (SPN 7898) and related SPs.
This parameter is for one of multiple packs in an HVESS. If there is only one pack in the ...";
CM_ SG_ 2364750334 CellBalancingActive "Indicates whether or not the cells in this High Voltage Energy Storage Pack instance are currently being balanced.
This parameter is for one of multiple packs in an HVESS.  If there is only one pack in the system, the HVESS parameters should be ...";
CM_ SG_ 2364750334 CellBalanceStatus "Indicates whether or not the cells in this High Voltage Energy Storage Pack instance are balanced.
This parameter is for one of multiple packs in an HVESS.  If there is only one pack in the system, the HVESS parameters should be used. If there are ...";
CM_ SG_ 2364750334 StOfChargeStatus "Status of this High Voltage Energy Storage Pack instance State of Charge (SOC).  Note:  A given HVES controller may not support all of the states.
This parameter is for one of multiple packs in an HVESS.  If there is only one pack in the system, ...";
CM_ SG_ 2364750334 InertiaSwStatus "Switch indicating that an impact has been sensed by this High Voltage Energy Storage Pack instance. The impact indication may require action by another controller, or by this HVES instance itself.  For example, a controller may elect to take this ...";
CM_ SG_ 2364750334 HVILStatus "Status of the High Voltage Interlock Loop from the viewpoint of this High Voltage Energy Storage Pack instance.
This parameter is for one of multiple packs in an HVESS. If there is only one pack in the system, the HVESS parameters should be used ...";
CM_ SG_ 2364750334 HVBusPassiveIsolTestStatus "Status of the high-voltage bus electrical passive isolation test as performed by this High Voltage Energy Storage Pack instance.
This parameter is for one of multiple packs in an HVESS. If there is only one pack in the system, the HVESS parameters ...";
CM_ SG_ 2364750334 HVBusActiveIsolTestStatus "Status of the high-voltage bus electrical active isolation test as performed by this High Voltage Energy Storage Pack instance.
This parameter is for one of multiple packs in an HVESS. If there is only one pack in the system, the HVESS parameters ...";
CM_ SG_ 2364750334 CenterOfPackContactorSt "Position of the center high-voltage contactor. When this contactor is closed, the positive half of this High Voltage Energy Storage Pack instance is connected to the negative half. If a system controls the positive, negative, and center contactors ...";
CM_ SG_ 2364750334 HVBusPreChargeRelaySt "Position of the high-voltage bus contactor pre-charge relay.  When this relay is closed, this High Voltage Energy Storage Pack instance is bringing the high-voltage bus up to its operating level.
This parameter is for one of multiple packs in an ...";
CM_ SG_ 2364750334 HVBusDisconnectForewarning "Indicates that this High Voltage Energy Storage Pack instance is about to disconnect from the high voltage bus due to unacceptable conditions.
This parameter is for one of multiple packs in an HVESS. If there is only one pack in the system, the ...";
CM_ SG_ 2364750334 HVBusContactorSt17448 "Position of this High Voltage Energy Storage Pack instance negative side bus contactor. When this contactor is closed, the negative side of this HVES instance is connected to the negative side of the high-voltage bus. If a system controls the ...";
CM_ SG_ 2364750334 HVBusContactorSt "Position of this High Voltage Energy Storage Pack instance positive side bus contactor.  When this contactor is closed, the positive side of this HVES instance is connected to the positive side of the high-voltage bus.  In systems where all ...";
CM_ BO_ 2364750078 "High Voltage Energy Storage Pack 26 Data 6
Data set 6 (external or interface data) for High Voltage Energy Storage Pack 26.";
CM_ SG_ 2364750078 Temp "The temperature of this High Voltage Energy Storage Pack instance. The value may be determined from a unique sensor specifically for this purpose, or by aggregating various temperature sensor readings within the pack.
This parameter is for one of ...";
CM_ SG_ 2364750078 ETemp "The temperature of the electronics or control modules in this High Voltage Energy Storage Pack instance.  If there are multiple temperature sensors then this parameter would be set to the maximum sensor reading.
This parameter is for one of ...";
CM_ SG_ 2364750078 OutCoolantTemp "The temperature of liquid coolant as it exits this High Voltage Energy Storage Pack instance.
This parameter is for one of multiple packs in an HVESS.  If there is only one pack in the system, the HVESS parameters should be used. If there are ...";
CM_ SG_ 2364750078 InCoolantTemp "The temperature of liquid coolant as it enters this High Voltage Energy Storage Pack instance.
This parameter is for one of multiple packs in an HVESS.  If there is only one pack in the system, the HVESS parameters should be used. If there are ...";
CM_ SG_ 2364750078 IgntV "The voltage level at the ignition input of this High Voltage Energy Storage Pack controller.
This parameter is for one of multiple packs in an HVESS.  If there is only one pack in the system, the HVESS parameters should be used.  If there are ...";
CM_ SG_ 2364750078 BusV "The voltage level of the high voltage bus, as measured by this High Voltage Energy Storage Pack instance on the bus side (not the battery side) of its contactors.
This parameter is for one of multiple packs in an HVESS.  If there is only one pack ...";
CM_ BO_ 2364749822 "High Voltage Energy Storage Pack 26 Data 5
Data set 5 (electrical data) for High Voltage Energy Storage Pack 26.";
CM_ SG_ 2364749822 HighestCellStOfCharge "Indicates the state of charge of the highest-charged cell in this High Voltage Energy Storage Pack instance. 0% means no charge remaining, 100% means the cell is fully charged. If a single state of charge value covers more than one cell, the value ...";
CM_ SG_ 2364749822 LowestCellStOfCharge "Indicates the state of charge of the lowest-charged cell in this High Voltage Energy Storage Pack instance. 0% means no charge remaining, 100% means the cell is fully charged. If a single state of charge value covers more than one cell, the value in ...";
CM_ SG_ 2364749822 ChargeCurLmt "The maximum instantaneous current flow limit into this High Voltage Energy Storage Pack instance. This parameter is defined from the high voltage energy storage pack's point of view and should reflect the instantaneous capability of the pack.  The ...";
CM_ SG_ 2364749822 DisCurLmt "The maximum instantaneous current flow limit out of this High Voltage Energy Storage Pack instance. This parameter is defined from the high voltage energy storage pack's point of view and should reflect the instantaneous capability of the pack.  The ...";
CM_ BO_ 2364749566 "High Voltage Energy Storage Pack 26 Data 4
Data set 4 (electrical data) for High Voltage Energy Storage Pack 26.";
CM_ SG_ 2364749566 CellBalancingCount "The number of cells that are currently being balanced in this High Voltage Energy Storage Pack instance.
This parameter is for one of multiple packs in an HVESS.  If there is only one pack in the system, the HVESS parameters should be used.  If ...";
CM_ SG_ 2364749566 ChargeCapacity "The amount of unused electrical charge storage in this High Voltage Energy Storage Pack instance that is available to be filled by charging, i.e. “how much empty space is remaining in the tank”. See SPN 17465 (HVESP26 Charge Energy Capacity) for ...";
CM_ SG_ 2364749566 DisCapacity "The amount of stored electrical charge in this High Voltage Energy Storage Pack instance that is available for use by the hybrid system, i.e. “how full is the tank”. See SPN 17464 (HVESP26 Discharge Energy Capacity) for kilowatt-hours (kWh).
This ...";
CM_ BO_ 2364749310 "High Voltage Energy Storage Pack 26 Data 3
Data set 3 (thermal data) for High Voltage Energy Storage Pack 26.";
CM_ SG_ 2364749310 CellTempDiffStatus "Indicates whether or not the differential between the highest and lowest cell temperatures are within acceptable limits per this High Voltage Energy Storage Pack instance. The actual temperature differential can be calculated by subtracting SPN ...";
CM_ SG_ 2364749310 AvgCellTemp "The average temperature level of all cells in this High Voltage Energy Storage Pack instance.
This parameter is for one of multiple packs in an HVESS.  If there is only one pack in the system, the HVESS parameters should be used.  If there are ...";
CM_ SG_ 2364749310 LowestCellTemp "The lowest temperature level reported by any cell in this High Voltage Energy Storage Pack instance. If a single temperature sensor covers more than one cell, the value in this parameter is for the smallest group of cells measured. See SPN 17514 ...";
CM_ SG_ 2364749310 HighestCellTemp "The highest temperature level reported by any cell in this High Voltage Energy Storage Pack instance. If a single temperature sensor covers more than one cell, the value in this parameter is for the smallest group of cells measured. See SPN 17512 ...";
CM_ BO_ 2364749054 "High Voltage Energy Storage Pack 26 Data 2
Data set 2 (electrical data) for High Voltage Energy Storage Pack 26.";
CM_ SG_ 2364749054 CellVDiffStatus "Indicates whether or not the differential between the highest and lowest cell voltages are within acceptable limits, according to this High Voltage Energy Storage Pack instance. The actual voltage differential can be calculated by subtracting SPN ...";
CM_ SG_ 2364749054 LowestCellV "The lowest voltage level reported by any cell in this High Voltage Energy Storage Pack instance. If a single voltage sensor covers more than one cell, the value in this parameter is for the smallest group of cells measured. See SPN 17509 (HVESP26 ...";
CM_ SG_ 2364749054 HighestCellV "The highest voltage level reported by any cell in this High Voltage Energy Storage Pack instance. If a single voltage sensor covers more than one cell, the value in this parameter is for the smallest group of cells measured. See SPN 17507 (HVESP26 ...";
CM_ SG_ 2364749054 FastUpdateStOfCharge "Indicates this High Voltage Energy Storage Pack instance state of charge. 0% means no charge remaining, 100% means the system is fully charged in terms of physical limits of this energy storage pack instance. Acceptable state of charge upper and ...";
CM_ BO_ 2364748798 "High Voltage Energy Storage Pack 26 Data 1
Data set 1 (electrical data) for High Voltage Energy Storage Pack 26.";
CM_ SG_ 2364748798 Cur "The current in or out of this High Voltage Energy Storage Pack instance. This parameter should be synchronized with SPN 17424 (HVESP26 Voltage Level) such that a realized power value can be calculated. This parameter is defined from the high voltage ...";
CM_ SG_ 2364748798 Lvl "The voltage level of this High Voltage Energy Storage Pack instance. This parameter should be synchronized with SPN 17425 (HVESP26 Current) such that a realized power value can be calculated. If the HVES component physically contains the contactors ...";
CM_ SG_ 2364748798 AvailableChargePwr "The rate at which this High Voltage Energy Storage Pack instance can currently receive energy from a regenerative or recharging system.
This parameter is for one of multiple packs in an HVESS.  If there is only one pack in the system, the HVESS ...";
CM_ SG_ 2364748798 AvailableDisPwr "The rate at which this High Voltage Energy Storage Pack instance can currently provide energy for propulsion or other uses.
This parameter is for one of multiple packs in an HVESS.  If there is only one pack in the system, the HVESS parameters ...";
CM_ BO_ 2364748542 "High Voltage Energy Storage Pack 26 Status 2
Status data set 2 for High Voltage Energy Storage Pack 26.";
CM_ SG_ 2364748542 ChargePLDueToAnUndefinedCause "Indicates whether or not charge power of this HVES instance is being limited due to an undefined cause.
This parameter is for one of multiple packs in an HVESS.  If there is only one pack in the system, the HVESS parameters should be used. If there ...";
CM_ SG_ 2364748542 ChargePLDueToBatCur "Indicates whether or not charge power of this HVES instance is being limited due to battery current.
This parameter is for one of multiple packs in an HVESS.  If there is only one pack in the system, the HVESS parameters should be used. If there ...";
CM_ SG_ 2364748542 ChargePLDueToBatOrCellV "Indicates whether or not charge power of this HVES instance is being limited due to a battery or cell voltage level.
This parameter is for one of multiple packs in an HVESS.  If there is only one pack in the system, the HVESS parameters should be ...";
CM_ SG_ 2364748542 ChargePLDueToBatDiagCondition "Indicates whether or not charge power of this HVES instance is being limited due to a battery diagnostic condition.
This parameter is for one of multiple packs in an HVESS.  If there is only one pack in the system, the HVESS parameters should be ...";
CM_ SG_ 2364748542 ChargePLDueToBatTemp "Indicates whether or not charge power of this HVES instance is being limited due to battery temperature.
This parameter is for one of multiple packs in an HVESS.  If there is only one pack in the system, the HVESS parameters should be used. If ...";
CM_ SG_ 2364748542 ChargePLDueToStOfCharge "Indicates whether or not charge power of this HVES instance is being limited due to state of charge.
This parameter is for one of multiple packs in an HVESS.  If there is only one pack in the system, the HVESS parameters should be used. If there ...";
CM_ SG_ 2364748542 DisPLDueToAnUndefinedCause "Indicates whether or not discharge power of this HVES instance is being limited due to an undefined cause.
This parameter is for one of multiple packs in an HVESS.  If there is only one pack in the system, the HVESS parameters should be used. If ...";
CM_ SG_ 2364748542 DisPLDueToBatCur "Indicates whether or not discharge power of this HVES instance is being limited due to battery current.
This parameter is for one of multiple packs in an HVESS.  If there is only one pack in the system, the HVESS parameters should be used. If there ...";
CM_ SG_ 2364748542 DisPLDueToBatOrCellV "Indicates whether or not discharge power of this HVES instance is being limited due to a battery or cell voltage level.
This parameter is for one of multiple packs in an HVESS.  If there is only one pack in the system, the HVESS parameters should ...";
CM_ SG_ 2364748542 DisPLDueToBatDiagCondition "Indicates whether or not discharge power of this HVES instance is being limited due to a battery diagnostic condition.
This parameter is for one of multiple packs in an HVESS.  If there is only one pack in the system, the HVESS parameters should be ...";
CM_ SG_ 2364748542 DisPLDueToBatTemp "Indicates whether or not discharge power of this HVES instance is being limited due to battery temperature.
This parameter is for one of multiple packs in an HVESS.  If there is only one pack in the system, the HVESS parameters should be used. If ...";
CM_ SG_ 2364748542 DisPLDueToStOfCharge "Indicates whether or not discharge power of this HVES instance is being limited due to state of charge.
This parameter is for one of multiple packs in an HVESS.  If there is only one pack in the system, the HVESS parameters should be used. If there ...";
CM_ BO_ 2364748286 "High Voltage Energy Storage Pack 25 Data 11
Data set 11 (electrical data) for High Voltage Energy Storage Pack 25.";
CM_ SG_ 2364748286 ActualChargeRate "This signal represents the actual present charge rate of this High Voltage Energy Storage Pack instance.
This parameter is for one of multiple packs in an HVESS. If there is only one pack in the system, the HVESS parameters should be used. If there ...";
CM_ SG_ 2364748286 LvlNegToChassisGroundV "Voltage difference between the most negative terminal of the HVES battery and chassis measured at the battery side of any HVES contained output contactor.  This voltage may be used for system level monitoring of battery shorts to chassis within the ...";
CM_ SG_ 2364748286 BusVNegToChassisGroundV "Voltage difference between the most negative terminal of the HVES battery and chassis measured on the hybrid system bus side (not the battery side) of any HVES contained output contactor.  This voltage may be used for system level monitoring of ...";
CM_ BO_ 2364748030 "High Voltage Energy Storage Pack 25 Data 10
Data set 10 (electrical) for High Voltage Energy Storage Pack 25.";
CM_ SG_ 2364748030 HVBusPassiveIsolTestResults "The isolation resistance expressed in Ohms per Volt that resulted from the High-Voltage Bus Passive Isolation Test.
See SPN 17311 (HVESP25 High-Voltage Bus Passive Isolation Test Status) for test status and SPN 17260 (HVESP25 High-Voltage Bus ...";
CM_ SG_ 2364748030 HVBusActiveIsolTestResults "The isolation resistance expressed in Ohms per Volt that resulted from the High-Voltage Bus Active Isolation Test.
See SPN 17310 (HVESP25 High-Voltage Bus Active Isolation Test Status) for test status and SPN 17259 (HVESP25 High-Voltage Bus Active ...";
CM_ SG_ 2364748030 LowestCellStOfChargeCellNum "Identifies the location of SPN 17297 (HVESP25 Lowest Cell State of Charge) within SPN 17376 (HVESP25 Lowest Cell State of Charge Module Number).
This parameter is for one of multiple packs in an HVESS. If there is only one pack in the system, the ...";
CM_ SG_ 2364748030 LowestCellStOfChargeModuleNum "Identifies the location of the module containing SPN 17297 (HVESP25 Lowest Cell State of Charge).
This parameter is for one of multiple packs in an HVESS. If there is only one pack in the system, the HVESS parameters should be used. If there are ...";
CM_ SG_ 2364748030 HighestCellStOfChargeCellNum "Identifies the location of SPN 17298 (HVESP25 Highest Cell State of Charge) within SPN 17374 (HVESP25 Highest Cell State of Charge Module Number).
This parameter is for one of multiple packs in an HVESS. If there is only one pack in the system, the ...";
CM_ SG_ 2364748030 HighestCellStOfChargeModuleNum "Identifies the location of the module containing SPN 17298 (HVESP25 Highest Cell State of Charge).
This parameter is for one of multiple packs in an HVESS. If there is only one pack in the system, the HVESS parameters should be used. If there are ...";
CM_ BO_ 2364747774 "High Voltage Energy Storage Pack 25 Data 9
Data set 9 (thermal) for High Voltage Energy Storage Pack 25.";
CM_ SG_ 2364747774 Data9CRC "The CRC is defined as follows:
• Length: 8 bits
• Polynomial: x^8+x^5+x^3+x^2+x+1
• Initial Value: FFh
• Input Data Reflection: Not reflected
• Result Data Reflection: Not reflected
• XOR value: FFh
SAE makes no claim of the functional safety ...";
CM_ SG_ 2364747774 Data9Counter "The message counter is used to detect situations where the transmitting ECU malfunction repeats the same frame all the time. The receiver of the information may use the counter parameter to detect this situation. The transmitting device will ...";
CM_ SG_ 2364747774 Data9EmbeddedIntegritySupport "Indicates SPN 23048 (HVESP25 Data 9 CRC) and SPN 23047 (HVESP25 Data 9 Counter) are supported by the sender.
00b = Embedded CRC and Counter are supported by the sender
01b = Protection is supported using J1939-76 SHM
10b = Reserved
11b = CRC and ...";
CM_ SG_ 2364747774 HVESS25ThermalEventDetected "A sensor has detected the presence of a thermal event at or near High Voltage Energy Storage Pack instance.
00b = No Thermal Event Detected
01b = Thermal Event Detected
10b = Error
11b = Not available
This parameter is for one of multiple packs ...";
CM_ SG_ 2364747774 LowestCellTempCellNum "Identifies the location of SPN 17289 (HVESP25 Lowest Cell Temperature) within SPN 17372 (HVESP25 Lowest Cell Temperature Module Number).
This parameter is for one of multiple packs in an HVESS. If there is only one pack in the system, the HVESS ...";
CM_ SG_ 2364747774 LowestCellTempModuleNum "Identifies the location of the module containing SPN 17289 (HVESP25 Lowest Cell Temperature).
This parameter is for one of multiple packs in an HVESS. If there is only one pack in the system, the HVESS parameters should be used. If there are ...";
CM_ SG_ 2364747774 HighestCellTempCellNum "Identifies the location of SPN 17288 (HVESP25 Highest Cell Temperature) within SPN 17370 (HVESP25 Highest Cell Temperature Module Number).
This parameter is for one of multiple packs in an HVESS. If there is only one pack in the system, the HVESS ...";
CM_ SG_ 2364747774 HighestCellTempModuleNum "Identifies the location of the module containing SPN 17288 (HVESP25 Highest Cell Temperature).
This parameter is for one of multiple packs in an HVESS. If there is only one pack in the system, the HVESS parameters should be used. If there are ...";
CM_ BO_ 2364747518 "High Voltage Energy Storage Pack 25 Data 8
Data set 8 (electrical data) for High Voltage Energy Storage Pack 25.";
CM_ SG_ 2364747518 AvgCellV "The average cell voltage in this High Voltage Energy Storage Pack instance.
This parameter is for one of multiple packs in an HVESS.  If there is only one pack in the system, the HVESS parameters should be used. If there are multiple packs in the ...";
CM_ SG_ 2364747518 LowestCellVCellNum "Identifies the location of SPN 17286 (HVESP25 Lowest Cell Voltage) within SPN 17367 (HVESP25 Lowest Cell Voltage Module Number).
This parameter is for one of multiple packs in an HVESS. If there is only one pack in the system, the HVESS parameters ...";
CM_ SG_ 2364747518 LowestCellVModuleNum "Identifies the location of the module containing SPN 17286 (HVESP25 Lowest Cell Voltage).
This parameter is for one of multiple packs in an HVESS. If there is only one pack in the system, the HVESS parameters should be used. If there are multiple ...";
CM_ SG_ 2364747518 HighestCellVCellNum "Identifies the location of SPN 17285 (HVESP25 Highest Cell Voltage) within SPN 17365 (HVESP25 Highest Cell Voltage Module Number).
This parameter is for one of multiple packs in an HVESS. If there is only one pack in the system, the HVESS ...";
CM_ SG_ 2364747518 HighestCellVModuleNum "Identifies the location of the module containing SPN 17285 (HVESP25 Highest Cell Voltage).
This parameter is for one of multiple packs in an HVESS. If there is only one pack in the system, the HVESS parameters should be used. If there are multiple ...";
CM_ BO_ 2364747262 "High Voltage Energy Storage Pack 25 Thermal Management System Status 1
Collection of data the High Voltage Energy Storage Pack 25 Thermal Management System sends to the Hybrid Controller.";
CM_ SG_ 2364747262 TMSCoolantLvl "Indicates the coolant level in this HVES Thermal Management System (TMS).
This parameter is for one of multiple packs in an HVESS.  If there is only one pack in the system, the HVESS parameters should be used. If there are multiple packs in the ...";
CM_ SG_ 2364747262 TMSMode "Indicates the operating mode of the Thermal Management System.  The heat transfer medium may be (e.g. liquid or air).  The cooling system may be fans, liquid coolant, or a combination of mediums.  The system may include an air and/or liquid ...";
CM_ SG_ 2364747262 TMSHVILStatus "In multiple HVES configurations, this is the status of the High Voltage Interlock Loop from the viewpoint of this Thermal Management System.
00b = HVIL Closed
01b = HVIL Open
10b = Error
11b = Not Available
This parameter is for one of multiple ...";
CM_ SG_ 2364747262 TMSHtrStatus "The state of this High Voltage Energy Storage Pack heater
This parameter is for one of multiple packs in an HVESS.  If there is only one pack in the system, the HVESS parameters should be used. If there are multiple packs in the system, then both ...";
CM_ SG_ 2364747262 TMSRelHumidty "When this High Voltage Energy Storage Pack Thermal Management System is equipped with a relative humidity sensor, this is the  measured Relative Humidity.
This parameter is for one of multiple packs in an HVESS.  If there is only one pack in the ...";
CM_ SG_ 2364747262 TMSCompressorSpd "When this High Voltage Energy Storage Pack Thermal Management System is equipped with an active cooling system (e.g. air conditioner), this is the Compressor Speed.
This parameter is for one of multiple packs in an HVESS.  If there is only one pack ...";
CM_ SG_ 2364747262 TMSHVInputPwr "This is the high-voltage power consumed by this HVES Thermal Management System (TMS).
This parameter is for one of multiple packs in an HVESS.  If there is only one pack in the system, the HVESS parameters should be used. If there are multiple ...";
CM_ SG_ 2364747262 TMSSLIInputPwr "This is the low-voltage power consumed by this HVES Thermal Management System (TMS).
This parameter is for one of multiple packs in an HVESS.  If there is only one pack in the system, the HVESS parameters should be used.  If there are multiple ...";
CM_ BO_ 2364747006 "High Voltage Energy Storage Pack 25 Module Status 1
Module Status message 1 for High Voltage Energy Storage Pack 25.";
CM_ SG_ 2364747006 Module32OperationalStatus "Operational Status of Module 32 in this High Voltage Energy Storage Pack Instance.  Not Operational is used when the module is initializing or not able to function (e.g. internal module level monitors have failed).  Operational indicates that the ...";
CM_ SG_ 2364747006 Module31OperationalStatus "Operational Status of Module 31 in this High Voltage Energy Storage Pack Instance.  Not Operational is used when the module is initializing or not able to function (e.g. internal module level monitors have failed).  Operational indicates that the ...";
CM_ SG_ 2364747006 Module30OperationalStatus "Operational Status of Module 30 in this High Voltage Energy Storage Pack Instance.  Not Operational is used when the module is initializing or not able to function (e.g. internal module level monitors have failed).  Operational indicates that the ...";
CM_ SG_ 2364747006 Module29OperationalStatus "Operational Status of Module 29 in this High Voltage Energy Storage Pack Instance.  Not Operational is used when the module is initializing or not able to function (e.g. internal module level monitors have failed).  Operational indicates that the ...";
CM_ SG_ 2364747006 Module28OperationalStatus "Operational Status of Module 28 in this High Voltage Energy Storage Pack Instance.  Not Operational is used when the module is initializing or not able to function (e.g. internal module level monitors have failed).  Operational indicates that the ...";
CM_ SG_ 2364747006 Module27OperationalStatus "Operational Status of Module 27 in this High Voltage Energy Storage Pack Instance.  Not Operational is used when the module is initializing or not able to function (e.g. internal module level monitors have failed).  Operational indicates that the ...";
CM_ SG_ 2364747006 Module26OperationalStatus "Operational Status of Module 26 in this High Voltage Energy Storage Pack Instance.  Not Operational is used when the module is initializing or not able to function (e.g. internal module level monitors have failed).  Operational indicates that the ...";
CM_ SG_ 2364747006 Module25OperationalStatus "Operational Status of Module 25 in this High Voltage Energy Storage Pack Instance.  Not Operational is used when the module is initializing or not able to function (e.g. internal module level monitors have failed).  Operational indicates that the ...";
CM_ SG_ 2364747006 Module24OperationalStatus "Operational Status of Module 24 in this High Voltage Energy Storage Pack Instance.  Not Operational is used when the module is initializing or not able to function (e.g. internal module level monitors have failed).  Operational indicates that the ...";
CM_ SG_ 2364747006 Module23OperationalStatus "Operational Status of Module 23 in this High Voltage Energy Storage Pack Instance.  Not Operational is used when the module is initializing or not able to function (e.g. internal module level monitors have failed).  Operational indicates that the ...";
CM_ SG_ 2364747006 Module22OperationalStatus "Operational Status of Module 22 in this High Voltage Energy Storage Pack Instance.  Not Operational is used when the module is initializing or not able to function (e.g. internal module level monitors have failed).  Operational indicates that the ...";
CM_ SG_ 2364747006 Module21OperationalStatus "Operational Status of Module 21 in this High Voltage Energy Storage Pack Instance.  Not Operational is used when the module is initializing or not able to function (e.g. internal module level monitors have failed).  Operational indicates that the ...";
CM_ SG_ 2364747006 Module20OperationalStatus "Operational Status of Module 20 in this High Voltage Energy Storage Pack Instance.  Not Operational is used when the module is initializing or not able to function (e.g. internal module level monitors have failed).  Operational indicates that the ...";
CM_ SG_ 2364747006 Module19OperationalStatus "Operational Status of Module 19 in this High Voltage Energy Storage Pack Instance.  Not Operational is used when the module is initializing or not able to function (e.g. internal module level monitors have failed).  Operational indicates that the ...";
CM_ SG_ 2364747006 Module18OperationalStatus "Operational Status of Module 18 in this High Voltage Energy Storage Pack Instance.  Not Operational is used when the module is initializing or not able to function (e.g. internal module level monitors have failed).  Operational indicates that the ...";
CM_ SG_ 2364747006 Module17OperationalStatus "Operational Status of Module 17 in this High Voltage Energy Storage Pack Instance.  Not Operational is used when the module is initializing or not able to function (e.g. internal module level monitors have failed).  Operational indicates that the ...";
CM_ SG_ 2364747006 Module16OperationalStatus "Operational Status of Module 16 in this High Voltage Energy Storage Pack Instance.  Not Operational is used when the module is initializing or not able to function (e.g. internal module level monitors have failed).  Operational indicates that the ...";
CM_ SG_ 2364747006 Module15OperationalStatus "Operational Status of Module 15 in this High Voltage Energy Storage Pack Instance.  Not Operational is used when the module is initializing or not able to function (e.g. internal module level monitors have failed).  Operational indicates that the ...";
CM_ SG_ 2364747006 Module14OperationalStatus "Operational Status of Module 14 in this High Voltage Energy Storage Pack Instance.  Not Operational is used when the module is initializing or not able to function (e.g. internal module level monitors have failed).  Operational indicates that the ...";
CM_ SG_ 2364747006 Module13OperationalStatus "Operational Status of Module 13 in this High Voltage Energy Storage Pack Instance.  Not Operational is used when the module is initializing or not able to function (e.g. internal module level monitors have failed).  Operational indicates that the ...";
CM_ SG_ 2364747006 Module12OperationalStatus "Operational Status of Module 12 in this High Voltage Energy Storage Pack Instance.  Not Operational is used when the module is initializing or not able to function (e.g. internal module level monitors have failed).  Operational indicates that the ...";
CM_ SG_ 2364747006 Module11OperationalStatus "Operational Status of Module 11 in this High Voltage Energy Storage Pack Instance.  Not Operational is used when the module is initializing or not able to function (e.g. internal module level monitors have failed).  Operational indicates that the ...";
CM_ SG_ 2364747006 Module10OperationalStatus "Operational Status of Module 10 in this High Voltage Energy Storage Pack Instance.  Not Operational is used when the module is initializing or not able to function (e.g. internal module level monitors have failed).  Operational indicates that the ...";
CM_ SG_ 2364747006 Module9OperationalStatus "Operational Status of Module 9 in this High Voltage Energy Storage Pack Instance.  Not Operational is used when the module is initializing or not able to function (e.g. internal module level monitors have failed).  Operational indicates that the ...";
CM_ SG_ 2364747006 Module8OperationalStatus "Operational Status of Module 8 in this High Voltage Energy Storage Pack Instance.  Not Operational is used when the module is initializing or not able to function (e.g. internal module level monitors have failed).  Operational indicates that the ...";
CM_ SG_ 2364747006 Module7OperationalStatus "Operational Status of Module 7 in this High Voltage Energy Storage Pack Instance.  Not Operational is used when the module is initializing or not able to function (e.g. internal module level monitors have failed).  Operational indicates that the ...";
CM_ SG_ 2364747006 Module6OperationalStatus "Operational Status of Module 6 in this High Voltage Energy Storage Pack Instance.  Not Operational is used when the module is initializing or not able to function (e.g. internal module level monitors have failed).  Operational indicates that the ...";
CM_ SG_ 2364747006 Module5OperationalStatus "Operational Status of Module 5 in this High Voltage Energy Storage Pack Instance.  Not Operational is used when the module is initializing or not able to function (e.g. internal module level monitors have failed).  Operational indicates that the ...";
CM_ SG_ 2364747006 Module4OperationalStatus "Operational Status of Module 4 in this High Voltage Energy Storage Pack Instance.  Not Operational is used when the module is initializing or not able to function (e.g. internal module level monitors have failed).  Operational indicates that the ...";
CM_ SG_ 2364747006 Module3OperationalStatus "Operational Status of Module 3 in this High Voltage Energy Storage Pack Instance.  Not Operational is used when the module is initializing or not able to function (e.g. internal module level monitors have failed).  Operational indicates that the ...";
CM_ SG_ 2364747006 Module2OperationalStatus "Operational Status of Module 2 in this High Voltage Energy Storage Pack Instance.  Not Operational is used when the module is initializing or not able to function (e.g. internal module level monitors have failed).  Operational indicates that the ...";
CM_ SG_ 2364747006 Module1OperationalStatus "Operational Status of Module 1 in this High Voltage Energy Storage Pack Instance.  Not Operational is used when the module is initializing or not able to function (e.g. internal module level monitors have failed).  Operational indicates that the ...";
CM_ BO_ 2364746750 "High Voltage Energy Storage Pack 25 Data 7
Data set 7 (electrical) for High Voltage Energy Storage Pack 25.";
CM_ SG_ 2364746750 MaxChargeVLmt "The maximum voltage level not to be exceeded while charging this High Voltage Energy Storage Pack instance. If this parameter is not supported, the maximum charge voltage should be limited to SPN 17391 (HVESP25 Recommended Maximum Operating ...";
CM_ SG_ 2364746750 ChargeEnergyCapacity "The amount of unused electrical energy storage available to be filled by charging this High Voltage Energy Storage Pack instance, i.e. “how much empty space is remaining in the tank”. See SPN 17293 (HVESP25 Charge Capacity) for Ampere-hours (Ah).
 ...";
CM_ SG_ 2364746750 DisEnergyCapacity "The amount of stored electrical energy in this High Voltage Energy Storage Pack instance that is available for use by the hybrid system, i.e. “how full is the tank”. See SPN 17292 (HVESP25 Discharge Capacity) for Ampere-hours (Ah).
This parameter ...";
CM_ BO_ 2364746494 "High Voltage Energy Storage Pack 25 Status 1
Status data set 1 for High Voltage Energy Storage Pack 25.";
CM_ SG_ 2364746494 Status1CRC "The CRC is defined as follows:
• Length: 8 bits
• Polynomial: x^8+x^5+x^3+x^2+x+1
• Initial Value: FFh
• Input Data Reflection: Not reflected
• Result Data Reflection: Not reflected
• XOR value: FFh
SAE makes no claim of the functional safety ...";
CM_ SG_ 2364746494 Status1Counter "The message counter is used to detect situations where the transmitting ECU malfunction repeats the same frame all the time. The receiver of the information may use the counter parameter to detect this situation. The transmitting device will ...";
CM_ SG_ 2364746494 OperationalStatus "Provides feedback on where this High Voltage Energy Storage Pack instance is in its operating spectrum, and includes feedback in response to the Operation Consent [i.e. SPN 17263 (HVESP25 Operation Consent)] and Power Down Command [i.e. SPN 17258 ...";
CM_ SG_ 2364746494 HVBusConnectionStatus "This parameter provides high level feedback on this High Voltage Energy Storage Pack instance high voltage bus connection. For specific contactor information, see SPN 17305 (HVESP25 High-Voltage Bus (Positive) Contactor State), SPN 17306 (HVESP25 ...";
CM_ SG_ 2364746494 InternalChargerStatus "Indicates that the charger in this HVES instance is on.  External chargers may use the External Energy Source Connection Status (SPN 7898) and related SPs.
This parameter is for one of multiple packs in an HVESS. If there is only one pack in the ...";
CM_ SG_ 2364746494 CellBalancingActive "Indicates whether or not the cells in this High Voltage Energy Storage Pack instance are currently being balanced.
This parameter is for one of multiple packs in an HVESS.  If there is only one pack in the system, the HVESS parameters should be ...";
CM_ SG_ 2364746494 CellBalanceStatus "Indicates whether or not the cells in this High Voltage Energy Storage Pack instance are balanced.
This parameter is for one of multiple packs in an HVESS.  If there is only one pack in the system, the HVESS parameters should be used. If there are ...";
CM_ SG_ 2364746494 StOfChargeStatus "Status of this High Voltage Energy Storage Pack instance State of Charge (SOC).  Note:  A given HVES controller may not support all of the states.
This parameter is for one of multiple packs in an HVESS.  If there is only one pack in the system, ...";
CM_ SG_ 2364746494 InertiaSwStatus "Switch indicating that an impact has been sensed by this High Voltage Energy Storage Pack instance. The impact indication may require action by another controller, or by this HVES instance itself.  For example, a controller may elect to take this ...";
CM_ SG_ 2364746494 HVILStatus "Status of the High Voltage Interlock Loop from the viewpoint of this High Voltage Energy Storage Pack instance.
This parameter is for one of multiple packs in an HVESS. If there is only one pack in the system, the HVESS parameters should be used ...";
CM_ SG_ 2364746494 HVBusPassiveIsolTestStatus "Status of the high-voltage bus electrical passive isolation test as performed by this High Voltage Energy Storage Pack instance.
This parameter is for one of multiple packs in an HVESS. If there is only one pack in the system, the HVESS parameters ...";
CM_ SG_ 2364746494 HVBusActiveIsolTestStatus "Status of the high-voltage bus electrical active isolation test as performed by this High Voltage Energy Storage Pack instance.
This parameter is for one of multiple packs in an HVESS. If there is only one pack in the system, the HVESS parameters ...";
CM_ SG_ 2364746494 CenterOfPackContactorSt "Position of the center high-voltage contactor. When this contactor is closed, the positive half of this High Voltage Energy Storage Pack instance is connected to the negative half. If a system controls the positive, negative, and center contactors ...";
CM_ SG_ 2364746494 HVBusPreChargeRelaySt "Position of the high-voltage bus contactor pre-charge relay.  When this relay is closed, this High Voltage Energy Storage Pack instance is bringing the high-voltage bus up to its operating level.
This parameter is for one of multiple packs in an ...";
CM_ SG_ 2364746494 HVBusDisconnectForewarning "Indicates that this High Voltage Energy Storage Pack instance is about to disconnect from the high voltage bus due to unacceptable conditions.
This parameter is for one of multiple packs in an HVESS. If there is only one pack in the system, the ...";
CM_ SG_ 2364746494 HVBusContactorSt17306 "Position of this High Voltage Energy Storage Pack instance negative side bus contactor. When this contactor is closed, the negative side of this HVES instance is connected to the negative side of the high-voltage bus. If a system controls the ...";
CM_ SG_ 2364746494 HVBusContactorSt "Position of this High Voltage Energy Storage Pack instance positive side bus contactor.  When this contactor is closed, the positive side of this HVES instance is connected to the positive side of the high-voltage bus.  In systems where all ...";
CM_ BO_ 2364746238 "High Voltage Energy Storage Pack 25 Data 6
Data set 6 (external or interface data) for High Voltage Energy Storage Pack 25.";
CM_ SG_ 2364746238 Temp "The temperature of this High Voltage Energy Storage Pack instance. The value may be determined from a unique sensor specifically for this purpose, or by aggregating various temperature sensor readings within the pack.
This parameter is for one of ...";
CM_ SG_ 2364746238 ETemp "The temperature of the electronics or control modules in this High Voltage Energy Storage Pack instance.  If there are multiple temperature sensors then this parameter would be set to the maximum sensor reading.
This parameter is for one of ...";
CM_ SG_ 2364746238 OutCoolantTemp "The temperature of liquid coolant as it exits this High Voltage Energy Storage Pack instance.
This parameter is for one of multiple packs in an HVESS.  If there is only one pack in the system, the HVESS parameters should be used. If there are ...";
CM_ SG_ 2364746238 InCoolantTemp "The temperature of liquid coolant as it enters this High Voltage Energy Storage Pack instance.
This parameter is for one of multiple packs in an HVESS.  If there is only one pack in the system, the HVESS parameters should be used. If there are ...";
CM_ SG_ 2364746238 IgntV "The voltage level at the ignition input of this High Voltage Energy Storage Pack controller.
This parameter is for one of multiple packs in an HVESS.  If there is only one pack in the system, the HVESS parameters should be used.  If there are ...";
CM_ SG_ 2364746238 BusV "The voltage level of the high voltage bus, as measured by this High Voltage Energy Storage Pack instance on the bus side (not the battery side) of its contactors.
This parameter is for one of multiple packs in an HVESS.  If there is only one pack ...";
CM_ BO_ 2364745982 "High Voltage Energy Storage Pack 25 Data 5
Data set 5 (electrical data) for High Voltage Energy Storage Pack 25.";
CM_ SG_ 2364745982 HighestCellStOfCharge "Indicates the state of charge of the highest-charged cell in this High Voltage Energy Storage Pack instance. 0% means no charge remaining, 100% means the cell is fully charged. If a single state of charge value covers more than one cell, the value ...";
CM_ SG_ 2364745982 LowestCellStOfCharge "Indicates the state of charge of the lowest-charged cell in this High Voltage Energy Storage Pack instance. 0% means no charge remaining, 100% means the cell is fully charged. If a single state of charge value covers more than one cell, the value in ...";
CM_ SG_ 2364745982 ChargeCurLmt "The maximum instantaneous current flow limit into this High Voltage Energy Storage Pack instance. This parameter is defined from the high voltage energy storage pack's point of view and should reflect the instantaneous capability of the pack.  The ...";
CM_ SG_ 2364745982 DisCurLmt "The maximum instantaneous current flow limit out of this High Voltage Energy Storage Pack instance. This parameter is defined from the high voltage energy storage pack's point of view and should reflect the instantaneous capability of the pack.  The ...";
CM_ BO_ 2364745726 "High Voltage Energy Storage Pack 25 Data 4
Data set 4 (electrical data) for High Voltage Energy Storage Pack 25.";
CM_ SG_ 2364745726 CellBalancingCount "The number of cells that are currently being balanced in this High Voltage Energy Storage Pack instance.
This parameter is for one of multiple packs in an HVESS.  If there is only one pack in the system, the HVESS parameters should be used.  If ...";
CM_ SG_ 2364745726 ChargeCapacity "The amount of unused electrical charge storage in this High Voltage Energy Storage Pack instance that is available to be filled by charging, i.e. “how much empty space is remaining in the tank”. See SPN 17323 (HVESP25 Charge Energy Capacity) for ...";
CM_ SG_ 2364745726 DisCapacity "The amount of stored electrical charge in this High Voltage Energy Storage Pack instance that is available for use by the hybrid system, i.e. “how full is the tank”. See SPN 17322 (HVESP25 Discharge Energy Capacity) for kilowatt-hours (kWh).
This ...";
CM_ BO_ 2364745470 "High Voltage Energy Storage Pack 25 Data 3
Data set 3 (thermal data) for High Voltage Energy Storage Pack 25.";
CM_ SG_ 2364745470 CellTempDiffStatus "Indicates whether or not the differential between the highest and lowest cell temperatures are within acceptable limits per this High Voltage Energy Storage Pack instance. The actual temperature differential can be calculated by subtracting SPN ...";
CM_ SG_ 2364745470 AvgCellTemp "The average temperature level of all cells in this High Voltage Energy Storage Pack instance.
This parameter is for one of multiple packs in an HVESS.  If there is only one pack in the system, the HVESS parameters should be used.  If there are ...";
CM_ SG_ 2364745470 LowestCellTemp "The lowest temperature level reported by any cell in this High Voltage Energy Storage Pack instance. If a single temperature sensor covers more than one cell, the value in this parameter is for the smallest group of cells measured. See SPN 17372 ...";
CM_ SG_ 2364745470 HighestCellTemp "The highest temperature level reported by any cell in this High Voltage Energy Storage Pack instance. If a single temperature sensor covers more than one cell, the value in this parameter is for the smallest group of cells measured. See SPN 17370 ...";
CM_ BO_ 2364745214 "High Voltage Energy Storage Pack 25 Data 2
Data set 2 (electrical data) for High Voltage Energy Storage Pack 25.";
CM_ SG_ 2364745214 CellVDiffStatus "Indicates whether or not the differential between the highest and lowest cell voltages are within acceptable limits, according to this High Voltage Energy Storage Pack instance. The actual voltage differential can be calculated by subtracting SPN ...";
CM_ SG_ 2364745214 LowestCellV "The lowest voltage level reported by any cell in this High Voltage Energy Storage Pack instance. If a single voltage sensor covers more than one cell, the value in this parameter is for the smallest group of cells measured. See SPN 17367 (HVESP25 ...";
CM_ SG_ 2364745214 HighestCellV "The highest voltage level reported by any cell in this High Voltage Energy Storage Pack instance. If a single voltage sensor covers more than one cell, the value in this parameter is for the smallest group of cells measured. See SPN 17365 (HVESP25 ...";
CM_ SG_ 2364745214 FastUpdateStOfCharge "Indicates this High Voltage Energy Storage Pack instance state of charge. 0% means no charge remaining, 100% means the system is fully charged in terms of physical limits of this energy storage pack instance. Acceptable state of charge upper and ...";
CM_ BO_ 2364744958 "High Voltage Energy Storage Pack 25 Data 1
Data set 1 (electrical data) for High Voltage Energy Storage Pack 25.";
CM_ SG_ 2364744958 Cur "The current in or out of this High Voltage Energy Storage Pack instance. This parameter should be synchronized with SPN 17282 (HVESP25 Voltage Level) such that a realized power value can be calculated. This parameter is defined from the high voltage ...";
CM_ SG_ 2364744958 Lvl "The voltage level of this High Voltage Energy Storage Pack instance. This parameter should be synchronized with SPN 17283 (HVESP25 Current) such that a realized power value can be calculated. If the HVES component physically contains the contactors ...";
CM_ SG_ 2364744958 AvailableChargePwr "The rate at which this High Voltage Energy Storage Pack instance can currently receive energy from a regenerative or recharging system.
This parameter is for one of multiple packs in an HVESS.  If there is only one pack in the system, the HVESS ...";
CM_ SG_ 2364744958 AvailableDisPwr "The rate at which this High Voltage Energy Storage Pack instance can currently provide energy for propulsion or other uses.
This parameter is for one of multiple packs in an HVESS.  If there is only one pack in the system, the HVESS parameters ...";
CM_ BO_ 2364744702 "High Voltage Energy Storage Pack 25 Status 2
Status data set 2 for High Voltage Energy Storage Pack 25.";
CM_ SG_ 2364744702 ChargePLDueToAnUndefinedCause "Indicates whether or not charge power of this HVES instance is being limited due to an undefined cause.
This parameter is for one of multiple packs in an HVESS.  If there is only one pack in the system, the HVESS parameters should be used. If there ...";
CM_ SG_ 2364744702 ChargePLDueToBatCur "Indicates whether or not charge power of this HVES instance is being limited due to battery current.
This parameter is for one of multiple packs in an HVESS.  If there is only one pack in the system, the HVESS parameters should be used. If there ...";
CM_ SG_ 2364744702 ChargePLDueToBatOrCellV "Indicates whether or not charge power of this HVES instance is being limited due to a battery or cell voltage level.
This parameter is for one of multiple packs in an HVESS.  If there is only one pack in the system, the HVESS parameters should be ...";
CM_ SG_ 2364744702 ChargePLDueToBatDiagCondition "Indicates whether or not charge power of this HVES instance is being limited due to a battery diagnostic condition.
This parameter is for one of multiple packs in an HVESS.  If there is only one pack in the system, the HVESS parameters should be ...";
CM_ SG_ 2364744702 ChargePLDueToBatTemp "Indicates whether or not charge power of this HVES instance is being limited due to battery temperature.
This parameter is for one of multiple packs in an HVESS.  If there is only one pack in the system, the HVESS parameters should be used. If ...";
CM_ SG_ 2364744702 ChargePLDueToStOfCharge "Indicates whether or not charge power of this HVES instance is being limited due to state of charge.
This parameter is for one of multiple packs in an HVESS.  If there is only one pack in the system, the HVESS parameters should be used. If there ...";
CM_ SG_ 2364744702 DisPLDueToAnUndefinedCause "Indicates whether or not discharge power of this HVES instance is being limited due to an undefined cause.
This parameter is for one of multiple packs in an HVESS.  If there is only one pack in the system, the HVESS parameters should be used. If ...";
CM_ SG_ 2364744702 DisPLDueToBatCur "Indicates whether or not discharge power of this HVES instance is being limited due to battery current.
This parameter is for one of multiple packs in an HVESS.  If there is only one pack in the system, the HVESS parameters should be used. If there ...";
CM_ SG_ 2364744702 DisPLDueToBatOrCellV "Indicates whether or not discharge power of this HVES instance is being limited due to a battery or cell voltage level.
This parameter is for one of multiple packs in an HVESS.  If there is only one pack in the system, the HVESS parameters should ...";
CM_ SG_ 2364744702 DisPLDueToBatDiagCondition "Indicates whether or not discharge power of this HVES instance is being limited due to a battery diagnostic condition.
This parameter is for one of multiple packs in an HVESS.  If there is only one pack in the system, the HVESS parameters should be ...";
CM_ SG_ 2364744702 DisPLDueToBatTemp "Indicates whether or not discharge power of this HVES instance is being limited due to battery temperature.
This parameter is for one of multiple packs in an HVESS.  If there is only one pack in the system, the HVESS parameters should be used. If ...";
CM_ SG_ 2364744702 DisPLDueToStOfCharge "Indicates whether or not discharge power of this HVES instance is being limited due to state of charge.
This parameter is for one of multiple packs in an HVESS.  If there is only one pack in the system, the HVESS parameters should be used. If there ...";
CM_ BO_ 2364744446 "High Voltage Energy Storage Pack 24 Data 11
Data set 11 (electrical data) for High Voltage Energy Storage Pack 24.";
CM_ SG_ 2364744446 ActualChargeRate "This signal represents the actual present charge rate of this High Voltage Energy Storage Pack instance.
This parameter is for one of multiple packs in an HVESS. If there is only one pack in the system, the HVESS parameters should be used. If there ...";
CM_ SG_ 2364744446 LvlNegToChassisGroundV "Voltage difference between the most negative terminal of the HVES battery and chassis measured at the battery side of any HVES contained output contactor.  This voltage may be used for system level monitoring of battery shorts to chassis within the ...";
CM_ SG_ 2364744446 BusVNegToChassisGroundV "Voltage difference between the most negative terminal of the HVES battery and chassis measured on the hybrid system bus side (not the battery side) of any HVES contained output contactor.  This voltage may be used for system level monitoring of ...";
CM_ BO_ 2364744190 "High Voltage Energy Storage Pack 24 Data 10
Data set 10 (electrical) for High Voltage Energy Storage Pack 24.";
CM_ SG_ 2364744190 HVBusPassiveIsolTestResults "The isolation resistance expressed in Ohms per Volt that resulted from the High-Voltage Bus Passive Isolation Test.
See SPN 17169 (HVESP24 High-Voltage Bus Passive Isolation Test Status) for test status and SPN 17118 (HVESP24 High-Voltage Bus ...";
CM_ SG_ 2364744190 HVBusActiveIsolTestResults "The isolation resistance expressed in Ohms per Volt that resulted from the High-Voltage Bus Active Isolation Test.
See SPN 17168 (HVESP24 High-Voltage Bus Active Isolation Test Status) for test status and SPN 17117 (HVESP24 High-Voltage Bus Active ...";
CM_ SG_ 2364744190 LowestCellStOfChargeCellNum "Identifies the location of SPN 17155 (HVESP24 Lowest Cell State of Charge) within SPN 17234 (HVESP24 Lowest Cell State of Charge Module Number).
This parameter is for one of multiple packs in an HVESS. If there is only one pack in the system, the ...";
CM_ SG_ 2364744190 LowestCellStOfChargeModuleNum "Identifies the location of the module containing SPN 17155 (HVESP24 Lowest Cell State of Charge).
This parameter is for one of multiple packs in an HVESS. If there is only one pack in the system, the HVESS parameters should be used. If there are ...";
CM_ SG_ 2364744190 HighestCellStOfChargeCellNum "Identifies the location of SPN 17156 (HVESP24 Highest Cell State of Charge) within SPN 17232 (HVESP24 Highest Cell State of Charge Module Number).
This parameter is for one of multiple packs in an HVESS. If there is only one pack in the system, the ...";
CM_ SG_ 2364744190 HighestCellStOfChargeModuleNum "Identifies the location of the module containing SPN 17156 (HVESP24 Highest Cell State of Charge).
This parameter is for one of multiple packs in an HVESS. If there is only one pack in the system, the HVESS parameters should be used. If there are ...";
BA_DEF_ SG_  "GenSigInactiveValue" INT 0 0;
BA_DEF_ SG_  "SigType" ENUM  "Default","Range","RangeSigned","ASCII","Discrete","Control","ReferencePGN","DTC","StringDelimiter","StringLength","StringLengthControl","MessageCounter","MessageChecksum";
BA_DEF_ SG_  "GenSigStartValue" INT 0 2147483647;
BA_DEF_ SG_  "GenSigSendType" ENUM  "Cyclic","OnWrite","OnWriteWithRepetition","OnChange","OnChangeWithRepetition","IfActive","IfActiveWithRepetition","NoSigSendType";
BA_DEF_ SG_  "GenSigILSupport" ENUM  "No","Yes";
BA_DEF_ SG_  "SPN" INT 0 524287;
BA_DEF_ BO_  "J1939CPgSendTimeout" INT -1 3600000;
BA_DEF_ BO_  "J1939CPgTOS" INT 0 7;
BA_DEF_ BO_  "J1939PgAppearanceOnBus" ENUM  "Default","CAN_Extended","CANFD_Extended";
BA_DEF_ BO_  "FsJ1939UseCrcAndCounter" STRING ;
BA_DEF_ BO_  "TpJ1939VarDlc" ENUM  "No","Yes";
BA_DEF_ BO_  "GenMsgNrOfRepetition" INT 0 1000000;
BA_DEF_ BO_  "GenMsgCycleTimeFast" INT 0 3600000;
BA_DEF_ BO_  "GenMsgFastOnStart" INT 0 100000;
BA_DEF_ BO_  "GenMsgStartDelayTime" INT 0 100000;
BA_DEF_ BO_  "GenMsgILSupport" ENUM  "No","Yes";
BA_DEF_ BO_  "GenMsgDelayTime" INT 0 1000;
BA_DEF_ BO_  "GenMsgRequestable" INT 0 1;
BA_DEF_ BO_  "GenMsgSendType" ENUM  "cyclic","NotUsed","NotUsed","NotUsed","NotUsed","NotUsed","NotUsed","IfActive","noMsgSendType";
BA_DEF_ BO_  "VFrameFormat" ENUM  "StandardCAN","ExtendedCAN","reserved","J1939PG","reserved","reserved","reserved","reserved","reserved","reserved","reserved","reserved","reserved","reserved","StandardCAN_FD","ExtendedCAN_FD";
BA_DEF_ BO_  "SingleFrame" INT 0 1;
BA_DEF_ BO_  "GenMsgCycleTime" INT 0 3600000;
BA_DEF_ SG_  "SystemSignalLongSymbol" STRING ;
BA_DEF_DEF_  "GenSigInactiveValue" 0;
BA_DEF_DEF_  "SigType" "Default";
BA_DEF_DEF_  "GenSigStartValue" 0;
BA_DEF_DEF_  "GenSigSendType" "NoSigSendType";
BA_DEF_DEF_  "GenSigILSupport" "Yes";
BA_DEF_DEF_  "SPN" 0;
BA_DEF_DEF_  "J1939CPgSendTimeout" -1;
BA_DEF_DEF_  "J1939CPgTOS" 2;
BA_DEF_DEF_  "J1939PgAppearanceOnBus" "Default";
BA_DEF_DEF_  "FsJ1939UseCrcAndCounter" "";
BA_DEF_DEF_  "TpJ1939VarDlc" "No";
BA_DEF_DEF_  "GenMsgNrOfRepetition" 0;
BA_DEF_DEF_  "GenMsgCycleTimeFast" 0;
BA_DEF_DEF_  "GenMsgFastOnStart" 0;
BA_DEF_DEF_  "GenMsgStartDelayTime" 0;
BA_DEF_DEF_  "GenMsgILSupport" "Yes";
BA_DEF_DEF_  "GenMsgDelayTime" 0;
BA_DEF_DEF_  "GenMsgRequestable" 1;
BA_DEF_DEF_  "GenMsgSendType" "noMsgSendType";
BA_DEF_DEF_  "VFrameFormat" "J1939PG";
BA_DEF_DEF_  "SingleFrame" 1;
BA_DEF_DEF_  "GenMsgCycleTime" 0;
BA_DEF_DEF_  "SystemSignalLongSymbol" "";
BA_ "GenMsgSendType" BO_ 2566544382 0;
BA_ "GenMsgCycleTime" BO_ 2566544382 1000;
BA_ "GenMsgSendType" BO_ 2566544126 0;
BA_ "GenMsgCycleTime" BO_ 2566544126 250;
BA_ "GenMsgSendType" BO_ 2566543870 0;
BA_ "GenMsgCycleTime" BO_ 2566543870 250;
BA_ "GenMsgSendType" BO_ 2566543614 0;
BA_ "GenMsgCycleTime" BO_ 2566543614 250;
BA_ "GenMsgSendType" BO_ 2566543358 0;
BA_ "GenMsgCycleTime" BO_ 2566543358 250;
BA_ "GenMsgSendType" BO_ 2566543102 0;
BA_ "GenMsgCycleTime" BO_ 2566543102 250;
BA_ "GenMsgSendType" BO_ 2566542846 0;
BA_ "GenMsgCycleTime" BO_ 2566542846 250;
BA_ "GenMsgSendType" BO_ 2566542590 0;
BA_ "GenMsgCycleTime" BO_ 2566542590 250;
BA_ "GenMsgSendType" BO_ 2566542334 0;
BA_ "GenMsgCycleTime" BO_ 2566542334 250;
BA_ "GenMsgSendType" BO_ 2566542078 0;
BA_ "GenMsgCycleTime" BO_ 2566542078 250;
BA_ "GenMsgSendType" BO_ 2566541822 0;
BA_ "GenMsgCycleTime" BO_ 2566541822 250;
BA_ "GenMsgSendType" BO_ 2566541566 0;
BA_ "GenMsgCycleTime" BO_ 2566541566 250;
BA_ "FsJ1939UseCrcAndCounter" BO_ 2566541310 "Aa";
BA_ "GenMsgSendType" BO_ 2566541310 0;
BA_ "GenMsgCycleTime" BO_ 2566541310 1000;
BA_ "GenMsgSendType" BO_ 2566541054 0;
BA_ "GenMsgCycleTime" BO_ 2566541054 1000;
BA_ "GenMsgSendType" BO_ 2566540542 0;
BA_ "GenMsgCycleTime" BO_ 2566540542 500;
BA_ "GenMsgSendType" BO_ 2566540286 0;
BA_ "GenMsgCycleTime" BO_ 2566540286 500;
BA_ "FsJ1939UseCrcAndCounter" BO_ 2364752638 "Cd";
BA_ "GenMsgSendType" BO_ 2364752638 0;
BA_ "GenMsgCycleTime" BO_ 2364752638 10;
BA_ "FsJ1939UseCrcAndCounter" BO_ 2297643518 "Cd";
BA_ "GenMsgSendType" BO_ 2297643518 0;
BA_ "GenMsgCycleTime" BO_ 2297643518 10;
BA_ "GenMsgSendType" BO_ 2364752126 0;
BA_ "GenMsgCycleTime" BO_ 2364752126 100;
BA_ "GenMsgSendType" BO_ 2364751870 0;
BA_ "GenMsgCycleTime" BO_ 2364751870 100;
BA_ "FsJ1939UseCrcAndCounter" BO_ 2364751614 "Aa";
BA_ "GenMsgSendType" BO_ 2364751614 0;
BA_ "GenMsgCycleTime" BO_ 2364751614 100;
BA_ "GenMsgSendType" BO_ 2364751358 0;
BA_ "GenMsgCycleTime" BO_ 2364751358 100;
BA_ "GenMsgSendType" BO_ 2364751102 0;
BA_ "GenMsgCycleTime" BO_ 2364751102 100;
BA_ "GenMsgSendType" BO_ 2364750846 0;
BA_ "GenMsgCycleTime" BO_ 2364750846 100;
BA_ "GenMsgSendType" BO_ 2364750590 0;
BA_ "GenMsgCycleTime" BO_ 2364750590 100;
BA_ "FsJ1939UseCrcAndCounter" BO_ 2364750334 "Aa";
BA_ "GenMsgDelayTime" BO_ 2364750334 20;
BA_ "GenMsgSendType" BO_ 2364750334 0;
BA_ "GenMsgCycleTime" BO_ 2364750334 100;
BA_ "GenMsgSendType" BO_ 2364750078 0;
BA_ "GenMsgCycleTime" BO_ 2364750078 100;
BA_ "GenMsgSendType" BO_ 2364749822 0;
BA_ "GenMsgCycleTime" BO_ 2364749822 20;
BA_ "GenMsgSendType" BO_ 2364749566 0;
BA_ "GenMsgCycleTime" BO_ 2364749566 100;
BA_ "GenMsgSendType" BO_ 2364749310 0;
BA_ "GenMsgCycleTime" BO_ 2364749310 20;
BA_ "GenMsgSendType" BO_ 2364749054 0;
BA_ "GenMsgCycleTime" BO_ 2364749054 20;
BA_ "GenMsgSendType" BO_ 2364748798 0;
BA_ "GenMsgCycleTime" BO_ 2364748798 20;
BA_ "GenMsgSendType" BO_ 2364748542 0;
BA_ "GenMsgCycleTime" BO_ 2364748542 100;
BA_ "GenMsgSendType" BO_ 2364748286 0;
BA_ "GenMsgCycleTime" BO_ 2364748286 100;
BA_ "GenMsgSendType" BO_ 2364748030 0;
BA_ "GenMsgCycleTime" BO_ 2364748030 100;
BA_ "FsJ1939UseCrcAndCounter" BO_ 2364747774 "Aa";
BA_ "GenMsgSendType" BO_ 2364747774 0;
BA_ "GenMsgCycleTime" BO_ 2364747774 100;
BA_ "GenMsgSendType" BO_ 2364747518 0;
BA_ "GenMsgCycleTime" BO_ 2364747518 100;
BA_ "GenMsgSendType" BO_ 2364747262 0;
BA_ "GenMsgCycleTime" BO_ 2364747262 100;
BA_ "GenMsgSendType" BO_ 2364747006 0;
BA_ "GenMsgCycleTime" BO_ 2364747006 100;
BA_ "GenMsgSendType" BO_ 2364746750 0;
BA_ "GenMsgCycleTime" BO_ 2364746750 100;
BA_ "FsJ1939UseCrcAndCounter" BO_ 2364746494 "Aa";
BA_ "GenMsgDelayTime" BO_ 2364746494 20;
BA_ "GenMsgSendType" BO_ 2364746494 0;
BA_ "GenMsgCycleTime" BO_ 2364746494 100;
BA_ "GenMsgSendType" BO_ 2364746238 0;
BA_ "GenMsgCycleTime" BO_ 2364746238 100;
BA_ "GenMsgSendType" BO_ 2364745982 0;
BA_ "GenMsgCycleTime" BO_ 2364745982 20;
BA_ "GenMsgSendType" BO_ 2364745726 0;
BA_ "GenMsgCycleTime" BO_ 2364745726 100;
BA_ "GenMsgSendType" BO_ 2364745470 0;
BA_ "GenMsgCycleTime" BO_ 2364745470 20;
BA_ "GenMsgSendType" BO_ 2364745214 0;
BA_ "GenMsgCycleTime" BO_ 2364745214 20;
BA_ "GenMsgSendType" BO_ 2364744958 0;
BA_ "GenMsgCycleTime" BO_ 2364744958 20;
BA_ "GenMsgSendType" BO_ 2364744702 0;
BA_ "GenMsgCycleTime" BO_ 2364744702 100;
BA_ "GenMsgSendType" BO_ 2364744446 0;
BA_ "GenMsgCycleTime" BO_ 2364744446 100;
BA_ "GenMsgSendType" BO_ 2364744190 0;
BA_ "GenMsgCycleTime" BO_ 2364744190 100;
BA_ "SPN" SG_ 2566544382 ErrorCode 21063;
BA_ "SigType" SG_ 2566544382 RESSConditioningFlag 5;
BA_ "SPN" SG_ 2566544382 RESSConditioningFlag 21062;
BA_ "SigType" SG_ 2566544382 CabinConditioningFlag 5;
BA_ "SPN" SG_ 2566544382 CabinConditioningFlag 21061;
BA_ "SigType" SG_ 2566544126 HeatingCircPumpCtrl 5;
BA_ "SPN" SG_ 2566544126 HeatingCircPumpCtrl 20864;
BA_ "SigType" SG_ 2566544126 HeatingCircDiffPressSwStatus 5;
BA_ "SPN" SG_ 2566544126 HeatingCircDiffPressSwStatus 20863;
BA_ "SigType" SG_ 2566544126 HeatingCircThermostatOpening 1;
BA_ "SPN" SG_ 2566544126 HeatingCircThermostatOpening 20862;
BA_ "SigType" SG_ 2566544126 DesHeatingCircThermostatOpening 1;
BA_ "SPN" SG_ 2566544126 DesHeatingCircThermostatOpening 20861;
BA_ "SigType" SG_ 2566544126 HeatingCircInletCoolantTemp 1;
BA_ "SPN" SG_ 2566544126 HeatingCircInletCoolantTemp 20860;
BA_ "SigType" SG_ 2566544126 HeatingCircOutCoolantTemp 1;
BA_ "SPN" SG_ 2566544126 HeatingCircOutCoolantTemp 20859;
BA_ "SigType" SG_ 2566543870 RecirculationLouverActPos 1;
BA_ "SPN" SG_ 2566543870 RecirculationLouverActPos 20858;
BA_ "SigType" SG_ 2566543870 RecirculationLouverActDesPos 1;
BA_ "SPN" SG_ 2566543870 RecirculationLouverActDesPos 20857;
BA_ "SigType" SG_ 2566543870 Act2Pos 1;
BA_ "SPN" SG_ 2566543870 Act2Pos 20856;
BA_ "SigType" SG_ 2566543870 Act2DesPos 1;
BA_ "SPN" SG_ 2566543870 Act2DesPos 20855;
BA_ "SigType" SG_ 2566543870 Act1Pos 1;
BA_ "SPN" SG_ 2566543870 Act1Pos 20854;
BA_ "SigType" SG_ 2566543870 Act1DesPos 1;
BA_ "SPN" SG_ 2566543870 Act1DesPos 20853;
BA_ "SigType" SG_ 2566543614 BypassAct1Pos 1;
BA_ "SPN" SG_ 2566543614 BypassAct1Pos 20852;
BA_ "SigType" SG_ 2566543614 BypassAct1DesPos 1;
BA_ "SPN" SG_ 2566543614 BypassAct1DesPos 20851;
BA_ "SigType" SG_ 2566543614 TempAfterExhHeatExchanger 1;
BA_ "SPN" SG_ 2566543614 TempAfterExhHeatExchanger 20850;
BA_ "SigType" SG_ 2566543358 SecondOutTemp 1;
BA_ "SPN" SG_ 2566543358 SecondOutTemp 20849;
BA_ "SigType" SG_ 2566543358 SecondInTemp 1;
BA_ "SPN" SG_ 2566543358 SecondInTemp 20848;
BA_ "SigType" SG_ 2566543358 PrimaryOutTemp 1;
BA_ "SPN" SG_ 2566543358 PrimaryOutTemp 20847;
BA_ "SigType" SG_ 2566543358 PrimaryInTemp 1;
BA_ "SPN" SG_ 2566543358 PrimaryInTemp 20846;
BA_ "SigType" SG_ 2566543102 SecondOutTemp 1;
BA_ "SPN" SG_ 2566543102 SecondOutTemp 20845;
BA_ "SigType" SG_ 2566543102 SecondInTemp 1;
BA_ "SPN" SG_ 2566543102 SecondInTemp 20844;
BA_ "SigType" SG_ 2566543102 PrimaryOutTemp 1;
BA_ "SPN" SG_ 2566543102 PrimaryOutTemp 20843;
BA_ "SigType" SG_ 2566543102 PrimaryInTemp 1;
BA_ "SPN" SG_ 2566543102 PrimaryInTemp 20842;
BA_ "SigType" SG_ 2566542846 SecondOutTemp 1;
BA_ "SPN" SG_ 2566542846 SecondOutTemp 20841;
BA_ "SigType" SG_ 2566542846 SecondInTemp 1;
BA_ "SPN" SG_ 2566542846 SecondInTemp 20840;
BA_ "SigType" SG_ 2566542846 PrimaryOutTemp 1;
BA_ "SPN" SG_ 2566542846 PrimaryOutTemp 20839;
BA_ "SigType" SG_ 2566542846 PrimaryInTemp 1;
BA_ "SPN" SG_ 2566542846 PrimaryInTemp 20838;
BA_ "SigType" SG_ 2566542590 SecondOutTemp 1;
BA_ "SPN" SG_ 2566542590 SecondOutTemp 20837;
BA_ "SigType" SG_ 2566542590 SecondInTemp 1;
BA_ "SPN" SG_ 2566542590 SecondInTemp 20836;
BA_ "SigType" SG_ 2566542590 PrimaryOutTemp 1;
BA_ "SPN" SG_ 2566542590 PrimaryOutTemp 20835;
BA_ "SigType" SG_ 2566542590 PrimaryInTemp 1;
BA_ "SPN" SG_ 2566542590 PrimaryInTemp 20834;
BA_ "SigType" SG_ 2566542334 FanSt 5;
BA_ "SPN" SG_ 2566542334 FanSt 21156;
BA_ "SigType" SG_ 2566542334 FanReqPercentSpd 1;
BA_ "SPN" SG_ 2566542334 FanReqPercentSpd 20833;
BA_ "SigType" SG_ 2566542334 OutAirTemp 1;
BA_ "SPN" SG_ 2566542334 OutAirTemp 20832;
BA_ "SigType" SG_ 2566542334 InAirTemp 1;
BA_ "SPN" SG_ 2566542334 InAirTemp 20831;
BA_ "SigType" SG_ 2566542078 Fan8Status 5;
BA_ "SPN" SG_ 2566542078 Fan8Status 20830;
BA_ "SigType" SG_ 2566542078 Fan7Status 5;
BA_ "SPN" SG_ 2566542078 Fan7Status 20829;
BA_ "SigType" SG_ 2566542078 Fan6Status 5;
BA_ "SPN" SG_ 2566542078 Fan6Status 20828;
BA_ "SigType" SG_ 2566542078 Fan5Status 5;
BA_ "SPN" SG_ 2566542078 Fan5Status 20827;
BA_ "SigType" SG_ 2566542078 Fan4Status 5;
BA_ "SPN" SG_ 2566542078 Fan4Status 20826;
BA_ "SigType" SG_ 2566542078 Fan3Status 5;
BA_ "SPN" SG_ 2566542078 Fan3Status 20825;
BA_ "SigType" SG_ 2566542078 Fan2Status 5;
BA_ "SPN" SG_ 2566542078 Fan2Status 20824;
BA_ "SigType" SG_ 2566542078 Fan1Status 5;
BA_ "SPN" SG_ 2566542078 Fan1Status 20823;
BA_ "SigType" SG_ 2566542078 DesEngRadiator2CtrlTemp 1;
BA_ "SPN" SG_ 2566542078 DesEngRadiator2CtrlTemp 20822;
BA_ "SigType" SG_ 2566542078 CtrlTemp 1;
BA_ "SPN" SG_ 2566542078 CtrlTemp 20821;
BA_ "SigType" SG_ 2566541822 TempCtrlSelectionSt 5;
BA_ "SPN" SG_ 2566541822 TempCtrlSelectionSt 21160;
BA_ "SigType" SG_ 2566541822 Fan8Status 5;
BA_ "SPN" SG_ 2566541822 Fan8Status 20820;
BA_ "SigType" SG_ 2566541822 Fan7Status 5;
BA_ "SPN" SG_ 2566541822 Fan7Status 20819;
BA_ "SigType" SG_ 2566541822 Fan6Status 5;
BA_ "SPN" SG_ 2566541822 Fan6Status 20818;
BA_ "SigType" SG_ 2566541822 Fan5Status 5;
BA_ "SPN" SG_ 2566541822 Fan5Status 20817;
BA_ "SigType" SG_ 2566541822 Fan4Status 5;
BA_ "SPN" SG_ 2566541822 Fan4Status 20816;
BA_ "SigType" SG_ 2566541822 Fan3Status 5;
BA_ "SPN" SG_ 2566541822 Fan3Status 20815;
BA_ "SigType" SG_ 2566541822 Fan2Status 5;
BA_ "SPN" SG_ 2566541822 Fan2Status 20814;
BA_ "SigType" SG_ 2566541822 Fan1Status 5;
BA_ "SPN" SG_ 2566541822 Fan1Status 20813;
BA_ "SigType" SG_ 2566541822 DesEngRadiator1CtrlTemp 1;
BA_ "SPN" SG_ 2566541822 DesEngRadiator1CtrlTemp 20812;
BA_ "SigType" SG_ 2566541822 CtrlTemp 1;
BA_ "SPN" SG_ 2566541822 CtrlTemp 20811;
BA_ "SigType" SG_ 2566541566 SepCPCtrl 5;
BA_ "SPN" SG_ 2566541566 SepCPCtrl 20810;
BA_ "SigType" SG_ 2566541566 SepCoolantDiffPressSwStatus 5;
BA_ "SPN" SG_ 2566541566 SepCoolantDiffPressSwStatus 20809;
BA_ "SigType" SG_ 2566541566 DesAftercoolerCoolantInTemp 1;
BA_ "SPN" SG_ 2566541566 DesAftercoolerCoolantInTemp 20808;
BA_ "SigType" SG_ 2566541566 SepCoolantTemp 1;
BA_ "SPN" SG_ 2566541566 SepCoolantTemp 20807;
BA_ "SigType" SG_ 2566541310 CRC 12;
BA_ "SPN" SG_ 2566541310 CRC 14456;
BA_ "SigType" SG_ 2566541310 Counter 11;
BA_ "SPN" SG_ 2566541310 Counter 14455;
BA_ "SigType" SG_ 2566541310 EmbeddedIntegritySupport 5;
BA_ "SPN" SG_ 2566541310 EmbeddedIntegritySupport 22264;
BA_ "SPN" SG_ 2566541310 OpStatus 20870;
BA_ "SPN" SG_ 2566541054 CpntDiagAndMtCap 22678;
BA_ "SPN" SG_ 2566541054 Ctrl4CommunicationSt 21250;
BA_ "SPN" SG_ 2566541054 Ctrl3CommunicationSt 21249;
BA_ "SPN" SG_ 2566541054 Ctrl2CommunicationSt 21248;
BA_ "SPN" SG_ 2566541054 Ctrl1CommunicationSt 21247;
BA_ "SigType" SG_ 2566541054 AutomatedModeSupport 5;
BA_ "SPN" SG_ 2566541054 AutomatedModeSupport 20874;
BA_ "SigType" SG_ 2566541054 AutomatedModeWithOpOvrdSupport 5;
BA_ "SPN" SG_ 2566541054 AutomatedModeWithOpOvrdSupport 20873;
BA_ "SigType" SG_ 2566541054 ManualModeSupport 5;
BA_ "SPN" SG_ 2566541054 ManualModeSupport 20872;
BA_ "SPN" SG_ 2566541054 OpStatusAcknowledgement 20871;
BA_ "SigType" SG_ 2566540798 TripDriveEnergyEconomy 1;
BA_ "SPN" SG_ 2566540798 TripDriveEnergyEconomy 20875;
BA_ "SigType" SG_ 2566540798 TotalTripEnergyConsumed 1;
BA_ "SPN" SG_ 2566540798 TotalTripEnergyConsumed 20876;
BA_ "SigType" SG_ 2566540542 DEFDoser3Press 1;
BA_ "SPN" SG_ 2566540542 DEFDoser3Press 20908;
BA_ "SigType" SG_ 2566540542 DEFDoser2Press 1;
BA_ "SPN" SG_ 2566540542 DEFDoser2Press 20907;
BA_ "SigType" SG_ 2566540286 DEFDoser3Press 1;
BA_ "SPN" SG_ 2566540286 DEFDoser3Press 20911;
BA_ "SigType" SG_ 2566540286 DEFDoser2Press 1;
BA_ "SPN" SG_ 2566540286 DEFDoser2Press 20910;
BA_ "SigType" SG_ 2364752638 MessageChecksum 12;
BA_ "SPN" SG_ 2364752638 MessageChecksum 21105;
BA_ "SigType" SG_ 2364752638 MessageCounter 11;
BA_ "SPN" SG_ 2364752638 MessageCounter 21104;
BA_ "SigType" SG_ 2364752638 SteerWheelTrq 1;
BA_ "SPN" SG_ 2364752638 SteerWheelTrq 21103;
BA_ "SigType" SG_ 2364752638 SteerWheelPos 1;
BA_ "SPN" SG_ 2364752638 SteerWheelPos 21102;
BA_ "SigType" SG_ 2364752638 AbsSteerPosQualityFactor 5;
BA_ "SPN" SG_ 2364752638 AbsSteerPosQualityFactor 21101;
BA_ "SigType" SG_ 2364752638 IgntPwr 5;
BA_ "SPN" SG_ 2364752638 IgntPwr 21100;
BA_ "SPN" SG_ 2364752638 ReqMode 21099;
BA_ "SPN" SG_ 2364752638 ErrorType 21098;
BA_ "SPN" SG_ 2364752638 St 21097;
BA_ "SPN" SG_ 2364752638 ActualMode 21096;
BA_ "SigType" SG_ 2297643518 XSRMessageChecksum 12;
BA_ "SPN" SG_ 2297643518 XSRMessageChecksum 21095;
BA_ "SigType" SG_ 2297643518 XSRMessageCounter 11;
BA_ "SPN" SG_ 2297643518 XSRMessageCounter 21094;
BA_ "SPN" SG_ 2297643518 Priority 21093;
BA_ "SigType" SG_ 2297643518 WheelTrqReq 1;
BA_ "SPN" SG_ 2297643518 WheelTrqReq 21092;
BA_ "SigType" SG_ 2297643518 WheelPosReq 1;
BA_ "SPN" SG_ 2297643518 WheelPosReq 21091;
BA_ "SPN" SG_ 2297643518 OperatingMode 21090;
BA_ "SigType" SG_ 2364752126 ActualChargeRate 1;
BA_ "SPN" SG_ 2364752126 ActualChargeRate 17524;
BA_ "SigType" SG_ 2364752126 LvlNegToChassisGroundV 1;
BA_ "SPN" SG_ 2364752126 LvlNegToChassisGroundV 17523;
BA_ "SigType" SG_ 2364752126 BusVNegToChassisGroundV 1;
BA_ "SPN" SG_ 2364752126 BusVNegToChassisGroundV 17522;
BA_ "SigType" SG_ 2364751870 HVBusPassiveIsolTestResults 1;
BA_ "SPN" SG_ 2364751870 HVBusPassiveIsolTestResults 17521;
BA_ "SigType" SG_ 2364751870 HVBusActiveIsolTestResults 1;
BA_ "SPN" SG_ 2364751870 HVBusActiveIsolTestResults 17520;
BA_ "SigType" SG_ 2364751870 LowestCellStOfChargeCellNum 1;
BA_ "SPN" SG_ 2364751870 LowestCellStOfChargeCellNum 17519;
BA_ "SigType" SG_ 2364751870 LowestCellStOfChargeModuleNum 1;
BA_ "SPN" SG_ 2364751870 LowestCellStOfChargeModuleNum 17518;
BA_ "SigType" SG_ 2364751870 HighestCellStOfChargeCellNum 1;
BA_ "SPN" SG_ 2364751870 HighestCellStOfChargeCellNum 17517;
BA_ "SigType" SG_ 2364751870 HighestCellStOfChargeModuleNum 1;
BA_ "SPN" SG_ 2364751870 HighestCellStOfChargeModuleNum 17516;
BA_ "SigType" SG_ 2364751614 Data9CRC 12;
BA_ "SPN" SG_ 2364751614 Data9CRC 23051;
BA_ "SigType" SG_ 2364751614 Data9Counter 11;
BA_ "SPN" SG_ 2364751614 Data9Counter 23050;
BA_ "SigType" SG_ 2364751614 Data9EmbeddedIntegritySupport 5;
BA_ "SPN" SG_ 2364751614 Data9EmbeddedIntegritySupport 23049;
BA_ "SigType" SG_ 2364751614 HVESS26ThermalEventDetected 4;
BA_ "SPN" SG_ 2364751614 HVESS26ThermalEventDetected 21313;
BA_ "SigType" SG_ 2364751614 LowestCellTempCellNum 1;
BA_ "SPN" SG_ 2364751614 LowestCellTempCellNum 17515;
BA_ "SigType" SG_ 2364751614 LowestCellTempModuleNum 1;
BA_ "SPN" SG_ 2364751614 LowestCellTempModuleNum 17514;
BA_ "SigType" SG_ 2364751614 HighestCellTempCellNum 1;
BA_ "SPN" SG_ 2364751614 HighestCellTempCellNum 17513;
BA_ "SigType" SG_ 2364751614 HighestCellTempModuleNum 1;
BA_ "SPN" SG_ 2364751614 HighestCellTempModuleNum 17512;
BA_ "SigType" SG_ 2364751358 AvgCellV 1;
BA_ "SPN" SG_ 2364751358 AvgCellV 17511;
BA_ "SigType" SG_ 2364751358 LowestCellVCellNum 1;
BA_ "SPN" SG_ 2364751358 LowestCellVCellNum 17510;
BA_ "SigType" SG_ 2364751358 LowestCellVModuleNum 1;
BA_ "SPN" SG_ 2364751358 LowestCellVModuleNum 17509;
BA_ "SigType" SG_ 2364751358 HighestCellVCellNum 1;
BA_ "SPN" SG_ 2364751358 HighestCellVCellNum 17508;
BA_ "SigType" SG_ 2364751358 HighestCellVModuleNum 1;
BA_ "SPN" SG_ 2364751358 HighestCellVModuleNum 17507;
BA_ "SigType" SG_ 2364751102 TMSCoolantLvl 4;
BA_ "SPN" SG_ 2364751102 TMSCoolantLvl 17506;
BA_ "SPN" SG_ 2364751102 TMSMode 17505;
BA_ "SigType" SG_ 2364751102 TMSHVILStatus 4;
BA_ "SPN" SG_ 2364751102 TMSHVILStatus 17504;
BA_ "SigType" SG_ 2364751102 TMSHtrStatus 5;
BA_ "SPN" SG_ 2364751102 TMSHtrStatus 17503;
BA_ "SigType" SG_ 2364751102 TMSRelHumidty 1;
BA_ "SPN" SG_ 2364751102 TMSRelHumidty 17502;
BA_ "SigType" SG_ 2364751102 TMSCompressorSpd 1;
BA_ "SPN" SG_ 2364751102 TMSCompressorSpd 17501;
BA_ "SigType" SG_ 2364751102 TMSHVInputPwr 1;
BA_ "SPN" SG_ 2364751102 TMSHVInputPwr 17500;
BA_ "SigType" SG_ 2364751102 TMSSLIInputPwr 1;
BA_ "SPN" SG_ 2364751102 TMSSLIInputPwr 17499;
BA_ "SigType" SG_ 2364750846 Module32OperationalStatus 5;
BA_ "SPN" SG_ 2364750846 Module32OperationalStatus 17498;
BA_ "SigType" SG_ 2364750846 Module31OperationalStatus 5;
BA_ "SPN" SG_ 2364750846 Module31OperationalStatus 17497;
BA_ "SigType" SG_ 2364750846 Module30OperationalStatus 5;
BA_ "SPN" SG_ 2364750846 Module30OperationalStatus 17496;
BA_ "SigType" SG_ 2364750846 Module29OperationalStatus 5;
BA_ "SPN" SG_ 2364750846 Module29OperationalStatus 17495;
BA_ "SigType" SG_ 2364750846 Module28OperationalStatus 5;
BA_ "SPN" SG_ 2364750846 Module28OperationalStatus 17494;
BA_ "SigType" SG_ 2364750846 Module27OperationalStatus 5;
BA_ "SPN" SG_ 2364750846 Module27OperationalStatus 17493;
BA_ "SigType" SG_ 2364750846 Module26OperationalStatus 5;
BA_ "SPN" SG_ 2364750846 Module26OperationalStatus 17492;
BA_ "SigType" SG_ 2364750846 Module25OperationalStatus 5;
BA_ "SPN" SG_ 2364750846 Module25OperationalStatus 17491;
BA_ "SigType" SG_ 2364750846 Module24OperationalStatus 5;
BA_ "SPN" SG_ 2364750846 Module24OperationalStatus 17490;
BA_ "SigType" SG_ 2364750846 Module23OperationalStatus 5;
BA_ "SPN" SG_ 2364750846 Module23OperationalStatus 17489;
BA_ "SigType" SG_ 2364750846 Module22OperationalStatus 5;
BA_ "SPN" SG_ 2364750846 Module22OperationalStatus 17488;
BA_ "SigType" SG_ 2364750846 Module21OperationalStatus 5;
BA_ "SPN" SG_ 2364750846 Module21OperationalStatus 17487;
BA_ "SigType" SG_ 2364750846 Module20OperationalStatus 5;
BA_ "SPN" SG_ 2364750846 Module20OperationalStatus 17486;
BA_ "SigType" SG_ 2364750846 Module19OperationalStatus 5;
BA_ "SPN" SG_ 2364750846 Module19OperationalStatus 17485;
BA_ "SigType" SG_ 2364750846 Module18OperationalStatus 5;
BA_ "SPN" SG_ 2364750846 Module18OperationalStatus 17484;
BA_ "SigType" SG_ 2364750846 Module17OperationalStatus 5;
BA_ "SPN" SG_ 2364750846 Module17OperationalStatus 17483;
BA_ "SigType" SG_ 2364750846 Module16OperationalStatus 5;
BA_ "SPN" SG_ 2364750846 Module16OperationalStatus 17482;
BA_ "SigType" SG_ 2364750846 Module15OperationalStatus 5;
BA_ "SPN" SG_ 2364750846 Module15OperationalStatus 17481;
BA_ "SigType" SG_ 2364750846 Module14OperationalStatus 5;
BA_ "SPN" SG_ 2364750846 Module14OperationalStatus 17480;
BA_ "SigType" SG_ 2364750846 Module13OperationalStatus 5;
BA_ "SPN" SG_ 2364750846 Module13OperationalStatus 17479;
BA_ "SigType" SG_ 2364750846 Module12OperationalStatus 5;
BA_ "SPN" SG_ 2364750846 Module12OperationalStatus 17478;
BA_ "SigType" SG_ 2364750846 Module11OperationalStatus 5;
BA_ "SPN" SG_ 2364750846 Module11OperationalStatus 17477;
BA_ "SigType" SG_ 2364750846 Module10OperationalStatus 5;
BA_ "SPN" SG_ 2364750846 Module10OperationalStatus 17476;
BA_ "SigType" SG_ 2364750846 Module9OperationalStatus 5;
BA_ "SPN" SG_ 2364750846 Module9OperationalStatus 17475;
BA_ "SigType" SG_ 2364750846 Module8OperationalStatus 5;
BA_ "SPN" SG_ 2364750846 Module8OperationalStatus 17474;
BA_ "SigType" SG_ 2364750846 Module7OperationalStatus 5;
BA_ "SPN" SG_ 2364750846 Module7OperationalStatus 17473;
BA_ "SigType" SG_ 2364750846 Module6OperationalStatus 5;
BA_ "SPN" SG_ 2364750846 Module6OperationalStatus 17472;
BA_ "SigType" SG_ 2364750846 Module5OperationalStatus 5;
BA_ "SPN" SG_ 2364750846 Module5OperationalStatus 17471;
BA_ "SigType" SG_ 2364750846 Module4OperationalStatus 5;
BA_ "SPN" SG_ 2364750846 Module4OperationalStatus 17470;
BA_ "SigType" SG_ 2364750846 Module3OperationalStatus 5;
BA_ "SPN" SG_ 2364750846 Module3OperationalStatus 17469;
BA_ "SigType" SG_ 2364750846 Module2OperationalStatus 5;
BA_ "SPN" SG_ 2364750846 Module2OperationalStatus 17468;
BA_ "SigType" SG_ 2364750846 Module1OperationalStatus 5;
BA_ "SPN" SG_ 2364750846 Module1OperationalStatus 17467;
BA_ "SigType" SG_ 2364750590 MaxChargeVLmt 1;
BA_ "SPN" SG_ 2364750590 MaxChargeVLmt 17466;
BA_ "SPN" SG_ 2364750590 ChargeEnergyCapacity 17465;
BA_ "SPN" SG_ 2364750590 DisEnergyCapacity 17464;
BA_ "SigType" SG_ 2364750334 Status1CRC 12;
BA_ "SPN" SG_ 2364750334 Status1CRC 17463;
BA_ "SigType" SG_ 2364750334 Status1Counter 11;
BA_ "SPN" SG_ 2364750334 Status1Counter 17462;
BA_ "SPN" SG_ 2364750334 OperationalStatus 17461;
BA_ "SPN" SG_ 2364750334 HVBusConnectionStatus 17460;
BA_ "SigType" SG_ 2364750334 InternalChargerStatus 5;
BA_ "SPN" SG_ 2364750334 InternalChargerStatus 17459;
BA_ "SigType" SG_ 2364750334 CellBalancingActive 4;
BA_ "SPN" SG_ 2364750334 CellBalancingActive 17458;
BA_ "SigType" SG_ 2364750334 CellBalanceStatus 4;
BA_ "SPN" SG_ 2364750334 CellBalanceStatus 17457;
BA_ "SPN" SG_ 2364750334 StOfChargeStatus 17456;
BA_ "SigType" SG_ 2364750334 InertiaSwStatus 4;
BA_ "SPN" SG_ 2364750334 InertiaSwStatus 17455;
BA_ "SigType" SG_ 2364750334 HVILStatus 4;
BA_ "SPN" SG_ 2364750334 HVILStatus 17454;
BA_ "SPN" SG_ 2364750334 HVBusPassiveIsolTestStatus 17453;
BA_ "SPN" SG_ 2364750334 HVBusActiveIsolTestStatus 17452;
BA_ "SigType" SG_ 2364750334 CenterOfPackContactorSt 4;
BA_ "SPN" SG_ 2364750334 CenterOfPackContactorSt 17451;
BA_ "SigType" SG_ 2364750334 HVBusPreChargeRelaySt 4;
BA_ "SPN" SG_ 2364750334 HVBusPreChargeRelaySt 17450;
BA_ "SPN" SG_ 2364750334 HVBusDisconnectForewarning 17449;
BA_ "SigType" SG_ 2364750334 HVBusContactorSt17448 4;
BA_ "SPN" SG_ 2364750334 HVBusContactorSt17448 17448;
BA_ "SigType" SG_ 2364750334 HVBusContactorSt 4;
BA_ "SPN" SG_ 2364750334 HVBusContactorSt 17447;
BA_ "SigType" SG_ 2364750078 Temp 1;
BA_ "SPN" SG_ 2364750078 Temp 17446;
BA_ "SigType" SG_ 2364750078 ETemp 1;
BA_ "SPN" SG_ 2364750078 ETemp 17445;
BA_ "SigType" SG_ 2364750078 OutCoolantTemp 1;
BA_ "SPN" SG_ 2364750078 OutCoolantTemp 17444;
BA_ "SigType" SG_ 2364750078 InCoolantTemp 1;
BA_ "SPN" SG_ 2364750078 InCoolantTemp 17443;
BA_ "SigType" SG_ 2364750078 IgntV 1;
BA_ "SPN" SG_ 2364750078 IgntV 17442;
BA_ "SigType" SG_ 2364750078 BusV 1;
BA_ "SPN" SG_ 2364750078 BusV 17441;
BA_ "SigType" SG_ 2364749822 HighestCellStOfCharge 1;
BA_ "SPN" SG_ 2364749822 HighestCellStOfCharge 17440;
BA_ "SigType" SG_ 2364749822 LowestCellStOfCharge 1;
BA_ "SPN" SG_ 2364749822 LowestCellStOfCharge 17439;
BA_ "SigType" SG_ 2364749822 ChargeCurLmt 1;
BA_ "GenSigStartValue" SG_ 2364749822 ChargeCurLmt 32000;
BA_ "SPN" SG_ 2364749822 ChargeCurLmt 17438;
BA_ "SigType" SG_ 2364749822 DisCurLmt 1;
BA_ "SPN" SG_ 2364749822 DisCurLmt 17437;
BA_ "SigType" SG_ 2364749566 CellBalancingCount 1;
BA_ "SPN" SG_ 2364749566 CellBalancingCount 17436;
BA_ "SigType" SG_ 2364749566 ChargeCapacity 1;
BA_ "SPN" SG_ 2364749566 ChargeCapacity 17435;
BA_ "SigType" SG_ 2364749566 DisCapacity 1;
BA_ "SPN" SG_ 2364749566 DisCapacity 17434;
BA_ "SigType" SG_ 2364749310 CellTempDiffStatus 4;
BA_ "SPN" SG_ 2364749310 CellTempDiffStatus 17433;
BA_ "SigType" SG_ 2364749310 AvgCellTemp 1;
BA_ "SPN" SG_ 2364749310 AvgCellTemp 17432;
BA_ "SigType" SG_ 2364749310 LowestCellTemp 1;
BA_ "SPN" SG_ 2364749310 LowestCellTemp 17431;
BA_ "SigType" SG_ 2364749310 HighestCellTemp 1;
BA_ "SPN" SG_ 2364749310 HighestCellTemp 17430;
BA_ "SPN" SG_ 2364749054 CellVDiffStatus 17429;
BA_ "SigType" SG_ 2364749054 LowestCellV 1;
BA_ "SPN" SG_ 2364749054 LowestCellV 17428;
BA_ "SigType" SG_ 2364749054 HighestCellV 1;
BA_ "SPN" SG_ 2364749054 HighestCellV 17427;
BA_ "SigType" SG_ 2364749054 FastUpdateStOfCharge 1;
BA_ "SPN" SG_ 2364749054 FastUpdateStOfCharge 17426;
BA_ "SigType" SG_ 2364748798 Cur 1;
BA_ "SPN" SG_ 2364748798 Cur 17425;
BA_ "SigType" SG_ 2364748798 Lvl 1;
BA_ "SPN" SG_ 2364748798 Lvl 17424;
BA_ "SigType" SG_ 2364748798 AvailableChargePwr 1;
BA_ "SPN" SG_ 2364748798 AvailableChargePwr 17423;
BA_ "SigType" SG_ 2364748798 AvailableDisPwr 1;
BA_ "SPN" SG_ 2364748798 AvailableDisPwr 17422;
BA_ "SigType" SG_ 2364748542 ChargePLDueToAnUndefinedCause 4;
BA_ "SPN" SG_ 2364748542 ChargePLDueToAnUndefinedCause 17421;
BA_ "SigType" SG_ 2364748542 ChargePLDueToBatCur 4;
BA_ "SPN" SG_ 2364748542 ChargePLDueToBatCur 17420;
BA_ "SigType" SG_ 2364748542 ChargePLDueToBatOrCellV 4;
BA_ "SPN" SG_ 2364748542 ChargePLDueToBatOrCellV 17419;
BA_ "SigType" SG_ 2364748542 ChargePLDueToBatDiagCondition 4;
BA_ "SPN" SG_ 2364748542 ChargePLDueToBatDiagCondition 17418;
BA_ "SigType" SG_ 2364748542 ChargePLDueToBatTemp 4;
BA_ "SPN" SG_ 2364748542 ChargePLDueToBatTemp 17417;
BA_ "SigType" SG_ 2364748542 ChargePLDueToStOfCharge 4;
BA_ "SPN" SG_ 2364748542 ChargePLDueToStOfCharge 17416;
BA_ "SigType" SG_ 2364748542 DisPLDueToAnUndefinedCause 4;
BA_ "SPN" SG_ 2364748542 DisPLDueToAnUndefinedCause 17415;
BA_ "SigType" SG_ 2364748542 DisPLDueToBatCur 4;
BA_ "SPN" SG_ 2364748542 DisPLDueToBatCur 17414;
BA_ "SigType" SG_ 2364748542 DisPLDueToBatOrCellV 4;
BA_ "SPN" SG_ 2364748542 DisPLDueToBatOrCellV 17413;
BA_ "SigType" SG_ 2364748542 DisPLDueToBatDiagCondition 4;
BA_ "SPN" SG_ 2364748542 DisPLDueToBatDiagCondition 17412;
BA_ "SigType" SG_ 2364748542 DisPLDueToBatTemp 4;
BA_ "SPN" SG_ 2364748542 DisPLDueToBatTemp 17411;
BA_ "SigType" SG_ 2364748542 DisPLDueToStOfCharge 4;
BA_ "SPN" SG_ 2364748542 DisPLDueToStOfCharge 17410;
BA_ "SigType" SG_ 2364748286 ActualChargeRate 1;
BA_ "SPN" SG_ 2364748286 ActualChargeRate 17382;
BA_ "SigType" SG_ 2364748286 LvlNegToChassisGroundV 1;
BA_ "SPN" SG_ 2364748286 LvlNegToChassisGroundV 17381;
BA_ "SigType" SG_ 2364748286 BusVNegToChassisGroundV 1;
BA_ "SPN" SG_ 2364748286 BusVNegToChassisGroundV 17380;
BA_ "SigType" SG_ 2364748030 HVBusPassiveIsolTestResults 1;
BA_ "SPN" SG_ 2364748030 HVBusPassiveIsolTestResults 17379;
BA_ "SigType" SG_ 2364748030 HVBusActiveIsolTestResults 1;
BA_ "SPN" SG_ 2364748030 HVBusActiveIsolTestResults 17378;
BA_ "SigType" SG_ 2364748030 LowestCellStOfChargeCellNum 1;
BA_ "SPN" SG_ 2364748030 LowestCellStOfChargeCellNum 17377;
BA_ "SigType" SG_ 2364748030 LowestCellStOfChargeModuleNum 1;
BA_ "SPN" SG_ 2364748030 LowestCellStOfChargeModuleNum 17376;
BA_ "SigType" SG_ 2364748030 HighestCellStOfChargeCellNum 1;
BA_ "SPN" SG_ 2364748030 HighestCellStOfChargeCellNum 17375;
BA_ "SigType" SG_ 2364748030 HighestCellStOfChargeModuleNum 1;
BA_ "SPN" SG_ 2364748030 HighestCellStOfChargeModuleNum 17374;
BA_ "SigType" SG_ 2364747774 Data9CRC 12;
BA_ "SPN" SG_ 2364747774 Data9CRC 23048;
BA_ "SigType" SG_ 2364747774 Data9Counter 11;
BA_ "SPN" SG_ 2364747774 Data9Counter 23047;
BA_ "SigType" SG_ 2364747774 Data9EmbeddedIntegritySupport 5;
BA_ "SPN" SG_ 2364747774 Data9EmbeddedIntegritySupport 23046;
BA_ "SigType" SG_ 2364747774 HVESS25ThermalEventDetected 4;
BA_ "SPN" SG_ 2364747774 HVESS25ThermalEventDetected 21312;
BA_ "SigType" SG_ 2364747774 LowestCellTempCellNum 1;
BA_ "SPN" SG_ 2364747774 LowestCellTempCellNum 17373;
BA_ "SigType" SG_ 2364747774 LowestCellTempModuleNum 1;
BA_ "SPN" SG_ 2364747774 LowestCellTempModuleNum 17372;
BA_ "SigType" SG_ 2364747774 HighestCellTempCellNum 1;
BA_ "SPN" SG_ 2364747774 HighestCellTempCellNum 17371;
BA_ "SigType" SG_ 2364747774 HighestCellTempModuleNum 1;
BA_ "SPN" SG_ 2364747774 HighestCellTempModuleNum 17370;
BA_ "SigType" SG_ 2364747518 AvgCellV 1;
BA_ "SPN" SG_ 2364747518 AvgCellV 17369;
BA_ "SigType" SG_ 2364747518 LowestCellVCellNum 1;
BA_ "SPN" SG_ 2364747518 LowestCellVCellNum 17368;
BA_ "SigType" SG_ 2364747518 LowestCellVModuleNum 1;
BA_ "SPN" SG_ 2364747518 LowestCellVModuleNum 17367;
BA_ "SigType" SG_ 2364747518 HighestCellVCellNum 1;
BA_ "SPN" SG_ 2364747518 HighestCellVCellNum 17366;
BA_ "SigType" SG_ 2364747518 HighestCellVModuleNum 1;
BA_ "SPN" SG_ 2364747518 HighestCellVModuleNum 17365;
BA_ "SigType" SG_ 2364747262 TMSCoolantLvl 4;
BA_ "SPN" SG_ 2364747262 TMSCoolantLvl 17364;
BA_ "SPN" SG_ 2364747262 TMSMode 17363;
BA_ "SigType" SG_ 2364747262 TMSHVILStatus 4;
BA_ "SPN" SG_ 2364747262 TMSHVILStatus 17362;
BA_ "SigType" SG_ 2364747262 TMSHtrStatus 5;
BA_ "SPN" SG_ 2364747262 TMSHtrStatus 17361;
BA_ "SigType" SG_ 2364747262 TMSRelHumidty 1;
BA_ "SPN" SG_ 2364747262 TMSRelHumidty 17360;
BA_ "SigType" SG_ 2364747262 TMSCompressorSpd 1;
BA_ "SPN" SG_ 2364747262 TMSCompressorSpd 17359;
BA_ "SigType" SG_ 2364747262 TMSHVInputPwr 1;
BA_ "SPN" SG_ 2364747262 TMSHVInputPwr 17358;
BA_ "SigType" SG_ 2364747262 TMSSLIInputPwr 1;
BA_ "SPN" SG_ 2364747262 TMSSLIInputPwr 17357;
BA_ "SigType" SG_ 2364747006 Module32OperationalStatus 5;
BA_ "SPN" SG_ 2364747006 Module32OperationalStatus 17356;
BA_ "SigType" SG_ 2364747006 Module31OperationalStatus 5;
BA_ "SPN" SG_ 2364747006 Module31OperationalStatus 17355;
BA_ "SigType" SG_ 2364747006 Module30OperationalStatus 5;
BA_ "SPN" SG_ 2364747006 Module30OperationalStatus 17354;
BA_ "SigType" SG_ 2364747006 Module29OperationalStatus 5;
BA_ "SPN" SG_ 2364747006 Module29OperationalStatus 17353;
BA_ "SigType" SG_ 2364747006 Module28OperationalStatus 5;
BA_ "SPN" SG_ 2364747006 Module28OperationalStatus 17352;
BA_ "SigType" SG_ 2364747006 Module27OperationalStatus 5;
BA_ "SPN" SG_ 2364747006 Module27OperationalStatus 17351;
BA_ "SigType" SG_ 2364747006 Module26OperationalStatus 5;
BA_ "SPN" SG_ 2364747006 Module26OperationalStatus 17350;
BA_ "SigType" SG_ 2364747006 Module25OperationalStatus 5;
BA_ "SPN" SG_ 2364747006 Module25OperationalStatus 17349;
BA_ "SigType" SG_ 2364747006 Module24OperationalStatus 5;
BA_ "SPN" SG_ 2364747006 Module24OperationalStatus 17348;
BA_ "SigType" SG_ 2364747006 Module23OperationalStatus 5;
BA_ "SPN" SG_ 2364747006 Module23OperationalStatus 17347;
BA_ "SigType" SG_ 2364747006 Module22OperationalStatus 5;
BA_ "SPN" SG_ 2364747006 Module22OperationalStatus 17346;
BA_ "SigType" SG_ 2364747006 Module21OperationalStatus 5;
BA_ "SPN" SG_ 2364747006 Module21OperationalStatus 17345;
BA_ "SigType" SG_ 2364747006 Module20OperationalStatus 5;
BA_ "SPN" SG_ 2364747006 Module20OperationalStatus 17344;
BA_ "SigType" SG_ 2364747006 Module19OperationalStatus 5;
BA_ "SPN" SG_ 2364747006 Module19OperationalStatus 17343;
BA_ "SigType" SG_ 2364747006 Module18OperationalStatus 5;
BA_ "SPN" SG_ 2364747006 Module18OperationalStatus 17342;
BA_ "SigType" SG_ 2364747006 Module17OperationalStatus 5;
BA_ "SPN" SG_ 2364747006 Module17OperationalStatus 17341;
BA_ "SigType" SG_ 2364747006 Module16OperationalStatus 5;
BA_ "SPN" SG_ 2364747006 Module16OperationalStatus 17340;
BA_ "SigType" SG_ 2364747006 Module15OperationalStatus 5;
BA_ "SPN" SG_ 2364747006 Module15OperationalStatus 17339;
BA_ "SigType" SG_ 2364747006 Module14OperationalStatus 5;
BA_ "SPN" SG_ 2364747006 Module14OperationalStatus 17338;
BA_ "SigType" SG_ 2364747006 Module13OperationalStatus 5;
BA_ "SPN" SG_ 2364747006 Module13OperationalStatus 17337;
BA_ "SigType" SG_ 2364747006 Module12OperationalStatus 5;
BA_ "SPN" SG_ 2364747006 Module12OperationalStatus 17336;
BA_ "SigType" SG_ 2364747006 Module11OperationalStatus 5;
BA_ "SPN" SG_ 2364747006 Module11OperationalStatus 17335;
BA_ "SigType" SG_ 2364747006 Module10OperationalStatus 5;
BA_ "SPN" SG_ 2364747006 Module10OperationalStatus 17334;
BA_ "SigType" SG_ 2364747006 Module9OperationalStatus 5;
BA_ "SPN" SG_ 2364747006 Module9OperationalStatus 17333;
BA_ "SigType" SG_ 2364747006 Module8OperationalStatus 5;
BA_ "SPN" SG_ 2364747006 Module8OperationalStatus 17332;
BA_ "SigType" SG_ 2364747006 Module7OperationalStatus 5;
BA_ "SPN" SG_ 2364747006 Module7OperationalStatus 17331;
BA_ "SigType" SG_ 2364747006 Module6OperationalStatus 5;
BA_ "SPN" SG_ 2364747006 Module6OperationalStatus 17330;
BA_ "SigType" SG_ 2364747006 Module5OperationalStatus 5;
BA_ "SPN" SG_ 2364747006 Module5OperationalStatus 17329;
BA_ "SigType" SG_ 2364747006 Module4OperationalStatus 5;
BA_ "SPN" SG_ 2364747006 Module4OperationalStatus 17328;
BA_ "SigType" SG_ 2364747006 Module3OperationalStatus 5;
BA_ "SPN" SG_ 2364747006 Module3OperationalStatus 17327;
BA_ "SigType" SG_ 2364747006 Module2OperationalStatus 5;
BA_ "SPN" SG_ 2364747006 Module2OperationalStatus 17326;
BA_ "SigType" SG_ 2364747006 Module1OperationalStatus 5;
BA_ "SPN" SG_ 2364747006 Module1OperationalStatus 17325;
BA_ "SigType" SG_ 2364746750 MaxChargeVLmt 1;
BA_ "SPN" SG_ 2364746750 MaxChargeVLmt 17324;
BA_ "SPN" SG_ 2364746750 ChargeEnergyCapacity 17323;
BA_ "SPN" SG_ 2364746750 DisEnergyCapacity 17322;
BA_ "SigType" SG_ 2364746494 Status1CRC 12;
BA_ "SPN" SG_ 2364746494 Status1CRC 17321;
BA_ "SigType" SG_ 2364746494 Status1Counter 11;
BA_ "SPN" SG_ 2364746494 Status1Counter 17320;
BA_ "SPN" SG_ 2364746494 OperationalStatus 17319;
BA_ "SPN" SG_ 2364746494 HVBusConnectionStatus 17318;
BA_ "SigType" SG_ 2364746494 InternalChargerStatus 5;
BA_ "SPN" SG_ 2364746494 InternalChargerStatus 17317;
BA_ "SigType" SG_ 2364746494 CellBalancingActive 4;
BA_ "SPN" SG_ 2364746494 CellBalancingActive 17316;
BA_ "SigType" SG_ 2364746494 CellBalanceStatus 4;
BA_ "SPN" SG_ 2364746494 CellBalanceStatus 17315;
BA_ "SPN" SG_ 2364746494 StOfChargeStatus 17314;
BA_ "SigType" SG_ 2364746494 InertiaSwStatus 4;
BA_ "SPN" SG_ 2364746494 InertiaSwStatus 17313;
BA_ "SigType" SG_ 2364746494 HVILStatus 4;
BA_ "SPN" SG_ 2364746494 HVILStatus 17312;
BA_ "SPN" SG_ 2364746494 HVBusPassiveIsolTestStatus 17311;
BA_ "SPN" SG_ 2364746494 HVBusActiveIsolTestStatus 17310;
BA_ "SigType" SG_ 2364746494 CenterOfPackContactorSt 4;
BA_ "SPN" SG_ 2364746494 CenterOfPackContactorSt 17309;
BA_ "SigType" SG_ 2364746494 HVBusPreChargeRelaySt 4;
BA_ "SPN" SG_ 2364746494 HVBusPreChargeRelaySt 17308;
BA_ "SPN" SG_ 2364746494 HVBusDisconnectForewarning 17307;
BA_ "SigType" SG_ 2364746494 HVBusContactorSt17306 4;
BA_ "SPN" SG_ 2364746494 HVBusContactorSt17306 17306;
BA_ "SigType" SG_ 2364746494 HVBusContactorSt 4;
BA_ "SPN" SG_ 2364746494 HVBusContactorSt 17305;
BA_ "SigType" SG_ 2364746238 Temp 1;
BA_ "SPN" SG_ 2364746238 Temp 17304;
BA_ "SigType" SG_ 2364746238 ETemp 1;
BA_ "SPN" SG_ 2364746238 ETemp 17303;
BA_ "SigType" SG_ 2364746238 OutCoolantTemp 1;
BA_ "SPN" SG_ 2364746238 OutCoolantTemp 17302;
BA_ "SigType" SG_ 2364746238 InCoolantTemp 1;
BA_ "SPN" SG_ 2364746238 InCoolantTemp 17301;
BA_ "SigType" SG_ 2364746238 IgntV 1;
BA_ "SPN" SG_ 2364746238 IgntV 17300;
BA_ "SigType" SG_ 2364746238 BusV 1;
BA_ "SPN" SG_ 2364746238 BusV 17299;
BA_ "SigType" SG_ 2364745982 HighestCellStOfCharge 1;
BA_ "SPN" SG_ 2364745982 HighestCellStOfCharge 17298;
BA_ "SigType" SG_ 2364745982 LowestCellStOfCharge 1;
BA_ "SPN" SG_ 2364745982 LowestCellStOfCharge 17297;
BA_ "SigType" SG_ 2364745982 ChargeCurLmt 1;
BA_ "GenSigStartValue" SG_ 2364745982 ChargeCurLmt 32000;
BA_ "SPN" SG_ 2364745982 ChargeCurLmt 17296;
BA_ "SigType" SG_ 2364745982 DisCurLmt 1;
BA_ "SPN" SG_ 2364745982 DisCurLmt 17295;
BA_ "SigType" SG_ 2364745726 CellBalancingCount 1;
BA_ "SPN" SG_ 2364745726 CellBalancingCount 17294;
BA_ "SigType" SG_ 2364745726 ChargeCapacity 1;
BA_ "SPN" SG_ 2364745726 ChargeCapacity 17293;
BA_ "SigType" SG_ 2364745726 DisCapacity 1;
BA_ "SPN" SG_ 2364745726 DisCapacity 17292;
BA_ "SigType" SG_ 2364745470 CellTempDiffStatus 4;
BA_ "SPN" SG_ 2364745470 CellTempDiffStatus 17291;
BA_ "SigType" SG_ 2364745470 AvgCellTemp 1;
BA_ "SPN" SG_ 2364745470 AvgCellTemp 17290;
BA_ "SigType" SG_ 2364745470 LowestCellTemp 1;
BA_ "SPN" SG_ 2364745470 LowestCellTemp 17289;
BA_ "SigType" SG_ 2364745470 HighestCellTemp 1;
BA_ "SPN" SG_ 2364745470 HighestCellTemp 17288;
BA_ "SPN" SG_ 2364745214 CellVDiffStatus 17287;
BA_ "SigType" SG_ 2364745214 LowestCellV 1;
BA_ "SPN" SG_ 2364745214 LowestCellV 17286;
BA_ "SigType" SG_ 2364745214 HighestCellV 1;
BA_ "SPN" SG_ 2364745214 HighestCellV 17285;
BA_ "SigType" SG_ 2364745214 FastUpdateStOfCharge 1;
BA_ "SPN" SG_ 2364745214 FastUpdateStOfCharge 17284;
BA_ "SigType" SG_ 2364744958 Cur 1;
BA_ "SPN" SG_ 2364744958 Cur 17283;
BA_ "SigType" SG_ 2364744958 Lvl 1;
BA_ "SPN" SG_ 2364744958 Lvl 17282;
BA_ "SigType" SG_ 2364744958 AvailableChargePwr 1;
BA_ "SPN" SG_ 2364744958 AvailableChargePwr 17281;
BA_ "SigType" SG_ 2364744958 AvailableDisPwr 1;
BA_ "SPN" SG_ 2364744958 AvailableDisPwr 17280;
BA_ "SigType" SG_ 2364744702 ChargePLDueToAnUndefinedCause 4;
BA_ "SPN" SG_ 2364744702 ChargePLDueToAnUndefinedCause 17279;
BA_ "SigType" SG_ 2364744702 ChargePLDueToBatCur 4;
BA_ "SPN" SG_ 2364744702 ChargePLDueToBatCur 17278;
BA_ "SigType" SG_ 2364744702 ChargePLDueToBatOrCellV 4;
BA_ "SPN" SG_ 2364744702 ChargePLDueToBatOrCellV 17277;
BA_ "SigType" SG_ 2364744702 ChargePLDueToBatDiagCondition 4;
BA_ "SPN" SG_ 2364744702 ChargePLDueToBatDiagCondition 17276;
BA_ "SigType" SG_ 2364744702 ChargePLDueToBatTemp 4;
BA_ "SPN" SG_ 2364744702 ChargePLDueToBatTemp 17275;
BA_ "SigType" SG_ 2364744702 ChargePLDueToStOfCharge 4;
BA_ "SPN" SG_ 2364744702 ChargePLDueToStOfCharge 17274;
BA_ "SigType" SG_ 2364744702 DisPLDueToAnUndefinedCause 4;
BA_ "SPN" SG_ 2364744702 DisPLDueToAnUndefinedCause 17273;
BA_ "SigType" SG_ 2364744702 DisPLDueToBatCur 4;
BA_ "SPN" SG_ 2364744702 DisPLDueToBatCur 17272;
BA_ "SigType" SG_ 2364744702 DisPLDueToBatOrCellV 4;
BA_ "SPN" SG_ 2364744702 DisPLDueToBatOrCellV 17271;
BA_ "SigType" SG_ 2364744702 DisPLDueToBatDiagCondition 4;
BA_ "SPN" SG_ 2364744702 DisPLDueToBatDiagCondition 17270;
BA_ "SigType" SG_ 2364744702 DisPLDueToBatTemp 4;
BA_ "SPN" SG_ 2364744702 DisPLDueToBatTemp 17269;
BA_ "SigType" SG_ 2364744702 DisPLDueToStOfCharge 4;
BA_ "SPN" SG_ 2364744702 DisPLDueToStOfCharge 17268;
BA_ "SigType" SG_ 2364744446 ActualChargeRate 1;
BA_ "SPN" SG_ 2364744446 ActualChargeRate 17240;
BA_ "SigType" SG_ 2364744446 LvlNegToChassisGroundV 1;
BA_ "SPN" SG_ 2364744446 LvlNegToChassisGroundV 17239;
BA_ "SigType" SG_ 2364744446 BusVNegToChassisGroundV 1;
BA_ "SPN" SG_ 2364744446 BusVNegToChassisGroundV 17238;
BA_ "SigType" SG_ 2364744190 HVBusPassiveIsolTestResults 1;
BA_ "SPN" SG_ 2364744190 HVBusPassiveIsolTestResults 17237;
BA_ "SigType" SG_ 2364744190 HVBusActiveIsolTestResults 1;
BA_ "SPN" SG_ 2364744190 HVBusActiveIsolTestResults 17236;
BA_ "SigType" SG_ 2364744190 LowestCellStOfChargeCellNum 1;
BA_ "SPN" SG_ 2364744190 LowestCellStOfChargeCellNum 17235;
BA_ "SigType" SG_ 2364744190 LowestCellStOfChargeModuleNum 1;
BA_ "SPN" SG_ 2364744190 LowestCellStOfChargeModuleNum 17234;
BA_ "SigType" SG_ 2364744190 HighestCellStOfChargeCellNum 1;
BA_ "SPN" SG_ 2364744190 HighestCellStOfChargeCellNum 17233;
BA_ "SigType" SG_ 2364744190 HighestCellStOfChargeModuleNum 1;
BA_ "SPN" SG_ 2364744190 HighestCellStOfChargeModuleNum 17232;
VAL_ 2566544382 ErrorCode 15 "Not available" 14 "No Data" 13 "Charging system not compatible" 12 "Reserved" 11 "Reserved" 10 "Reserved" 9 "Reserved" 8 "Reserved" 7 "Reserved" 6 "Charging Voltage Out of Range" 5 "Charging Current differential" 4 "Vehicle charging system fault" 3 "Connector Lock fault" 2 "Shift Position " 1 "Battery Temperature too hot/cold" 0 "No Error" ;
VAL_ 2566544382 RESSConditioningFlag 3 "Not available" 2 "Reserved" 1 "Battery conditioning active" 0 "Battery conditioning not active" ;
VAL_ 2566544382 CabinConditioningFlag 3 "Not available" 2 "Reserved" 1 "Cabin conditioning active" 0 "Cabin conditioning not active" ;
VAL_ 2566544126 HeatingCircPumpCtrl 3 "Don't care / take no action" 2 "Reserved" 1 "On" 0 "Off" ;
VAL_ 2566544126 HeatingCircDiffPressSwStatus 3 "Not Available" 2 "Error" 1 "Not OK" 0 "OK" ;
VAL_ 2566542334 FanSt 3 "Not available" 2 "Error" 1 "Active" 0 "Inactive" ;
VAL_ 2566542078 Fan8Status 3 "Not available" 2 "Error" 1 "Active" 0 "Inactive" ;
VAL_ 2566542078 Fan7Status 3 "Not available" 2 "Error" 1 "Active" 0 "Inactive" ;
VAL_ 2566542078 Fan6Status 3 "Not available" 2 "Error" 1 "Active" 0 "Inactive" ;
VAL_ 2566542078 Fan5Status 3 "Not available" 2 "Error" 1 "Active" 0 "Inactive" ;
VAL_ 2566542078 Fan4Status 3 "Not available" 2 "Error" 1 "Active" 0 "Inactive" ;
VAL_ 2566542078 Fan3Status 3 "Not available" 2 "Error" 1 "Active" 0 "Inactive" ;
VAL_ 2566542078 Fan2Status 3 "Not available" 2 "Error" 1 "Active" 0 "Inactive" ;
VAL_ 2566542078 Fan1Status 3 "Not available" 2 "Error" 1 "Active" 0 "Inactive" ;
VAL_ 2566541822 TempCtrlSelectionSt 3 "Not Available" 2 "Error" 1 "Engine Radiator 2 Control Temperature" 0 "Engine Radiator 1 Control Temperature" ;
VAL_ 2566541822 Fan8Status 3 "Not available" 2 "Error" 1 "Active" 0 "Inactive" ;
VAL_ 2566541822 Fan7Status 3 "Not available" 2 "Error" 1 "Active" 0 "Inactive" ;
VAL_ 2566541822 Fan6Status 3 "Not available" 2 "Error" 1 "Active" 0 "Inactive" ;
VAL_ 2566541822 Fan5Status 3 "Not available" 2 "Error" 1 "Active" 0 "Inactive" ;
VAL_ 2566541822 Fan4Status 3 "Not available" 2 "Error" 1 "Active" 0 "Inactive" ;
VAL_ 2566541822 Fan3Status 3 "Not available" 2 "Error" 1 "Active" 0 "Inactive" ;
VAL_ 2566541822 Fan2Status 3 "Not available" 2 "Error" 1 "Active" 0 "Inactive" ;
VAL_ 2566541822 Fan1Status 3 "Not available" 2 "Error" 1 "Active" 0 "Inactive" ;
VAL_ 2566541566 SepCPCtrl 3 "Unavailable" 2 "Reserved" 1 "On" 0 "Off" ;
VAL_ 2566541566 SepCoolantDiffPressSwStatus 3 "Not Available" 2 "Error" 1 "Not OK" 0 "OK" ;
VAL_ 2566541310 EmbeddedIntegritySupport 3 "ADSC3 CRC and Counter are not supported by the sender" 2 "Reserved" 1 "ADSC3 protection is supported using J1939-76 SHM" 0 "ADSC3 embedded CRC and Counter are supported by the sender" ;
VAL_ 2566541310 OpStatus 7 "Not available" 6 "Reserved" 5 "Reserved" 4 "Reserved" 3 "ADS Not Ready" 2 "ADS Automated Mode" 1 "ADS Automated Mode with Operator Override Capability" 0 "ADS Manual Mode" ;
VAL_ 2566541054 CpntDiagAndMtCap 7 "Not Available" 6 "Error" 5 "Reserved" 4 "Reserved" 3 "Controller application has a most severe reduced diagnostic or mitigation capability" 2 "Controller application has a moderately severe reduced diagnostic or mitigation capability" 1 "Controller application has a least severe reduced diagnostic or mitigation capability" 0 "Controller application has full diagnostic and mitigation capability" ;
VAL_ 2566541054 Ctrl4CommunicationSt 7 "Not Available" 6 "Error" 5 "Not Identified" 4 "Reserved" 3 "Reserved" 2 "Reserved" 1 "Active" 0 "System is not ready" ;
VAL_ 2566541054 Ctrl3CommunicationSt 7 "Not Available" 6 "Error" 5 "Not Identified" 4 "Reserved" 3 "Reserved" 2 "Reserved" 1 "Active" 0 "System is not ready" ;
VAL_ 2566541054 Ctrl2CommunicationSt 7 "Not Available" 6 "Error" 5 "Not Identified" 4 "Reserved" 3 "Reserved" 2 "Reserved" 1 "Active" 0 "System is not ready" ;
VAL_ 2566541054 Ctrl1CommunicationSt 7 "Not Available" 6 "Error" 5 "Not Identified" 4 "Reserved" 3 "Reserved" 2 "Reserved" 1 "Active" 0 "System is not ready" ;
VAL_ 2566541054 AutomatedModeSupport 3 "Not Available" 2 "Reserved" 1 "Enabled" 0 "Disabled" ;
VAL_ 2566541054 AutomatedModeWithOpOvrdSupport 3 "Not Available" 2 "Reserved" 1 "Enabled" 0 "Disabled" ;
VAL_ 2566541054 OpStatusAcknowledgement 7 "Not available" 6 "Reserved" 5 "Reserved" 4 "Reserved" 3 "SPN 20870 has not been received with an ADS mode" 2 "ADS Automated Mode" 1 "ADS Automated Mode with Operator Override Capability" 0 "ADS Manual Mode" ;
VAL_ 2364752638 AbsSteerPosQualityFactor 3 "Not Available" 2 "Error" 1 "Absolute steering position valid" 0 "Absolute steering position invalid" ;
VAL_ 2364752638 IgntPwr 3 "Not Available" 2 "Error" 1 "Active steering ignition power is active" 0 "Active steering ignition power is not active" ;
VAL_ 2364752638 ReqMode 15 "Not Available" 14 "Signal Error" 13 "Reserved" 12 "Reserved" 11 "Reserved" 10 "Reserved" 9 "Reserved" 8 "Reserved" 7 "Reserved" 6 "Reserved" 5 "Torque Control Driver Override" 4 "Torque Control with Driver Override" 3 "No Motor Control" 2 "Steering Position Control without Driverride" 1 "Steering Position Control with Driver Override" 0 "External Request Disabled" ;
VAL_ 2364752638 ErrorType 15 "Not Available" 14 "Signal Error" 13 "Reserved" 12 "Reserved" 11 "Reserved" 10 "Reserved" 9 "Reserved" 8 "Message Checksum Error" 7 "Message Counter Error" 6 "Misalignment Error" 5 "Command Mismatch Error" 4 "Mechnical Linkage Error" 3 "Internal Unit Error" 2 "Redundant Communication Error" 1 "External Request Missing" 0 "No Error" ;
VAL_ 2364752638 St 15 "Not Available" 14 "Error" 13 "Reserved" 12 "Reserved" 11 "Reserved" 10 "Reserved" 9 "Reserved" 8 "Reserved" 7 "Reserved" 6 "Reserved" 5 "Reserved" 4 "System Malfunction, Redundant" 3 "System Malfunction, Main" 2 "System is ready" 1 "System is temporarily not available" 0 "System is not ready" ;
VAL_ 2364752638 ActualMode 15 "Not Available" 14 "Signal Error" 13 "Reserved" 12 "Reserved" 11 "Reserved" 10 "Reserved" 9 "Reserved" 8 "Reserved" 7 "Reserved" 6 "Reserved" 5 "Torque Control Driver Override" 4 "Torque Control with Driver Override" 3 "No Motor Control" 2 "Steering Position Control without Driverride" 1 "Steering Position Control with Driver Override" 0 "External Request Disabled" ;
VAL_ 2297643518 Priority 15 "Not Available" 14 "Signal Error" 13 "Reserved" 12 "Reserved" 11 "Reserved" 10 "Reserved" 9 "Reserved" 8 "Reserved" 7 "Reserved" 6 "Reserved" 5 "Reserved" 4 "Reserved" 3 "Priority 4" 2 "Priority 3" 1 "Priority 2" 0 "Priority 1" ;
VAL_ 2297643518 OperatingMode 15 "Not Available" 14 "Signal Error" 13 "Reserved" 12 "Reserved" 11 "Reserved" 10 "Reserved" 9 "Reserved" 8 "Reserved" 7 "Reserved" 6 "Reserved" 5 "Torque Control Driver Override" 4 "Torque Control with Driver Override" 3 "No Motor Control" 2 "Steering Position Control without Driverride" 1 "Steering Position Control with Driver Override" 0 "External Request Disabled" ;
VAL_ 2364751614 Data9EmbeddedIntegritySupport 3 "CRC and Counter are not supported by the sender" 2 "Reserved" 1 "Protection is supported using J1939-76 SHM" 0 "Embedded CRC and Counter are supported by the sender" ;
VAL_ 2364751614 HVESS26ThermalEventDetected 3 "Not available" 2 "Error" 1 "Thermal Event Detected" 0 "No Thermal Event Detected" ;
VAL_ 2364751102 TMSCoolantLvl 3 "Not Available" 2 "Error" 1 "Coolant Level is sufficient" 0 "Coolant Level is not sufficient" ;
VAL_ 2364751102 TMSMode 15 "Not Available" 14 "Faulted" 13 "Reserved" 12 "Reserved" 11 "Reserved" 10 "Reserved" 9 "Reserved" 8 "Reserved" 7 "Reserved" 6 "Reserved" 5 "Maintaining" 4 "Drying" 3 "Heating" 2 "Cooling" 1 "Circulating" 0 "Off" ;
VAL_ 2364751102 TMSHVILStatus 3 "Not Available" 2 "Error" 1 "HVIL Open" 0 "HVIL Closed" ;
VAL_ 2364751102 TMSHtrStatus 3 "Not Available" 2 "Error" 1 "Heater On" 0 "Heater Off" ;
VAL_ 2364750846 Module32OperationalStatus 3 "Not Available" 2 "Error" 1 "Operational" 0 "Not Operational" ;
VAL_ 2364750846 Module31OperationalStatus 3 "Not Available" 2 "Error" 1 "Operational" 0 "Not Operational" ;
VAL_ 2364750846 Module30OperationalStatus 3 "Not Available" 2 "Error" 1 "Operational" 0 "Not Operational" ;
VAL_ 2364750846 Module29OperationalStatus 3 "Not Available" 2 "Error" 1 "Operational" 0 "Not Operational" ;
VAL_ 2364750846 Module28OperationalStatus 3 "Not Available" 2 "Error" 1 "Operational" 0 "Not Operational" ;
VAL_ 2364750846 Module27OperationalStatus 3 "Not Available" 2 "Error" 1 "Operational" 0 "Not Operational" ;
VAL_ 2364750846 Module26OperationalStatus 3 "Not Available" 2 "Error" 1 "Operational" 0 "Not Operational" ;
VAL_ 2364750846 Module25OperationalStatus 3 "Not Available" 2 "Error" 1 "Operational" 0 "Not Operational" ;
VAL_ 2364750846 Module24OperationalStatus 3 "Not Available" 2 "Error" 1 "Operational" 0 "Not Operational" ;
VAL_ 2364750846 Module23OperationalStatus 3 "Not Available" 2 "Error" 1 "Operational" 0 "Not Operational" ;
VAL_ 2364750846 Module22OperationalStatus 3 "Not Available" 2 "Error" 1 "Operational" 0 "Not Operational" ;
VAL_ 2364750846 Module21OperationalStatus 3 "Not Available" 2 "Error" 1 "Operational" 0 "Not Operational" ;
VAL_ 2364750846 Module20OperationalStatus 3 "Not Available" 2 "Error" 1 "Operational" 0 "Not Operational" ;
VAL_ 2364750846 Module19OperationalStatus 3 "Not Available" 2 "Error" 1 "Operational" 0 "Not Operational" ;
VAL_ 2364750846 Module18OperationalStatus 3 "Not Available" 2 "Error" 1 "Operational" 0 "Not Operational" ;
VAL_ 2364750846 Module17OperationalStatus 3 "Not Available" 2 "Error" 1 "Operational" 0 "Not Operational" ;
VAL_ 2364750846 Module16OperationalStatus 3 "Not Available" 2 "Error" 1 "Operational" 0 "Not Operational" ;
VAL_ 2364750846 Module15OperationalStatus 3 "Not Available" 2 "Error" 1 "Operational" 0 "Not Operational" ;
VAL_ 2364750846 Module14OperationalStatus 3 "Not Available" 2 "Error" 1 "Operational" 0 "Not Operational" ;
VAL_ 2364750846 Module13OperationalStatus 3 "Not Available" 2 "Error" 1 "Operational" 0 "Not Operational" ;
VAL_ 2364750846 Module12OperationalStatus 3 "Not Available" 2 "Error" 1 "Operational" 0 "Not Operational" ;
VAL_ 2364750846 Module11OperationalStatus 3 "Not Available" 2 "Error" 1 "Operational" 0 "Not Operational" ;
VAL_ 2364750846 Module10OperationalStatus 3 "Not Available" 2 "Error" 1 "Operational" 0 "Not Operational" ;
VAL_ 2364750846 Module9OperationalStatus 3 "Not Available" 2 "Error" 1 "Operational" 0 "Not Operational" ;
VAL_ 2364750846 Module8OperationalStatus 3 "Not Available" 2 "Error" 1 "Operational" 0 "Not Operational" ;
VAL_ 2364750846 Module7OperationalStatus 3 "Not Available" 2 "Error" 1 "Operational" 0 "Not Operational" ;
VAL_ 2364750846 Module6OperationalStatus 3 "Not Available" 2 "Error" 1 "Operational" 0 "Not Operational" ;
VAL_ 2364750846 Module5OperationalStatus 3 "Not Available" 2 "Error" 1 "Operational" 0 "Not Operational" ;
VAL_ 2364750846 Module4OperationalStatus 3 "Not Available" 2 "Error" 1 "Operational" 0 "Not Operational" ;
VAL_ 2364750846 Module3OperationalStatus 3 "Not Available" 2 "Error" 1 "Operational" 0 "Not Operational" ;
VAL_ 2364750846 Module2OperationalStatus 3 "Not Available" 2 "Error" 1 "Operational" 0 "Not Operational" ;
VAL_ 2364750846 Module1OperationalStatus 3 "Not Available" 2 "Error" 1 "Operational" 0 "Not Operational" ;
VAL_ 2364750334 OperationalStatus 15 "Not Available" 14 "Error" 13 "Reserved" 12 "Reserved" 11 "Reserved" 10 "Reserved" 9 "Reserved" 8 "Reserved" 7 "Reserved" 6 "Disabled by internal decision of HVES controller" 5 "Disabled by external command" 4 "Emergency Power-Down In Process" 3 "Normal Power-Down in Process" 2 "Operational." 1 "Initialization Complete" 0 "Initialization in process" ;
VAL_ 2364750334 HVBusConnectionStatus 15 "Not Available" 14 "Error" 13 "Reserved" 12 "Reserved" 11 "Reserved" 10 "Reserved" 9 "Reserved" 8 "Reserved" 7 "Reserved" 6 "Reserved" 5 "Reserved" 4 "Disconnected,  Precharge Failed" 3 "Disconnection in Process" 2 "Connection in Process" 1 "Connected" 0 "Disconnected, One or more contactors are open" ;
VAL_ 2364750334 InternalChargerStatus 3 "Not Available" 2 "Error" 1 "Charging on" 0 "Charging off" ;
VAL_ 2364750334 CellBalancingActive 3 "Not Available" 2 "Error" 1 "Cell balancing is active" 0 "Cell balancing is not active" ;
VAL_ 2364750334 CellBalanceStatus 3 "Not Available" 2 "Error" 1 "Cells are unbalanced" 0 "Cells are balanced" ;
VAL_ 2364750334 StOfChargeStatus 15 "Not  Available" 14 "Error" 13 "Reserved" 12 "Reserved" 11 "Reserved" 10 "Reserved" 9 "Reserved" 8 "Reserved" 7 "Reserved" 6 "SOC is above its recommended upper limit" 5 "SOC is at its recommended upper limit" 4 "SOC is approaching its recommended upper limit" 3 "SOC is below its recommended lower limit" 2 "SOC is at its recommended lower limit" 1 "SOC is approaching its recommended lower limit" 0 "SOC level is acceptable" ;
VAL_ 2364750334 InertiaSwStatus 3 "Not Available" 2 "Error" 1 "Impact sensed" 0 "No impact sensed" ;
VAL_ 2364750334 HVILStatus 3 "Not Available" 2 "Error" 1 "HVIL Open" 0 "HVIL Closed" ;
VAL_ 2364750334 HVBusPassiveIsolTestStatus 15 "Not available" 14 "Error" 13 "Reserved" 12 "Reserved" 11 "Reserved" 10 "Reserved" 9 "Reserved" 8 "Reserved" 7 "Reserved" 6 "Reserved" 5 "Test complete,  isolation fault" 4 "Test complete,  isolation marginal" 3 "Test complete,  isolation acceptable" 2 "Test in process" 1 "Test requested but not yet in process" 0 "No test requested / No test in process" ;
VAL_ 2364750334 HVBusActiveIsolTestStatus 15 "Not available" 14 "Error" 13 "Reserved" 12 "Reserved" 11 "Reserved" 10 "Reserved" 9 "Reserved" 8 "Reserved" 7 "Reserved" 6 "Reserved" 5 "Test complete,  isolation fault" 4 "Test complete,  isolation marginal" 3 "Test complete,  isolation acceptable" 2 "Test in process" 1 "Test requested but not yet in process" 0 "No test requested / No test in process" ;
VAL_ 2364750334 CenterOfPackContactorSt 3 "Not Available" 2 "Error" 1 "Contactor Closed" 0 "Contactor Open" ;
VAL_ 2364750334 HVBusPreChargeRelaySt 3 "Not Available" 2 "Error" 1 "Relay Closed" 0 "Relay Open" ;
VAL_ 2364750334 HVBusDisconnectForewarning 15 "Not Available" 14 "Error" 13 "Disconnect imminent" 12 "Reserved" 11 "Reserved" 10 "Reserved" 9 "Reserved" 8 "Reserved" 7 "Disconnect imminent due to battery pack current approaching maximum acceptable level" 6 "Disconnect imminent due to cell voltage approaching maximum acceptable level" 5 "Disconnect imminent due to cell voltage approaching minimum acceptable level" 4 "Disconnect imminent due to module voltage approaching maximum acceptable level" 3 "Disconnect imminent due to module voltage approaching minimum acceptable level" 2 "Disconnect imminent due to battery pack voltage approaching maximum acceptable level" 1 "Disconnect imminent due to battery pack voltage approaching minimum acceptable level" 0 "Disconnect not pending" ;
VAL_ 2364750334 HVBusContactorSt17448 3 "Not Available" 2 "Error" 1 "Contactor Closed" 0 "Contactor Open" ;
VAL_ 2364750334 HVBusContactorSt 3 "Not Available" 2 "Error" 1 "Contactor Closed" 0 "Contactor Open" ;
VAL_ 2364749310 CellTempDiffStatus 3 "Not Available" 2 "Error" 1 "Cell-to-cell temperature differential exceeds acceptable limits" 0 "Cell-to-cell temperature differential is within acceptable limits" ;
VAL_ 2364749054 CellVDiffStatus 15 "Not Available" 14 "Error" 13 "Reserved" 12 "Reserved" 11 "Reserved" 10 "Reserved" 9 "Reserved" 8 "Reserved" 7 "Reserved" 6 "Reserved" 5 "Reserved" 4 "Exceeds limits and it is not known whether balancing can restore performance" 3 "Exceeds limits and external maintenance balancing cannot restore performance" 2 "Exceeds limits and external maintenance balancing is required" 1 "Exceeds limits and can be corrected via auto-balancing" 0 "Is within acceptable limits" ;
VAL_ 2364748542 ChargePLDueToAnUndefinedCause 3 "Not Available" 2 "Error" 1 "Power limited for this reason" 0 "No power limit for this reason" ;
VAL_ 2364748542 ChargePLDueToBatCur 3 "Not Available" 2 "Error" 1 "Power limited for this reason" 0 "No power limit for this reason" ;
VAL_ 2364748542 ChargePLDueToBatOrCellV 3 "Not Available" 2 "Error" 1 "Power limited for this reason" 0 "No power limit for this reason" ;
VAL_ 2364748542 ChargePLDueToBatDiagCondition 3 "Not Available" 2 "Error" 1 "Power limited for this reason" 0 "No power limit for this reason" ;
VAL_ 2364748542 ChargePLDueToBatTemp 3 "Not Available" 2 "Error" 1 "Power limited for this reason" 0 "No power limit for this reason" ;
VAL_ 2364748542 ChargePLDueToStOfCharge 3 "Not Available" 2 "Error" 1 "Power limited for this reason" 0 "No power limit for this reason" ;
VAL_ 2364748542 DisPLDueToAnUndefinedCause 3 "Not Available" 2 "Error" 1 "Power limited for this reason" 0 "No power limit for this reason" ;
VAL_ 2364748542 DisPLDueToBatCur 3 "Not Available" 2 "Error" 1 "Power limited for this reason" 0 "No power limit for this reason" ;
VAL_ 2364748542 DisPLDueToBatOrCellV 3 "Not Available" 2 "Error" 1 "Power limited for this reason" 0 "No power limit for this reason" ;
VAL_ 2364748542 DisPLDueToBatDiagCondition 3 "Not Available" 2 "Error" 1 "Power limited for this reason" 0 "No power limit for this reason" ;
VAL_ 2364748542 DisPLDueToBatTemp 3 "Not Available" 2 "Error" 1 "Power limited for this reason" 0 "No power limit for this reason" ;
VAL_ 2364748542 DisPLDueToStOfCharge 3 "Not Available" 2 "Error" 1 "Power limited for this reason" 0 "No power limit for this reason" ;
VAL_ 2364747774 Data9EmbeddedIntegritySupport 3 "CRC and Counter are not supported by the sender" 2 "Reserved" 1 "Protection is supported using J1939-76 SHM" 0 "Embedded CRC and Counter are supported by the sender" ;
VAL_ 2364747774 HVESS25ThermalEventDetected 3 "Not available" 2 "Error" 1 "Thermal Event Detected" 0 "No Thermal Event Detected" ;
VAL_ 2364747262 TMSCoolantLvl 3 "Not Available" 2 "Error" 1 "Coolant Level is sufficient" 0 "Coolant Level is not sufficient" ;
VAL_ 2364747262 TMSMode 15 "Not Available" 14 "Faulted" 13 "Reserved" 12 "Reserved" 11 "Reserved" 10 "Reserved" 9 "Reserved" 8 "Reserved" 7 "Reserved" 6 "Reserved" 5 "Maintaining" 4 "Drying" 3 "Heating" 2 "Cooling" 1 "Circulating" 0 "Off" ;
VAL_ 2364747262 TMSHVILStatus 3 "Not Available" 2 "Error" 1 "HVIL Open" 0 "HVIL Closed" ;
VAL_ 2364747262 TMSHtrStatus 3 "Not Available" 2 "Error" 1 "Heater On" 0 "Heater Off" ;
VAL_ 2364747006 Module32OperationalStatus 3 "Not Available" 2 "Error" 1 "Operational" 0 "Not Operational" ;
VAL_ 2364747006 Module31OperationalStatus 3 "Not Available" 2 "Error" 1 "Operational" 0 "Not Operational" ;
VAL_ 2364747006 Module30OperationalStatus 3 "Not Available" 2 "Error" 1 "Operational" 0 "Not Operational" ;
VAL_ 2364747006 Module29OperationalStatus 3 "Not Available" 2 "Error" 1 "Operational" 0 "Not Operational" ;
VAL_ 2364747006 Module28OperationalStatus 3 "Not Available" 2 "Error" 1 "Operational" 0 "Not Operational" ;
VAL_ 2364747006 Module27OperationalStatus 3 "Not Available" 2 "Error" 1 "Operational" 0 "Not Operational" ;
VAL_ 2364747006 Module26OperationalStatus 3 "Not Available" 2 "Error" 1 "Operational" 0 "Not Operational" ;
VAL_ 2364747006 Module25OperationalStatus 3 "Not Available" 2 "Error" 1 "Operational" 0 "Not Operational" ;
VAL_ 2364747006 Module24OperationalStatus 3 "Not Available" 2 "Error" 1 "Operational" 0 "Not Operational" ;
VAL_ 2364747006 Module23OperationalStatus 3 "Not Available" 2 "Error" 1 "Operational" 0 "Not Operational" ;
VAL_ 2364747006 Module22OperationalStatus 3 "Not Available" 2 "Error" 1 "Operational" 0 "Not Operational" ;
VAL_ 2364747006 Module21OperationalStatus 3 "Not Available" 2 "Error" 1 "Operational" 0 "Not Operational" ;
VAL_ 2364747006 Module20OperationalStatus 3 "Not Available" 2 "Error" 1 "Operational" 0 "Not Operational" ;
VAL_ 2364747006 Module19OperationalStatus 3 "Not Available" 2 "Error" 1 "Operational" 0 "Not Operational" ;
VAL_ 2364747006 Module18OperationalStatus 3 "Not Available" 2 "Error" 1 "Operational" 0 "Not Operational" ;
VAL_ 2364747006 Module17OperationalStatus 3 "Not Available" 2 "Error" 1 "Operational" 0 "Not Operational" ;
VAL_ 2364747006 Module16OperationalStatus 3 "Not Available" 2 "Error" 1 "Operational" 0 "Not Operational" ;
VAL_ 2364747006 Module15OperationalStatus 3 "Not Available" 2 "Error" 1 "Operational" 0 "Not Operational" ;
VAL_ 2364747006 Module14OperationalStatus 3 "Not Available" 2 "Error" 1 "Operational" 0 "Not Operational" ;
VAL_ 2364747006 Module13OperationalStatus 3 "Not Available" 2 "Error" 1 "Operational" 0 "Not Operational" ;
VAL_ 2364747006 Module12OperationalStatus 3 "Not Available" 2 "Error" 1 "Operational" 0 "Not Operational" ;
VAL_ 2364747006 Module11OperationalStatus 3 "Not Available" 2 "Error" 1 "Operational" 0 "Not Operational" ;
VAL_ 2364747006 Module10OperationalStatus 3 "Not Available" 2 "Error" 1 "Operational" 0 "Not Operational" ;
VAL_ 2364747006 Module9OperationalStatus 3 "Not Available" 2 "Error" 1 "Operational" 0 "Not Operational" ;
VAL_ 2364747006 Module8OperationalStatus 3 "Not Available" 2 "Error" 1 "Operational" 0 "Not Operational" ;
VAL_ 2364747006 Module7OperationalStatus 3 "Not Available" 2 "Error" 1 "Operational" 0 "Not Operational" ;
VAL_ 2364747006 Module6OperationalStatus 3 "Not Available" 2 "Error" 1 "Operational" 0 "Not Operational" ;
VAL_ 2364747006 Module5OperationalStatus 3 "Not Available" 2 "Error" 1 "Operational" 0 "Not Operational" ;
VAL_ 2364747006 Module4OperationalStatus 3 "Not Available" 2 "Error" 1 "Operational" 0 "Not Operational" ;
VAL_ 2364747006 Module3OperationalStatus 3 "Not Available" 2 "Error" 1 "Operational" 0 "Not Operational" ;
VAL_ 2364747006 Module2OperationalStatus 3 "Not Available" 2 "Error" 1 "Operational" 0 "Not Operational" ;
VAL_ 2364747006 Module1OperationalStatus 3 "Not Available" 2 "Error" 1 "Operational" 0 "Not Operational" ;
VAL_ 2364746494 OperationalStatus 15 "Not Available" 14 "Error" 13 "Reserved" 12 "Reserved" 11 "Reserved" 10 "Reserved" 9 "Reserved" 8 "Reserved" 7 "Reserved" 6 "Disabled by internal decision of HVES controller" 5 "Disabled by external command" 4 "Emergency Power-Down In Process" 3 "Normal Power-Down in Process" 2 "Operational." 1 "Initialization Complete" 0 "Initialization in process" ;
VAL_ 2364746494 HVBusConnectionStatus 15 "Not Available" 14 "Error" 13 "Reserved" 12 "Reserved" 11 "Reserved" 10 "Reserved" 9 "Reserved" 8 "Reserved" 7 "Reserved" 6 "Reserved" 5 "Reserved" 4 "Disconnected,  Precharge Failed" 3 "Disconnection in Process" 2 "Connection in Process" 1 "Connected" 0 "Disconnected, One or more contactors are open" ;
VAL_ 2364746494 InternalChargerStatus 3 "Not Available" 2 "Error" 1 "Charging on" 0 "Charging off" ;
VAL_ 2364746494 CellBalancingActive 3 "Not Available" 2 "Error" 1 "Cell balancing is active" 0 "Cell balancing is not active" ;
VAL_ 2364746494 CellBalanceStatus 3 "Not Available" 2 "Error" 1 "Cells are unbalanced" 0 "Cells are balanced" ;
VAL_ 2364746494 StOfChargeStatus 15 "Not  Available" 14 "Error" 13 "Reserved" 12 "Reserved" 11 "Reserved" 10 "Reserved" 9 "Reserved" 8 "Reserved" 7 "Reserved" 6 "SOC is above its recommended upper limit" 5 "SOC is at its recommended upper limit" 4 "SOC is approaching its recommended upper limit" 3 "SOC is below its recommended lower limit" 2 "SOC is at its recommended lower limit" 1 "SOC is approaching its recommended lower limit" 0 "SOC level is acceptable" ;
VAL_ 2364746494 InertiaSwStatus 3 "Not Available" 2 "Error" 1 "Impact sensed" 0 "No impact sensed" ;
VAL_ 2364746494 HVILStatus 3 "Not Available" 2 "Error" 1 "HVIL Open" 0 "HVIL Closed" ;
VAL_ 2364746494 HVBusPassiveIsolTestStatus 15 "Not available" 14 "Error" 13 "Reserved" 12 "Reserved" 11 "Reserved" 10 "Reserved" 9 "Reserved" 8 "Reserved" 7 "Reserved" 6 "Reserved" 5 "Test complete,  isolation fault" 4 "Test complete,  isolation marginal" 3 "Test complete,  isolation acceptable" 2 "Test in process" 1 "Test requested but not yet in process" 0 "No test requested / No test in process" ;
VAL_ 2364746494 HVBusActiveIsolTestStatus 15 "Not available" 14 "Error" 13 "Reserved" 12 "Reserved" 11 "Reserved" 10 "Reserved" 9 "Reserved" 8 "Reserved" 7 "Reserved" 6 "Reserved" 5 "Test complete,  isolation fault" 4 "Test complete,  isolation marginal" 3 "Test complete,  isolation acceptable" 2 "Test in process" 1 "Test requested but not yet in process" 0 "No test requested / No test in process" ;
VAL_ 2364746494 CenterOfPackContactorSt 3 "Not Available" 2 "Error" 1 "Contactor Closed" 0 "Contactor Open" ;
VAL_ 2364746494 HVBusPreChargeRelaySt 3 "Not Available" 2 "Error" 1 "Relay Closed" 0 "Relay Open" ;
VAL_ 2364746494 HVBusDisconnectForewarning 15 "Not Available" 14 "Error" 13 "Disconnect imminent" 12 "Reserved" 11 "Reserved" 10 "Reserved" 9 "Reserved" 8 "Reserved" 7 "Disconnect imminent due to battery pack current approaching maximum acceptable level" 6 "Disconnect imminent due to cell voltage approaching maximum acceptable level" 5 "Disconnect imminent due to cell voltage approaching minimum acceptable level" 4 "Disconnect imminent due to module voltage approaching maximum acceptable level" 3 "Disconnect imminent due to module voltage approaching minimum acceptable level" 2 "Disconnect imminent due to battery pack voltage approaching maximum acceptable level" 1 "Disconnect imminent due to battery pack voltage approaching minimum acceptable level" 0 "Disconnect not pending" ;
VAL_ 2364746494 HVBusContactorSt17306 3 "Not Available" 2 "Error" 1 "Contactor Closed" 0 "Contactor Open" ;
VAL_ 2364746494 HVBusContactorSt 3 "Not Available" 2 "Error" 1 "Contactor Closed" 0 "Contactor Open" ;
VAL_ 2364745470 CellTempDiffStatus 3 "Not Available" 2 "Error" 1 "Cell-to-cell temperature differential exceeds acceptable limits" 0 "Cell-to-cell temperature differential is within acceptable limits" ;
VAL_ 2364745214 CellVDiffStatus 15 "Not Available" 14 "Error" 13 "Reserved" 12 "Reserved" 11 "Reserved" 10 "Reserved" 9 "Reserved" 8 "Reserved" 7 "Reserved" 6 "Reserved" 5 "Reserved" 4 "Exceeds limits and it is not known whether balancing can restore performance" 3 "Exceeds limits and external maintenance balancing cannot restore performance" 2 "Exceeds limits and external maintenance balancing is required" 1 "Exceeds limits and can be corrected via auto-balancing" 0 "Is within acceptable limits" ;
VAL_ 2364744702 ChargePLDueToAnUndefinedCause 3 "Not Available" 2 "Error" 1 "Power limited for this reason" 0 "No power limit for this reason" ;
VAL_ 2364744702 ChargePLDueToBatCur 3 "Not Available" 2 "Error" 1 "Power limited for this reason" 0 "No power limit for this reason" ;
VAL_ 2364744702 ChargePLDueToBatOrCellV 3 "Not Available" 2 "Error" 1 "Power limited for this reason" 0 "No power limit for this reason" ;
VAL_ 2364744702 ChargePLDueToBatDiagCondition 3 "Not Available" 2 "Error" 1 "Power limited for this reason" 0 "No power limit for this reason" ;
VAL_ 2364744702 ChargePLDueToBatTemp 3 "Not Available" 2 "Error" 1 "Power limited for this reason" 0 "No power limit for this reason" ;
VAL_ 2364744702 ChargePLDueToStOfCharge 3 "Not Available" 2 "Error" 1 "Power limited for this reason" 0 "No power limit for this reason" ;
VAL_ 2364744702 DisPLDueToAnUndefinedCause 3 "Not Available" 2 "Error" 1 "Power limited for this reason" 0 "No power limit for this reason" ;
VAL_ 2364744702 DisPLDueToBatCur 3 "Not Available" 2 "Error" 1 "Power limited for this reason" 0 "No power limit for this reason" ;
VAL_ 2364744702 DisPLDueToBatOrCellV 3 "Not Available" 2 "Error" 1 "Power limited for this reason" 0 "No power limit for this reason" ;
VAL_ 2364744702 DisPLDueToBatDiagCondition 3 "Not Available" 2 "Error" 1 "Power limited for this reason" 0 "No power limit for this reason" ;
VAL_ 2364744702 DisPLDueToBatTemp 3 "Not Available" 2 "Error" 1 "Power limited for this reason" 0 "No power limit for this reason" ;
VAL_ 2364744702 DisPLDueToStOfCharge 3 "Not Available" 2 "Error" 1 "Power limited for this reason" 0 "No power limit for this reason" ;
